// *************************************************************************** *
// *                                                                           *
// *                      Mentor Graphics Corporation                          *
// *                          All rights reserved                              *
// *                                                                           *
// *************************************************************************** *
// *                                                                           *
// * Description:         CANDB File                                           *
// * Generated at:        2025-06-23 15:14                                     *
// * System:              PP                                                   *
// * Variant:             DMH                                                  *
// * Network:             PTCANFD                                              *
// *                                                                           *
// *************************************************************************** *
// *                                                                           *
// *             THIS CONFIGURATION MIGHT CONTAIN SOME ERRORS                  *
// *              IF THE INPUT MODEL WAS NOT PROPERLY FORMED!                  *
// *                    Do Not Use this File directly!                         *
// *                                                                           *
// *************************************************************************** *
VERSION "PTCANFD"

NS_ :

BS_ :

BU_ :  BMS CCU PEU PICU TC TESTER VIU0

BO_ 1414 BMS_TSerials : 64 BMS
 SG_ BMS_CellTSync : 507|4@0+ (1.0,0.0) [0.0|14.0] "" VIU0
 SG_ BMS_SnsrT1 : 7|8@0+ (1.0,-40.0) [-40.0|125.0] "℃" VIU0
 SG_ BMS_SnsrT10 : 79|8@0+ (1.0,-40.0) [-40.0|125.0] "℃" VIU0
 SG_ BMS_SnsrT11 : 87|8@0+ (1.0,-40.0) [-40.0|125.0] "℃" VIU0
 SG_ BMS_SnsrT12 : 95|8@0+ (1.0,-40.0) [-40.0|125.0] "℃" VIU0
 SG_ BMS_SnsrT13 : 103|8@0+ (1.0,-40.0) [-40.0|125.0] "℃" VIU0
 SG_ BMS_SnsrT14 : 111|8@0+ (1.0,-40.0) [-40.0|125.0] "℃" VIU0
 SG_ BMS_SnsrT15 : 119|8@0+ (1.0,-40.0) [-40.0|125.0] "℃" VIU0
 SG_ BMS_SnsrT16 : 127|8@0+ (1.0,-40.0) [-40.0|125.0] "℃" VIU0
 SG_ BMS_SnsrT17 : 135|8@0+ (1.0,-40.0) [-40.0|125.0] "℃" VIU0
 SG_ BMS_SnsrT18 : 143|8@0+ (1.0,-40.0) [-40.0|125.0] "℃" VIU0
 SG_ BMS_SnsrT19 : 151|8@0+ (1.0,-40.0) [-40.0|125.0] "℃" VIU0
 SG_ BMS_SnsrT2 : 15|8@0+ (1.0,-40.0) [-40.0|125.0] "℃" VIU0
 SG_ BMS_SnsrT20 : 159|8@0+ (1.0,-40.0) [-40.0|125.0] "℃" VIU0
 SG_ BMS_SnsrT21 : 167|8@0+ (1.0,-40.0) [-40.0|125.0] "℃" VIU0
 SG_ BMS_SnsrT22 : 175|8@0+ (1.0,-40.0) [-40.0|125.0] "℃" VIU0
 SG_ BMS_SnsrT23 : 183|8@0+ (1.0,-40.0) [-40.0|125.0] "℃" VIU0
 SG_ BMS_SnsrT24 : 191|8@0+ (1.0,-40.0) [-40.0|125.0] "℃" VIU0
 SG_ BMS_SnsrT25 : 199|8@0+ (1.0,-40.0) [-40.0|125.0] "℃" VIU0
 SG_ BMS_SnsrT26 : 207|8@0+ (1.0,-40.0) [-40.0|125.0] "℃" VIU0
 SG_ BMS_SnsrT27 : 215|8@0+ (1.0,-40.0) [-40.0|125.0] "℃" VIU0
 SG_ BMS_SnsrT28 : 223|8@0+ (1.0,-40.0) [-40.0|125.0] "℃" VIU0
 SG_ BMS_SnsrT29 : 231|8@0+ (1.0,-40.0) [-40.0|125.0] "℃" VIU0
 SG_ BMS_SnsrT3 : 23|8@0+ (1.0,-40.0) [-40.0|125.0] "℃" VIU0
 SG_ BMS_SnsrT30 : 239|8@0+ (1.0,-40.0) [-40.0|125.0] "℃" VIU0
 SG_ BMS_SnsrT31 : 247|8@0+ (1.0,-40.0) [-40.0|125.0] "℃" VIU0
 SG_ BMS_SnsrT32 : 255|8@0+ (1.0,-40.0) [-40.0|125.0] "℃" VIU0
 SG_ BMS_SnsrT33 : 263|8@0+ (1.0,-40.0) [-40.0|125.0] "℃" VIU0
 SG_ BMS_SnsrT34 : 271|8@0+ (1.0,-40.0) [-40.0|125.0] "℃" VIU0
 SG_ BMS_SnsrT35 : 279|8@0+ (1.0,-40.0) [-40.0|125.0] "℃" VIU0
 SG_ BMS_SnsrT36 : 287|8@0+ (1.0,-40.0) [-40.0|125.0] "℃" VIU0
 SG_ BMS_SnsrT37 : 295|8@0+ (1.0,-40.0) [-40.0|125.0] "℃" VIU0
 SG_ BMS_SnsrT38 : 303|8@0+ (1.0,-40.0) [-40.0|125.0] "℃" VIU0
 SG_ BMS_SnsrT39 : 311|8@0+ (1.0,-40.0) [-40.0|125.0] "℃" VIU0
 SG_ BMS_SnsrT4 : 31|8@0+ (1.0,-40.0) [-40.0|125.0] "℃" VIU0
 SG_ BMS_SnsrT40 : 319|8@0+ (1.0,-40.0) [-40.0|125.0] "℃" VIU0
 SG_ BMS_SnsrT41 : 327|8@0+ (1.0,-40.0) [-40.0|125.0] "℃" VIU0
 SG_ BMS_SnsrT42 : 335|8@0+ (1.0,-40.0) [-40.0|125.0] "℃" VIU0
 SG_ BMS_SnsrT43 : 343|8@0+ (1.0,-40.0) [-40.0|125.0] "℃" VIU0
 SG_ BMS_SnsrT44 : 351|8@0+ (1.0,-40.0) [-40.0|125.0] "℃" VIU0
 SG_ BMS_SnsrT45 : 359|8@0+ (1.0,-40.0) [-40.0|125.0] "℃" VIU0
 SG_ BMS_SnsrT46 : 367|8@0+ (1.0,-40.0) [-40.0|125.0] "℃" VIU0
 SG_ BMS_SnsrT47 : 375|8@0+ (1.0,-40.0) [-40.0|125.0] "℃" VIU0
 SG_ BMS_SnsrT48 : 383|8@0+ (1.0,-40.0) [-40.0|125.0] "℃" VIU0
 SG_ BMS_SnsrT49 : 391|8@0+ (1.0,-40.0) [-40.0|125.0] "℃" VIU0
 SG_ BMS_SnsrT5 : 39|8@0+ (1.0,-40.0) [-40.0|125.0] "℃" VIU0
 SG_ BMS_SnsrT50 : 399|8@0+ (1.0,-40.0) [-40.0|125.0] "℃" VIU0
 SG_ BMS_SnsrT51 : 407|8@0+ (1.0,-40.0) [-40.0|125.0] "℃" VIU0
 SG_ BMS_SnsrT52 : 415|8@0+ (1.0,-40.0) [-40.0|125.0] "℃" VIU0
 SG_ BMS_SnsrT53 : 423|8@0+ (1.0,-40.0) [-40.0|125.0] "℃" VIU0
 SG_ BMS_SnsrT54 : 431|8@0+ (1.0,-40.0) [-40.0|125.0] "℃" VIU0
 SG_ BMS_SnsrT55 : 439|8@0+ (1.0,-40.0) [-40.0|125.0] "℃" VIU0
 SG_ BMS_SnsrT56 : 447|8@0+ (1.0,-40.0) [-40.0|125.0] "℃" VIU0
 SG_ BMS_SnsrT57 : 455|8@0+ (1.0,-40.0) [-40.0|125.0] "℃" VIU0
 SG_ BMS_SnsrT58 : 463|8@0+ (1.0,-40.0) [-40.0|125.0] "℃" VIU0
 SG_ BMS_SnsrT59 : 471|8@0+ (1.0,-40.0) [-40.0|125.0] "℃" VIU0
 SG_ BMS_SnsrT6 : 47|8@0+ (1.0,-40.0) [-40.0|125.0] "℃" VIU0
 SG_ BMS_SnsrT60 : 479|8@0+ (1.0,-40.0) [-40.0|125.0] "℃" VIU0
 SG_ BMS_SnsrT61 : 487|8@0+ (1.0,-40.0) [-40.0|125.0] "℃" VIU0
 SG_ BMS_SnsrT62 : 495|8@0+ (1.0,-40.0) [-40.0|125.0] "℃" VIU0
 SG_ BMS_SnsrT63 : 503|8@0+ (1.0,-40.0) [-40.0|125.0] "℃" VIU0
 SG_ BMS_SnsrT7 : 55|8@0+ (1.0,-40.0) [-40.0|125.0] "℃" VIU0
 SG_ BMS_SnsrT8 : 63|8@0+ (1.0,-40.0) [-40.0|125.0] "℃" VIU0
 SG_ BMS_SnsrT9 : 71|8@0+ (1.0,-40.0) [-40.0|125.0] "℃" VIU0

BO_ 1457 BMS_Version : 32 BMS
 SG_ BMS_CanMatrixMajorVersion : 79|8@0+ (1.0,0.0) [0.0|255.0] "" TESTER
 SG_ BMS_CanMatrixMinorVersion : 87|8@0+ (1.0,0.0) [0.0|255.0] "" TESTER
 SG_ BMS_CanMatrixPatchVersion : 95|8@0+ (1.0,0.0) [0.0|255.0] "" TESTER
 SG_ BMS_CellPrmTblMajorVersion : 103|8@0+ (1.0,0.0) [0.0|255.0] "" TESTER
 SG_ BMS_CellPrmTblMinorVersion : 111|8@0+ (1.0,0.0) [0.0|255.0] "" TESTER
 SG_ BMS_CellPrmTblPatchVersion : 119|8@0+ (1.0,0.0) [0.0|255.0] "" TESTER
 SG_ BMS_FltDiagTblMajorVersion : 127|8@0+ (1.0,0.0) [0.0|255.0] "" TESTER
 SG_ BMS_FltDiagTblMinorVersion : 135|8@0+ (1.0,0.0) [0.0|255.0] "" TESTER
 SG_ BMS_FltDiagTblPatchVersion : 143|8@0+ (1.0,0.0) [0.0|255.0] "" TESTER
 SG_ BMS_HwVersion : 23|8@0+ (1.0,0.0) [0.0|255.0] "" TESTER
 SG_ BMS_SupplierCode : 7|16@0+ (1.0,0.0) [0.0|65535.0] "" TESTER
 SG_ BMS_SwMajorVersion : 31|8@0+ (1.0,0.0) [0.0|255.0] "" TESTER
 SG_ BMS_SwMinorVersion : 39|8@0+ (1.0,0.0) [0.0|255.0] "" TESTER
 SG_ BMS_SwPatchVersion : 47|8@0+ (1.0,0.0) [0.0|255.0] "" TESTER
 SG_ BMS_SwVersionDay : 71|8@0+ (1.0,0.0) [0.0|31.0] "" TESTER
 SG_ BMS_SwVersionMonth : 63|8@0+ (1.0,0.0) [0.0|12.0] "" TESTER
 SG_ BMS_SwVersionYear : 55|8@0+ (1.0,0.0) [0.0|255.0] "" TESTER

BO_ 1409 BMS_VoltSerials1 : 64 BMS
 SG_ BMS_CellU1 : 7|13@0+ (0.001,0.0) [0.0|5.0] "V" VIU0
 SG_ BMS_CellU10 : 114|13@0+ (0.001,0.0) [0.0|5.0] "V" VIU0
 SG_ BMS_CellU11 : 133|13@0+ (0.001,0.0) [0.0|5.0] "V" VIU0
 SG_ BMS_CellU12 : 136|13@0+ (0.001,0.0) [0.0|5.0] "V" VIU0
 SG_ BMS_CellU13 : 155|13@0+ (0.001,0.0) [0.0|5.0] "V" VIU0
 SG_ BMS_CellU14 : 174|13@0+ (0.001,0.0) [0.0|5.0] "V" VIU0
 SG_ BMS_CellU15 : 177|13@0+ (0.001,0.0) [0.0|5.0] "V" VIU0
 SG_ BMS_CellU16 : 196|13@0+ (0.001,0.0) [0.0|5.0] "V" VIU0
 SG_ BMS_CellU17 : 215|13@0+ (0.001,0.0) [0.0|5.0] "V" VIU0
 SG_ BMS_CellU18 : 218|13@0+ (0.001,0.0) [0.0|5.0] "V" VIU0
 SG_ BMS_CellU19 : 237|13@0+ (0.001,0.0) [0.0|5.0] "V" VIU0
 SG_ BMS_CellU2 : 10|13@0+ (0.001,0.0) [0.0|5.0] "V" VIU0
 SG_ BMS_CellU20 : 240|13@0+ (0.001,0.0) [0.0|5.0] "V" VIU0
 SG_ BMS_CellU21 : 259|13@0+ (0.001,0.0) [0.0|5.0] "V" VIU0
 SG_ BMS_CellU22 : 278|13@0+ (0.001,0.0) [0.0|5.0] "V" VIU0
 SG_ BMS_CellU23 : 281|13@0+ (0.001,0.0) [0.0|5.0] "V" VIU0
 SG_ BMS_CellU24 : 300|13@0+ (0.001,0.0) [0.0|5.0] "V" VIU0
 SG_ BMS_CellU25 : 319|13@0+ (0.001,0.0) [0.0|5.0] "V" VIU0
 SG_ BMS_CellU26 : 322|13@0+ (0.001,0.0) [0.0|5.0] "V" VIU0
 SG_ BMS_CellU27 : 341|13@0+ (0.001,0.0) [0.0|5.0] "V" VIU0
 SG_ BMS_CellU28 : 344|13@0+ (0.001,0.0) [0.0|5.0] "V" VIU0
 SG_ BMS_CellU29 : 363|13@0+ (0.001,0.0) [0.0|5.0] "V" VIU0
 SG_ BMS_CellU3 : 29|13@0+ (0.001,0.0) [0.0|5.0] "V" VIU0
 SG_ BMS_CellU30 : 382|13@0+ (0.001,0.0) [0.0|5.0] "V" VIU0
 SG_ BMS_CellU31 : 385|13@0+ (0.001,0.0) [0.0|5.0] "V" VIU0
 SG_ BMS_CellU32 : 404|13@0+ (0.001,0.0) [0.0|5.0] "V" VIU0
 SG_ BMS_CellU33 : 423|13@0+ (0.001,0.0) [0.0|5.0] "V" VIU0
 SG_ BMS_CellU34 : 426|13@0+ (0.001,0.0) [0.0|5.0] "V" VIU0
 SG_ BMS_CellU35 : 445|13@0+ (0.001,0.0) [0.0|5.0] "V" VIU0
 SG_ BMS_CellU36 : 448|13@0+ (0.001,0.0) [0.0|5.0] "V" VIU0
 SG_ BMS_CellU37 : 467|13@0+ (0.001,0.0) [0.0|5.0] "V" VIU0
 SG_ BMS_CellU38 : 486|13@0+ (0.001,0.0) [0.0|5.0] "V" VIU0
 SG_ BMS_CellU39 : 489|13@0+ (0.001,0.0) [0.0|5.0] "V" VIU0
 SG_ BMS_CellU4 : 32|13@0+ (0.001,0.0) [0.0|5.0] "V" VIU0
 SG_ BMS_CellU5 : 51|13@0+ (0.001,0.0) [0.0|5.0] "V" VIU0
 SG_ BMS_CellU6 : 70|13@0+ (0.001,0.0) [0.0|5.0] "V" VIU0
 SG_ BMS_CellU7 : 73|13@0+ (0.001,0.0) [0.0|5.0] "V" VIU0
 SG_ BMS_CellU8 : 92|13@0+ (0.001,0.0) [0.0|5.0] "V" VIU0
 SG_ BMS_CellU9 : 111|13@0+ (0.001,0.0) [0.0|5.0] "V" VIU0
 SG_ BMS_CellUSync1 : 507|4@0+ (1.0,0.0) [0.0|14.0] "" VIU0

BO_ 1410 BMS_VoltSerials2 : 64 BMS
 SG_ BMS_CellU40 : 7|13@0+ (0.001,0.0) [0.0|5.0] "V" VIU0
 SG_ BMS_CellU41 : 10|13@0+ (0.001,0.0) [0.0|5.0] "V" VIU0
 SG_ BMS_CellU42 : 29|13@0+ (0.001,0.0) [0.0|5.0] "V" VIU0
 SG_ BMS_CellU43 : 32|13@0+ (0.001,0.0) [0.0|5.0] "V" VIU0
 SG_ BMS_CellU44 : 51|13@0+ (0.001,0.0) [0.0|5.0] "V" VIU0
 SG_ BMS_CellU45 : 70|13@0+ (0.001,0.0) [0.0|5.0] "V" VIU0
 SG_ BMS_CellU46 : 73|13@0+ (0.001,0.0) [0.0|5.0] "V" VIU0
 SG_ BMS_CellU47 : 92|13@0+ (0.001,0.0) [0.0|5.0] "V" VIU0
 SG_ BMS_CellU48 : 111|13@0+ (0.001,0.0) [0.0|5.0] "V" VIU0
 SG_ BMS_CellU49 : 114|13@0+ (0.001,0.0) [0.0|5.0] "V" VIU0
 SG_ BMS_CellU50 : 133|13@0+ (0.001,0.0) [0.0|5.0] "V" VIU0
 SG_ BMS_CellU51 : 136|13@0+ (0.001,0.0) [0.0|5.0] "V" VIU0
 SG_ BMS_CellU52 : 155|13@0+ (0.001,0.0) [0.0|5.0] "V" VIU0
 SG_ BMS_CellU53 : 174|13@0+ (0.001,0.0) [0.0|5.0] "V" VIU0
 SG_ BMS_CellU54 : 177|13@0+ (0.001,0.0) [0.0|5.0] "V" VIU0
 SG_ BMS_CellU55 : 196|13@0+ (0.001,0.0) [0.0|5.0] "V" VIU0
 SG_ BMS_CellU56 : 215|13@0+ (0.001,0.0) [0.0|5.0] "V" VIU0
 SG_ BMS_CellU57 : 218|13@0+ (0.001,0.0) [0.0|5.0] "V" VIU0
 SG_ BMS_CellU58 : 237|13@0+ (0.001,0.0) [0.0|5.0] "V" VIU0
 SG_ BMS_CellU59 : 240|13@0+ (0.001,0.0) [0.0|5.0] "V" VIU0
 SG_ BMS_CellU60 : 259|13@0+ (0.001,0.0) [0.0|5.0] "V" VIU0
 SG_ BMS_CellU61 : 278|13@0+ (0.001,0.0) [0.0|5.0] "V" VIU0
 SG_ BMS_CellU62 : 281|13@0+ (0.001,0.0) [0.0|5.0] "V" VIU0
 SG_ BMS_CellU63 : 300|13@0+ (0.001,0.0) [0.0|5.0] "V" VIU0
 SG_ BMS_CellU64 : 319|13@0+ (0.001,0.0) [0.0|5.0] "V" VIU0
 SG_ BMS_CellU65 : 322|13@0+ (0.001,0.0) [0.0|5.0] "V" VIU0
 SG_ BMS_CellU66 : 341|13@0+ (0.001,0.0) [0.0|5.0] "V" VIU0
 SG_ BMS_CellU67 : 344|13@0+ (0.001,0.0) [0.0|5.0] "V" VIU0
 SG_ BMS_CellU68 : 363|13@0+ (0.001,0.0) [0.0|5.0] "V" VIU0
 SG_ BMS_CellU69 : 382|13@0+ (0.001,0.0) [0.0|5.0] "V" VIU0
 SG_ BMS_CellU70 : 385|13@0+ (0.001,0.0) [0.0|5.0] "V" VIU0
 SG_ BMS_CellU71 : 404|13@0+ (0.001,0.0) [0.0|5.0] "V" VIU0
 SG_ BMS_CellU72 : 423|13@0+ (0.001,0.0) [0.0|5.0] "V" VIU0
 SG_ BMS_CellU73 : 426|13@0+ (0.001,0.0) [0.0|5.0] "V" VIU0
 SG_ BMS_CellU74 : 445|13@0+ (0.001,0.0) [0.0|5.0] "V" VIU0
 SG_ BMS_CellU75 : 448|13@0+ (0.001,0.0) [0.0|5.0] "V" VIU0
 SG_ BMS_CellU76 : 467|13@0+ (0.001,0.0) [0.0|5.0] "V" VIU0
 SG_ BMS_CellU77 : 486|13@0+ (0.001,0.0) [0.0|5.0] "V" VIU0
 SG_ BMS_CellU78 : 489|13@0+ (0.001,0.0) [0.0|5.0] "V" VIU0
 SG_ BMS_CellUSync2 : 507|4@0+ (1.0,0.0) [0.0|14.0] "" VIU0

BO_ 1411 BMS_VoltSerials3 : 64 BMS
 SG_ BMS_CellU100 : 278|13@0+ (0.001,0.0) [0.0|5.0] "V" VIU0
 SG_ BMS_CellU101 : 281|13@0+ (0.001,0.0) [0.0|5.0] "V" VIU0
 SG_ BMS_CellU102 : 300|13@0+ (0.001,0.0) [0.0|5.0] "V" VIU0
 SG_ BMS_CellU103 : 319|13@0+ (0.001,0.0) [0.0|5.0] "V" VIU0
 SG_ BMS_CellU104 : 322|13@0+ (0.001,0.0) [0.0|5.0] "V" VIU0
 SG_ BMS_CellU105 : 341|13@0+ (0.001,0.0) [0.0|5.0] "V" VIU0
 SG_ BMS_CellU106 : 344|13@0+ (0.001,0.0) [0.0|5.0] "V" VIU0
 SG_ BMS_CellU107 : 363|13@0+ (0.001,0.0) [0.0|5.0] "V" VIU0
 SG_ BMS_CellU108 : 382|13@0+ (0.001,0.0) [0.0|5.0] "V" VIU0
 SG_ BMS_CellU109 : 385|13@0+ (0.001,0.0) [0.0|5.0] "V" VIU0
 SG_ BMS_CellU110 : 404|13@0+ (0.001,0.0) [0.0|5.0] "V" VIU0
 SG_ BMS_CellU111 : 423|13@0+ (0.001,0.0) [0.0|5.0] "V" VIU0
 SG_ BMS_CellU112 : 426|13@0+ (0.001,0.0) [0.0|5.0] "V" VIU0
 SG_ BMS_CellU113 : 445|13@0+ (0.001,0.0) [0.0|5.0] "V" VIU0
 SG_ BMS_CellU114 : 448|13@0+ (0.001,0.0) [0.0|5.0] "V" VIU0
 SG_ BMS_CellU115 : 467|13@0+ (0.001,0.0) [0.0|5.0] "V" VIU0
 SG_ BMS_CellU116 : 486|13@0+ (0.001,0.0) [0.0|5.0] "V" VIU0
 SG_ BMS_CellU117 : 489|13@0+ (0.001,0.0) [0.0|5.0] "V" VIU0
 SG_ BMS_CellU79 : 7|13@0+ (0.001,0.0) [0.0|5.0] "V" VIU0
 SG_ BMS_CellU80 : 10|13@0+ (0.001,0.0) [0.0|5.0] "V" VIU0
 SG_ BMS_CellU81 : 29|13@0+ (0.001,0.0) [0.0|5.0] "V" VIU0
 SG_ BMS_CellU82 : 32|13@0+ (0.001,0.0) [0.0|5.0] "V" VIU0
 SG_ BMS_CellU83 : 51|13@0+ (0.001,0.0) [0.0|5.0] "V" VIU0
 SG_ BMS_CellU84 : 70|13@0+ (0.001,0.0) [0.0|5.0] "V" VIU0
 SG_ BMS_CellU85 : 73|13@0+ (0.001,0.0) [0.0|5.0] "V" VIU0
 SG_ BMS_CellU86 : 92|13@0+ (0.001,0.0) [0.0|5.0] "V" VIU0
 SG_ BMS_CellU87 : 111|13@0+ (0.001,0.0) [0.0|5.0] "V" VIU0
 SG_ BMS_CellU88 : 114|13@0+ (0.001,0.0) [0.0|5.0] "V" VIU0
 SG_ BMS_CellU89 : 133|13@0+ (0.001,0.0) [0.0|5.0] "V" VIU0
 SG_ BMS_CellU90 : 136|13@0+ (0.001,0.0) [0.0|5.0] "V" VIU0
 SG_ BMS_CellU91 : 155|13@0+ (0.001,0.0) [0.0|5.0] "V" VIU0
 SG_ BMS_CellU92 : 174|13@0+ (0.001,0.0) [0.0|5.0] "V" VIU0
 SG_ BMS_CellU93 : 177|13@0+ (0.001,0.0) [0.0|5.0] "V" VIU0
 SG_ BMS_CellU94 : 196|13@0+ (0.001,0.0) [0.0|5.0] "V" VIU0
 SG_ BMS_CellU95 : 215|13@0+ (0.001,0.0) [0.0|5.0] "V" VIU0
 SG_ BMS_CellU96 : 218|13@0+ (0.001,0.0) [0.0|5.0] "V" VIU0
 SG_ BMS_CellU97 : 237|13@0+ (0.001,0.0) [0.0|5.0] "V" VIU0
 SG_ BMS_CellU98 : 240|13@0+ (0.001,0.0) [0.0|5.0] "V" VIU0
 SG_ BMS_CellU99 : 259|13@0+ (0.001,0.0) [0.0|5.0] "V" VIU0
 SG_ BMS_CellUSync3 : 507|4@0+ (1.0,0.0) [0.0|14.0] "" VIU0

BO_ 1412 BMS_VoltSerials4 : 64 BMS
 SG_ BMS_CellU118 : 7|13@0+ (0.001,0.0) [0.0|5.0] "V" VIU0
 SG_ BMS_CellU119 : 10|13@0+ (0.001,0.0) [0.0|5.0] "V" VIU0
 SG_ BMS_CellU120 : 29|13@0+ (0.001,0.0) [0.0|5.0] "V" VIU0
 SG_ BMS_CellU121 : 32|13@0+ (0.001,0.0) [0.0|5.0] "V" VIU0
 SG_ BMS_CellU122 : 51|13@0+ (0.001,0.0) [0.0|5.0] "V" VIU0
 SG_ BMS_CellU123 : 70|13@0+ (0.001,0.0) [0.0|5.0] "V" VIU0
 SG_ BMS_CellU124 : 73|13@0+ (0.001,0.0) [0.0|5.0] "V" VIU0
 SG_ BMS_CellU125 : 92|13@0+ (0.001,0.0) [0.0|5.0] "V" VIU0
 SG_ BMS_CellU126 : 111|13@0+ (0.001,0.0) [0.0|5.0] "V" VIU0
 SG_ BMS_CellU127 : 114|13@0+ (0.001,0.0) [0.0|5.0] "V" VIU0
 SG_ BMS_CellU128 : 133|13@0+ (0.001,0.0) [0.0|5.0] "V" VIU0
 SG_ BMS_CellU129 : 136|13@0+ (0.001,0.0) [0.0|5.0] "V" VIU0
 SG_ BMS_CellU130 : 155|13@0+ (0.001,0.0) [0.0|5.0] "V" VIU0
 SG_ BMS_CellU131 : 174|13@0+ (0.001,0.0) [0.0|5.0] "V" VIU0
 SG_ BMS_CellU132 : 177|13@0+ (0.001,0.0) [0.0|5.0] "V" VIU0
 SG_ BMS_CellU133 : 196|13@0+ (0.001,0.0) [0.0|5.0] "V" VIU0
 SG_ BMS_CellU134 : 215|13@0+ (0.001,0.0) [0.0|5.0] "V" VIU0
 SG_ BMS_CellU135 : 218|13@0+ (0.001,0.0) [0.0|5.0] "V" VIU0
 SG_ BMS_CellU136 : 237|13@0+ (0.001,0.0) [0.0|5.0] "V" VIU0
 SG_ BMS_CellU137 : 240|13@0+ (0.001,0.0) [0.0|5.0] "V" VIU0
 SG_ BMS_CellU138 : 259|13@0+ (0.001,0.0) [0.0|5.0] "V" VIU0
 SG_ BMS_CellU139 : 278|13@0+ (0.001,0.0) [0.0|5.0] "V" VIU0
 SG_ BMS_CellU140 : 281|13@0+ (0.001,0.0) [0.0|5.0] "V" VIU0
 SG_ BMS_CellU141 : 300|13@0+ (0.001,0.0) [0.0|5.0] "V" VIU0
 SG_ BMS_CellU142 : 319|13@0+ (0.001,0.0) [0.0|5.0] "V" VIU0
 SG_ BMS_CellU143 : 322|13@0+ (0.001,0.0) [0.0|5.0] "V" VIU0
 SG_ BMS_CellU144 : 341|13@0+ (0.001,0.0) [0.0|5.0] "V" VIU0
 SG_ BMS_CellU145 : 344|13@0+ (0.001,0.0) [0.0|5.0] "V" VIU0
 SG_ BMS_CellU146 : 363|13@0+ (0.001,0.0) [0.0|5.0] "V" VIU0
 SG_ BMS_CellU147 : 382|13@0+ (0.001,0.0) [0.0|5.0] "V" VIU0
 SG_ BMS_CellU148 : 385|13@0+ (0.001,0.0) [0.0|5.0] "V" VIU0
 SG_ BMS_CellU149 : 404|13@0+ (0.001,0.0) [0.0|5.0] "V" VIU0
 SG_ BMS_CellU150 : 423|13@0+ (0.001,0.0) [0.0|5.0] "V" VIU0
 SG_ BMS_CellU151 : 426|13@0+ (0.001,0.0) [0.0|5.0] "V" VIU0
 SG_ BMS_CellU152 : 445|13@0+ (0.001,0.0) [0.0|5.0] "V" VIU0
 SG_ BMS_CellU153 : 448|13@0+ (0.001,0.0) [0.0|5.0] "V" VIU0
 SG_ BMS_CellU154 : 467|13@0+ (0.001,0.0) [0.0|5.0] "V" VIU0
 SG_ BMS_CellU155 : 486|13@0+ (0.001,0.0) [0.0|5.0] "V" VIU0
 SG_ BMS_CellU156 : 489|13@0+ (0.001,0.0) [0.0|5.0] "V" VIU0
 SG_ BMS_CellUSync4 : 507|4@0+ (1.0,0.0) [0.0|14.0] "" VIU0

BO_ 1413 BMS_VoltSerials5 : 64 BMS
 SG_ BMS_CellU157 : 7|13@0+ (0.001,0.0) [0.0|5.0] "V" VIU0
 SG_ BMS_CellU158 : 10|13@0+ (0.001,0.0) [0.0|5.0] "V" VIU0
 SG_ BMS_CellU159 : 29|13@0+ (0.001,0.0) [0.0|5.0] "V" VIU0
 SG_ BMS_CellU160 : 32|13@0+ (0.001,0.0) [0.0|5.0] "V" VIU0
 SG_ BMS_CellU161 : 51|13@0+ (0.001,0.0) [0.0|5.0] "V" VIU0
 SG_ BMS_CellU162 : 70|13@0+ (0.001,0.0) [0.0|5.0] "V" VIU0
 SG_ BMS_CellU163 : 73|13@0+ (0.001,0.0) [0.0|5.0] "V" VIU0
 SG_ BMS_CellU164 : 92|13@0+ (0.001,0.0) [0.0|5.0] "V" VIU0
 SG_ BMS_CellU165 : 111|13@0+ (0.001,0.0) [0.0|5.0] "V" VIU0
 SG_ BMS_CellU166 : 114|13@0+ (0.001,0.0) [0.0|5.0] "V" VIU0
 SG_ BMS_CellU167 : 133|13@0+ (0.001,0.0) [0.0|5.0] "V" VIU0
 SG_ BMS_CellU168 : 136|13@0+ (0.001,0.0) [0.0|5.0] "V" VIU0
 SG_ BMS_CellU169 : 155|13@0+ (0.001,0.0) [0.0|5.0] "V" VIU0
 SG_ BMS_CellU170 : 174|13@0+ (0.001,0.0) [0.0|5.0] "V" VIU0
 SG_ BMS_CellU171 : 177|13@0+ (0.001,0.0) [0.0|5.0] "V" VIU0
 SG_ BMS_CellU172 : 196|13@0+ (0.001,0.0) [0.0|5.0] "V" VIU0
 SG_ BMS_CellU173 : 215|13@0+ (0.001,0.0) [0.0|5.0] "V" VIU0
 SG_ BMS_CellU174 : 218|13@0+ (0.001,0.0) [0.0|5.0] "V" VIU0
 SG_ BMS_CellU175 : 237|13@0+ (0.001,0.0) [0.0|5.0] "V" VIU0
 SG_ BMS_CellU176 : 240|13@0+ (0.001,0.0) [0.0|5.0] "V" VIU0
 SG_ BMS_CellU177 : 259|13@0+ (0.001,0.0) [0.0|5.0] "V" VIU0
 SG_ BMS_CellU178 : 278|13@0+ (0.001,0.0) [0.0|5.0] "V" VIU0
 SG_ BMS_CellU179 : 281|13@0+ (0.001,0.0) [0.0|5.0] "V" VIU0
 SG_ BMS_CellU180 : 300|13@0+ (0.001,0.0) [0.0|5.0] "V" VIU0
 SG_ BMS_CellU181 : 319|13@0+ (0.001,0.0) [0.0|5.0] "V" VIU0
 SG_ BMS_CellU182 : 322|13@0+ (0.001,0.0) [0.0|5.0] "V" VIU0
 SG_ BMS_CellU183 : 341|13@0+ (0.001,0.0) [0.0|5.0] "V" VIU0
 SG_ BMS_CellU184 : 344|13@0+ (0.001,0.0) [0.0|5.0] "V" VIU0
 SG_ BMS_CellU185 : 363|13@0+ (0.001,0.0) [0.0|5.0] "V" VIU0
 SG_ BMS_CellU186 : 382|13@0+ (0.001,0.0) [0.0|5.0] "V" VIU0
 SG_ BMS_CellU187 : 385|13@0+ (0.001,0.0) [0.0|5.0] "V" VIU0
 SG_ BMS_CellU188 : 404|13@0+ (0.001,0.0) [0.0|5.0] "V" VIU0
 SG_ BMS_CellU189 : 423|13@0+ (0.001,0.0) [0.0|5.0] "V" VIU0
 SG_ BMS_CellU190 : 426|13@0+ (0.001,0.0) [0.0|5.0] "V" VIU0
 SG_ BMS_CellU191 : 445|13@0+ (0.001,0.0) [0.0|5.0] "V" VIU0
 SG_ BMS_CellU192 : 448|13@0+ (0.001,0.0) [0.0|5.0] "V" VIU0
 SG_ BMS_CellUSync5 : 507|4@0+ (1.0,0.0) [0.0|14.0] "" VIU0

BO_ 1418 CDU_APS_State : 32 CCU
 SG_ CDU_APS_PortA_Currt1 : 109|14@0+ (0.1,-500.0) [-500.0|1138.3000000000002] "A" VIU0
 SG_ CDU_APS_PortA_Currt2 : 133|14@0+ (0.1,-500.0) [-500.0|1138.3000000000002] "A" VIU0
 SG_ CDU_APS_PortA_Currt3 : 199|14@0+ (0.1,-500.0) [-500.0|1138.3000000000002] "A" VIU0
 SG_ CDU_APS_PortA_U1 : 103|10@0+ (0.05,0.0) [0.0|51.150000000000006] "V" VIU0
 SG_ CDU_APS_PortA_U2 : 127|10@0+ (0.05,0.0) [0.0|51.150000000000006] "V" VIU0
 SG_ CDU_APS_PortB_Currt_DCDC : 157|14@0+ (0.1,-500.0) [-500.0|1138.3000000000002] "A" VIU0
 SG_ CDU_APS_PortB_Currt_Sfty : 181|14@0+ (0.1,-500.0) [-500.0|1138.3000000000002] "A" VIU0
 SG_ CDU_APS_PortB_U1 : 151|10@0+ (0.05,0.0) [0.0|51.150000000000006] "V" VIU0
 SG_ CDU_APS_PortB_U2 : 175|10@0+ (0.05,0.0) [0.0|51.150000000000006] "V" VIU0
 SG_ CDU_APS_SIGN : 201|1@0+ (1,0) [0|1] "" VIU0
 SG_ CDU_DetailedFltInfo : 71|32@0+ (1.0,0.0) [0.0|4294967295.0] "" VIU0

BO_ 787 CDU_DCDC : 32 CCU
 SG_ CDU_DCDC_Checksum : 7|16@0+ (1.0,0.0) [0.0|65535.0] "" BMS,VIU0
 SG_ CDU_DCDC_Counter : 23|8@0+ (1.0,0.0) [0.0|255.0] "" BMS,VIU0
 SG_ DCDC_AlerSt : 122|1@0+ (1,0) [0|1] "" VIU0
 SG_ DCDC_CopntTemp : 191|8@0+ (1.0,-48.0) [-48.0|206.0] "℃" PICU
 SG_ DCDC_DeratFlag : 113|1@0+ (1,0) [0|1] "" VIU0
 SG_ DCDC_DeratReason1 : 200|1@0+ (1,0) [0|1] "" TESTER
 SG_ DCDC_DeratReason10 : 213|1@0+ (1,0) [0|1] "" TESTER
 SG_ DCDC_DeratReason11 : 214|1@0+ (1,0) [0|1] "" TESTER
 SG_ DCDC_DeratReason12 : 215|1@0+ (1,0) [0|1] "" TESTER
 SG_ DCDC_DeratReason2 : 201|1@0+ (1,0) [0|1] "" TESTER
 SG_ DCDC_DeratReason3 : 202|1@0+ (1,0) [0|1] "" TESTER
 SG_ DCDC_DeratReason4 : 203|1@0+ (1,0) [0|1] "" TESTER
 SG_ DCDC_DeratReason5 : 204|1@0+ (1,0) [0|1] "" TESTER
 SG_ DCDC_DeratReason6 : 205|1@0+ (1,0) [0|1] "" TESTER
 SG_ DCDC_DeratReason7 : 206|1@0+ (1,0) [0|1] "" TESTER
 SG_ DCDC_DeratReason8 : 207|1@0+ (1,0) [0|1] "" TESTER
 SG_ DCDC_DeratReason9 : 212|1@0+ (1,0) [0|1] "" TESTER
 SG_ DCDC_EnergyConvrtDir : 87|1@0+ (1,0) [0|1] "" TESTER
 SG_ DCDC_FaultLevel : 52|3@0+ (1,0) [0|7] "" VIU0
 SG_ DCDC_FaultLightReq : 112|1@0+ (1,0) [0|1] "" TESTER
 SG_ DCDC_FlowReq : 117|4@0+ (1,0) [0|15] "" PICU
 SG_ DCDC_HVIL_48VDCDC_St : 47|2@0+ (1,0) [0|3] "" TESTER
 SG_ DCDC_HVIL_Batt_St : 35|2@0+ (1,0) [0|3] "" PICU,VIU0
 SG_ DCDC_HVIL_EAS_St : 41|2@0+ (1,0) [0|3] "" PICU,VIU0
 SG_ DCDC_HVIL_MCU_St : 43|2@0+ (1,0) [0|3] "" PICU,VIU0
 SG_ DCDC_HVIL_PTC_St : 33|2@0+ (1,0) [0|3] "" PICU,VIU0
 SG_ DCDC_HVIL_PTCR_St : 45|2@0+ (1,0) [0|3] "" PICU,VIU0
 SG_ DCDC_InpWtrTemp : 103|8@0+ (1.0,-48.0) [-48.0|207.0] "℃" PICU
 SG_ DCDC_IptCurrt : 152|9@0+ (0.1,0.0) [0.0|51.1] "A" BMS,VIU0
 SG_ DCDC_IptVolt : 85|14@0+ (0.1,0.0) [0.0|1638.3000000000002] "V" BMS,PEU,TC,VIU0
 SG_ DCDC_LoopOut : 231|10@0+ (0.1,0.0) [0.0|102.30000000000001] "%" TESTER
 SG_ DCDC_LvSidePwr : 151|10@0+ (0.01,0.0) [0.0|10.23] "kw" TESTER
 SG_ DCDC_MaxOptPwr : 111|10@0+ (0.01,0.0) [0.0|10.23] "kw" VIU0
 SG_ DCDC_NoLoadCurrtFlag : 126|3@0+ (1,0) [0|7] "" VIU0
 SG_ DCDC_OperSt : 55|3@0+ (1,0) [0|7] "" PICU,VIU0
 SG_ DCDC_OptCurrt : 31|12@0+ (0.1,0.0) [0.0|409.5] "A" VIU0
 SG_ DCDC_OptVolt : 49|10@0+ (0.05,0.0) [0.0|51.150000000000006] "V" VIU0
 SG_ DCDC_Oring_APS_Temp : 223|8@0+ (1.0,-48.0) [-48.0|205.0] "℃" TESTER
 SG_ DCDC_OutWtrTemp : 199|8@0+ (1.0,-48.0) [-48.0|207.0] "℃" TESTER
 SG_ DCDC_OverTemp : 123|1@0+ (1,0) [0|1] "" VIU0
 SG_ DCDC_PeakPwrTi : 175|12@0+ (1.0,0.0) [0.0|3600.0] "S" VIU0
 SG_ DCDC_PNGSt : 121|2@0+ (1,0) [0|3] "" VIU0

BO_ 1306 CDU_Fault : 32 CCU
 SG_ CDU_FaultNum1 : 23|12@0+ (1.0,0.0) [0.0|4095.0] "" BMS,VIU0
 SG_ CDU_FaultNum10 : 123|12@0+ (1.0,0.0) [0.0|4095.0] "" BMS,VIU0
 SG_ CDU_FaultNum11 : 143|12@0+ (1.0,0.0) [0.0|4095.0] "" BMS,VIU0
 SG_ CDU_FaultNum12 : 147|12@0+ (1.0,0.0) [0.0|4095.0] "" BMS,VIU0
 SG_ CDU_FaultNum13 : 167|12@0+ (1.0,0.0) [0.0|4095.0] "" BMS,VIU0
 SG_ CDU_FaultNum14 : 171|12@0+ (1.0,0.0) [0.0|4095.0] "" BMS,VIU0
 SG_ CDU_FaultNum15 : 191|12@0+ (1.0,0.0) [0.0|4095.0] "" BMS,VIU0
 SG_ CDU_FaultNum16 : 195|12@0+ (1.0,0.0) [0.0|4095.0] "" BMS,VIU0
 SG_ CDU_FaultNum17 : 215|12@0+ (1.0,0.0) [0.0|4095.0] "" BMS,VIU0
 SG_ CDU_FaultNum18 : 219|12@0+ (1.0,0.0) [0.0|4095.0] "" BMS,VIU0
 SG_ CDU_FaultNum19 : 239|12@0+ (1.0,0.0) [0.0|4095.0] "" BMS,VIU0
 SG_ CDU_FaultNum2 : 27|12@0+ (1.0,0.0) [0.0|4095.0] "" BMS,VIU0
 SG_ CDU_FaultNum20 : 243|12@0+ (1.0,0.0) [0.0|4095.0] "" BMS,VIU0
 SG_ CDU_FaultNum3 : 47|12@0+ (1.0,0.0) [0.0|4095.0] "" BMS,VIU0
 SG_ CDU_FaultNum4 : 51|12@0+ (1.0,0.0) [0.0|4095.0] "" BMS,VIU0
 SG_ CDU_FaultNum5 : 71|12@0+ (1.0,0.0) [0.0|4095.0] "" BMS,VIU0
 SG_ CDU_FaultNum6 : 75|12@0+ (1.0,0.0) [0.0|4095.0] "" BMS,VIU0
 SG_ CDU_FaultNum7 : 95|12@0+ (1.0,0.0) [0.0|4095.0] "" BMS,VIU0
 SG_ CDU_FaultNum8 : 99|12@0+ (1.0,0.0) [0.0|4095.0] "" BMS,VIU0
 SG_ CDU_FaultNum9 : 119|12@0+ (1.0,0.0) [0.0|4095.0] "" BMS,VIU0
 SG_ CDU_FrameIndex : 12|5@0+ (1.0,0.0) [0.0|31.0] "" BMS,VIU0
 SG_ CDU_SupplierNum : 15|3@0+ (1.0,0.0) [0.0|7.0] "" BMS,VIU0
 SG_ CDU_TotalFaultNum : 7|8@0+ (1.0,0.0) [0.0|255.0] "" BMS,VIU0

BO_ 790 CDU_OBC_1 : 32 CCU
 SG_ CDU_OBC_1_Checksum : 7|16@0+ (1.0,0.0) [0.0|65535.0] "" BMS,VIU0
 SG_ CDU_OBC_1_Counter : 23|8@0+ (1.0,0.0) [0.0|255.0] "" BMS,VIU0
 SG_ OBC_ACInpFrq : 166|7@0+ (1.0,0.0) [0.0|127.0] "Hz" VIU0
 SG_ OBC_AcIptSts : 39|2@0+ (1,0) [0|3] "" TESTER
 SG_ OBC_AcIptType : 28|1@0+ (1,0) [0|1] "" TESTER
 SG_ OBC_CCRes : 100|13@0+ (1.0,0.0) [0.0|8191.0] "Ω" TESTER
 SG_ OBC_ChrgDischrgStep : 44|3@0+ (1.0,0.0) [0.0|7.0] "" TESTER
 SG_ OBC_ChrgGunCCSts : 50|3@0+ (1,0) [0|7] "" BMS,PICU,TC,VIU0
 SG_ OBC_CopntTemp : 119|8@0+ (1.0,-48.0) [-48.0|206.0] "℃" PICU
 SG_ OBC_CPDuty : 95|10@0+ (0.1,0.0) [0.0|102.30000000000001] "%" BMS
 SG_ OBC_CPFreqSts : 45|1@0+ (1,0) [0|1] "" TESTER
 SG_ OBC_CPFrq : 151|12@0+ (1.0,0.0) [0.0|4095.0] "Hz" VIU0
 SG_ OBC_CPOutpDuty : 175|10@0+ (0.1,0.0) [0.0|102.30000000000001] "%" VIU0
 SG_ OBC_CPOutpVolt : 190|7@0+ (0.1,0.0) [0.0|12.700000000000001] "V" VIU0
 SG_ OBC_CPSts : 35|4@0+ (1,0) [0|15] "" BMS
 SG_ OBC_CPValidSt : 127|2@0+ (1,0) [0|3] "" BMS,VIU0
 SG_ OBC_CPVolt : 86|7@0+ (0.1,0.0) [0.0|12.700000000000001] "V" BMS
 SG_ OBC_DeratFlag : 36|1@0+ (1,0) [0|1] "" VIU0
 SG_ OBC_DeratReason1 : 192|1@0+ (1,0) [0|1] "" TESTER
 SG_ OBC_DeratReason10 : 201|1@0+ (1,0) [0|1] "" TESTER
 SG_ OBC_DeratReason11 : 202|1@0+ (1,0) [0|1] "" TESTER
 SG_ OBC_DeratReason12 : 203|1@0+ (1,0) [0|1] "" TESTER
 SG_ OBC_DeratReason13 : 204|1@0+ (1,0) [0|1] "" TESTER
 SG_ OBC_DeratReason14 : 205|1@0+ (1,0) [0|1] "" TESTER
 SG_ OBC_DeratReason15 : 206|1@0+ (1,0) [0|1] "" TESTER
 SG_ OBC_DeratReason16 : 207|1@0+ (1,0) [0|1] "" TESTER
 SG_ OBC_DeratReason17 : 208|1@0+ (1,0) [0|1] "" TESTER
 SG_ OBC_DeratReason18 : 209|1@0+ (1,0) [0|1] "" TESTER
 SG_ OBC_DeratReason19 : 210|1@0+ (1,0) [0|1] "" TESTER
 SG_ OBC_DeratReason2 : 193|1@0+ (1,0) [0|1] "" TESTER
 SG_ OBC_DeratReason20 : 211|1@0+ (1,0) [0|1] "" TESTER
 SG_ OBC_DeratReason21 : 212|1@0+ (1,0) [0|1] "" TESTER
 SG_ OBC_DeratReason22 : 213|1@0+ (1,0) [0|1] "" TESTER
 SG_ OBC_DeratReason23 : 214|1@0+ (1,0) [0|1] "" TESTER
 SG_ OBC_DeratReason24 : 215|1@0+ (1,0) [0|1] "" TESTER
 SG_ OBC_DeratReason3 : 194|1@0+ (1,0) [0|1] "" TESTER
 SG_ OBC_DeratReason4 : 195|1@0+ (1,0) [0|1] "" TESTER
 SG_ OBC_DeratReason5 : 196|1@0+ (1,0) [0|1] "" TESTER
 SG_ OBC_DeratReason6 : 197|1@0+ (1,0) [0|1] "" TESTER
 SG_ OBC_DeratReason7 : 198|1@0+ (1,0) [0|1] "" TESTER
 SG_ OBC_DeratReason8 : 199|1@0+ (1,0) [0|1] "" TESTER
 SG_ OBC_DeratReason9 : 200|1@0+ (1,0) [0|1] "" TESTER
 SG_ OBC_DischrgLoadForm : 41|2@0+ (1,0) [0|3] "" BMS
 SG_ OBC_DisWorkMode : 125|3@0+ (1,0) [0|7] "" TESTER
 SG_ OBC_EnergyConvrtDir : 47|1@0+ (1,0) [0|1] "" TESTER
 SG_ OBC_FastChargeRelayNegSts : 253|2@0+ (1,0) [0|3] "" TESTER
 SG_ OBC_FastChargeRelayPosSts : 255|2@0+ (1,0) [0|3] "" TESTER
 SG_ OBC_FastChrgRelayNeg_Extd_U : 247|8@0+ (0.1,0.0) [0.0|25.5] "V" TESTER
 SG_ OBC_FastChrgRelayPos_Extd_U : 227|10@0+ (1.0,0.0) [0.0|1023.0] "V" TESTER
 SG_ OBC_FaultLevel : 53|3@0+ (1,0) [0|7] "" VIU0
 SG_ OBC_FaultLightReq : 24|1@0+ (1,0) [0|1] "" TESTER
 SG_ OBC_HVIL_AC_St : 55|2@0+ (1,0) [0|3] "" PICU,VIU0
 SG_ OBC_HVIL_DC_St : 251|2@0+ (1,0) [0|3] "" TESTER
 SG_ OBC_InsulationR : 223|12@0+ (1.0,0.0) [0.0|4095.0] "kΩ" TESTER
 SG_ OBC_OperSt : 59|4@0+ (1,0) [0|15] "" BMS,VIU0
 SG_ OBC_RatedPwrLevel : 31|3@0+ (1,0) [0|7] "" VIU0
 SG_ OBC_S1Sts : 25|1@0+ (1,0) [0|1] "" TESTER
 SG_ OBC_S2Sts : 26|1@0+ (1,0) [0|1] "" BMS
 SG_ OBC_S4Sts : 27|1@0+ (1,0) [0|1] "" TESTER
 SG_ OBC_WorkMode : 63|3@0+ (1,0) [0|7] "" BMS,VIU0

BO_ 794 CDU_OBC_2 : 32 CCU
 SG_ CDU_KL15_Volt : 255|8@0+ (0.1,0.0) [0.0|25.3] "V" TESTER
 SG_ CDU_KL30_Volt : 247|8@0+ (0.1,0.0) [0.0|25.3] "V" TESTER
 SG_ OBC_ACL1Currt : 159|10@0+ (0.1,0.0) [0.0|102.30000000000001] "A" VIU0
 SG_ OBC_ACL1Volt : 115|12@0+ (1.0,0.0) [0.0|4095.0] "V" VIU0
 SG_ OBC_ACL2Currt : 161|10@0+ (0.1,0.0) [0.0|102.30000000000001] "A" VIU0
 SG_ OBC_ACL2Volt : 135|12@0+ (1.0,0.0) [0.0|4095.0] "V" VIU0
 SG_ OBC_ACL3Currt : 183|10@0+ (0.1,0.0) [0.0|102.30000000000001] "A" VIU0
 SG_ OBC_ACL3Volt : 139|12@0+ (1.0,0.0) [0.0|4095.0] "V" VIU0
 SG_ OBC_ACPileMaxCurrt : 103|8@0+ (1.0,0.0) [0.0|255.0] "A" VIU0
 SG_ OBC_ACPwr : 202|11@0+ (0.1,0.0) [0.0|204.70000000000002] "kw" TESTER
 SG_ OBC_ChrgCablePermitCurrt : 90|3@0+ (1,0) [0|7] "" BMS,VIU0
 SG_ OBC_ChrgEndNum : 239|8@0+ (1.0,0.0) [0.0|255.0] "" VIU0
 SG_ OBC_ChrgOptMaxCurrt : 111|10@0+ (0.1,0.0) [0.0|102.30000000000001] "A" BMS,VIU0
 SG_ OBC_ChrgOptMaxPwr : 47|11@0+ (0.05,0.0) [0.0|102.35000000000001] "kw" BMS,VIU0
 SG_ OBC_ChrgOptMaxVolt : 49|10@0+ (1.0,0.0) [0.0|1023.0] "V" BMS
 SG_ OBC_ChrgOptMinVolt : 73|10@0+ (1.0,0.0) [0.0|1023.0] "V" TESTER
 SG_ OBC_DCChrgMod_LimCurrt : 223|9@0+ (2.0,0.0) [0.0|510.0] "A" VIU0
 SG_ OBC_DCCurrt : 199|11@0+ (0.1,-102.4) [-102.4|102.30000000000001] "A" BMS,VIU0
 SG_ OBC_DchaEndNum : 230|4@0+ (1.0,0.0) [0.0|15.0] "" VIU0
 SG_ OBC_DCVolt : 71|12@0+ (1.0,0.0) [0.0|4095.0] "V" BMS,VIU0
 SG_ OBC_DischrgOptMaxPwr : 25|10@0+ (0.1,0.0) [0.0|102.30000000000001] "kw" BMS,VIU0

BO_ 1460 CDU_Version : 32 CCU
 SG_ CDU_HwVersion : 23|8@0+ (1.0,0.0) [0.0|255.0] "" TESTER
 SG_ CDU_SupplierCode : 7|16@0+ (1.0,0.0) [0.0|65535.0] "" TESTER
 SG_ CDU_SwMajorVersion : 31|8@0+ (1.0,0.0) [0.0|255.0] "" TESTER
 SG_ CDU_SwMinorVersion : 39|8@0+ (1.0,0.0) [0.0|255.0] "" TESTER
 SG_ CDU_SwPatchVersion : 47|8@0+ (1.0,0.0) [0.0|255.0] "" TESTER
 SG_ CDU_SwVersionDay : 71|8@0+ (1.0,0.0) [0.0|31.0] "" TESTER
 SG_ CDU_SwVersionMonth : 63|8@0+ (1.0,0.0) [0.0|12.0] "" TESTER
 SG_ CDU_SwVersionYear : 55|8@0+ (1.0,0.0) [0.0|255.0] "" TESTER
 SG_ DCDC_SwMajorVersion : 79|8@0+ (1.0,0.0) [0.0|255.0] "" TESTER
 SG_ DCDC_SwMinorVersion : 87|8@0+ (1.0,0.0) [0.0|255.0] "" TESTER
 SG_ DCDC_SwPatchVersion : 95|8@0+ (1.0,0.0) [0.0|255.0] "" TESTER
 SG_ DCDC_SwVersionDay : 119|8@0+ (1.0,0.0) [0.0|31.0] "" TESTER
 SG_ DCDC_SwVersionMonth : 111|8@0+ (1.0,0.0) [0.0|12.0] "" TESTER
 SG_ DCDC_SwVersionYear : 103|8@0+ (1.0,0.0) [0.0|255.0] "" TESTER
 SG_ OBC_SwMajorVersion : 127|8@0+ (1.0,0.0) [0.0|255.0] "" TESTER
 SG_ OBC_SwMinorVersion : 135|8@0+ (1.0,0.0) [0.0|255.0] "" TESTER
 SG_ OBC_SwPatchVersion : 143|8@0+ (1.0,0.0) [0.0|255.0] "" TESTER
 SG_ OBC_SwVersionDay : 167|8@0+ (1.0,0.0) [0.0|31.0] "" TESTER
 SG_ OBC_SwVersionMonth : 159|8@0+ (1.0,0.0) [0.0|12.0] "" TESTER
 SG_ OBC_SwVersionYear : 151|8@0+ (1.0,0.0) [0.0|255.0] "" TESTER

BO_ 2015 Diag_FuncReq_PT : 8 VIU0
 SG_ Diag_FuncReq_PT : 7|64@0+ (1,0) [0|0] "" BMS, CCU, PEU, PICU, TC

BO_ 1768 Diag_PhyReq_AGS_L : 8 TESTER
 SG_ Diag_PhyReq_AGS_L : 7|64@0+ (1,0) [0|0] "" PICU

BO_ 1768 Diag_PhyReq_AGS_L : 8 VIU0
 SG_ Diag_PhyReq_AGS_L : 7|64@0+ (1,0) [0|0] "" PICU

BO_ 1769 Diag_PhyReq_AGS_R : 8 TESTER
 SG_ Diag_PhyReq_AGS_R : 7|64@0+ (1,0) [0|0] "" PICU

BO_ 1769 Diag_PhyReq_AGS_R : 8 VIU0
 SG_ Diag_PhyReq_AGS_R : 7|64@0+ (1,0) [0|0] "" PICU

BO_ 1775 Diag_PhyReq_BLOWER : 8 TESTER
 SG_ Diag_PhyReq_BLOWER : 7|64@0+ (1,0) [0|0] "" PICU

BO_ 1775 Diag_PhyReq_BLOWER : 8 VIU0
 SG_ Diag_PhyReq_BLOWER : 7|64@0+ (1,0) [0|0] "" PICU

BO_ 1811 Diag_PhyReq_BMS : 64 VIU0
 SG_ Diag_PhyReq_BMS : 7|512@0+ (1,0) [0|0] "" BMS

BO_ 1814 Diag_PhyReq_CCU : 8 TESTER
 SG_ Diag_PhyReq_CCU : 7|64@0+ (1,0) [0|0] "" PICU

BO_ 1814 Diag_PhyReq_CCU : 8 VIU0
 SG_ Diag_PhyReq_CCU : 7|64@0+ (1,0) [0|0] "" PICU

BO_ 1853 Diag_PhyReq_CDU : 64 VIU0
 SG_ Diag_PhyReq_CDU : 7|512@0+ (1,0) [0|0] "" CCU

BO_ 1774 Diag_PhyReq_ECCVC : 8 VIU0
 SG_ Diag_PhyReq_ECCVC : 7|64@0+ (1,0) [0|0] "" PICU

BO_ 1651 Diag_PhyReq_EEMWP : 8 VIU0
 SG_ Diag_PhyReq_EEMWP : 7|64@0+ (1,0) [0|0] "" PICU

BO_ 2016 Diag_PhyReq_EMS : 8 VIU0
 SG_ Diag_PhyReq_EMS : 7|64@0+ (1,0) [0|0] "" PICU

BO_ 1819 Diag_PhyReq_GCU : 64 VIU0
 SG_ Diag_PhyReq_GCU : 7|512@0+ (1,0) [0|0] "" PEU

BO_ 1830 Diag_PhyReq_HPC : 8 VIU0
 SG_ Diag_PhyReq_HPC : 7|64@0+ (1,0) [0|0] "" Vector_XXX

BO_ 1818 Diag_PhyReq_MCUR : 64 VIU0
 SG_ Diag_PhyReq_MCUR : 7|512@0+ (1,0) [0|0] "" TC

BO_ 1652 Diag_PhyReq_PDU : 8 VIU0
 SG_ Diag_PhyReq_PDU : 7|64@0+ (1,0) [0|0] "" BMS

BO_ 1873 Diag_PhyReq_PTC : 8 TESTER
 SG_ Diag_PhyReq_PTC : 7|64@0+ (1,0) [0|0] "" PICU

BO_ 1873 Diag_PhyReq_PTC : 8 VIU0
 SG_ Diag_PhyReq_PTC : 7|64@0+ (1,0) [0|0] "" PICU

BO_ 1815 Diag_PhyReq_TDU : 64 VIU0
 SG_ Diag_PhyReq_TDU : 7|512@0+ (1,0) [0|0] "" Vector_XXX

BO_ 1784 Diag_Resp_AGS_L : 8 PICU
 SG_ Diag_Resp_AGS_L : 7|64@0+ (1,0) [0|0] "" TESTER, VIU0

BO_ 1785 Diag_Resp_AGS_R : 8 PICU
 SG_ Diag_Resp_AGS_R : 7|64@0+ (1,0) [0|0] "" TESTER, VIU0

BO_ 1791 Diag_Resp_BLOWER : 8 PICU
 SG_ Diag_Resp_BLOWER : 7|64@0+ (1,0) [0|0] "" TESTER, VIU0

BO_ 1939 Diag_Resp_BMS : 64 BMS
 SG_ Diag_Resp_BMS : 7|512@0+ (1,0) [0|0] "" VIU0

BO_ 1942 Diag_Resp_CCU : 8 PICU
 SG_ Diag_Resp_CCU : 7|64@0+ (1,0) [0|0] "" TESTER, VIU0

BO_ 1981 Diag_Resp_CDU : 64 CCU
 SG_ Diag_Resp_CDU : 7|512@0+ (1,0) [0|0] "" VIU0

BO_ 1790 Diag_Resp_ECCVC : 8 PICU
 SG_ Diag_Resp_ECCVC : 7|64@0+ (1,0) [0|0] "" VIU0

BO_ 1659 Diag_Resp_EEMWP : 8 PICU
 SG_ Diag_Resp_EEMWP : 7|64@0+ (1,0) [0|0] "" VIU0

BO_ 2024 Diag_Resp_EMS : 8 PICU
 SG_ Diag_Resp_EMS : 7|64@0+ (1,0) [0|0] "" VIU0

BO_ 1947 Diag_Resp_GCU : 64 PEU
 SG_ Diag_Resp_GCU : 7|512@0+ (1,0) [0|0] "" VIU0

BO_ 1946 Diag_Resp_MCUR : 64 TC
 SG_ Diag_Resp_MCUR : 7|512@0+ (1,0) [0|0] "" VIU0

BO_ 1660 Diag_Resp_PDU : 8 BMS
 SG_ Diag_Resp_PDU : 7|64@0+ (1,0) [0|0] "" VIU0

BO_ 2001 Diag_Resp_PTC : 8 PICU
 SG_ Diag_Resp_PTC : 7|64@0+ (1,0) [0|0] "" TESTER, VIU0

BO_ 872 EMS_CANFD_Tester : 32 PICU
 SG_ EMS_ClpFebckMean : 63|8@0+ (0.0025,0.7) [0.7|1.3375] "" TESTER
 SG_ EMS_CorrFxMsThrot : 87|8@0+ (0.008,0.5) [0.5|2.54] "" TESTER
 SG_ EMS_CorrFxPrsToLd : 31|8@0+ (0.008,0.5) [0.5|2.54] "" TESTER
 SG_ EMS_DwnCatTrm : 46|6@0+ (0.0015,-0.05) [-0.05|0.3325] "" TESTER
 SG_ EMS_EGRActPostion : 71|8@0+ (0.4,0.0) [0.0|102.0] "" TESTER
 SG_ EMS_EnKnkSts : 55|8@0+ (1.0,0.0) [0.0|255.0] "" TESTER
 SG_ EMS_Lambda : 79|8@0+ (0.0025,0.7) [0.7|1.3375] "" TESTER
 SG_ EMS_MulAdp : 39|8@0+ (0.0025,0.7) [0.7|1.3375] "" TESTER
 SG_ EMS_SupKnkPuls : 47|1@0+ (1.0,0.0) [0.0|255.0] "" TESTER

BO_ 1421 EMS_Fault : 32 PICU
 SG_ EMS_FaultNum1 : 23|12@0+ (1.0,0.0) [0.0|4095.0] "" VIU0
 SG_ EMS_FaultNum10 : 123|12@0+ (1.0,0.0) [0.0|4095.0] "" VIU0
 SG_ EMS_FaultNum11 : 143|12@0+ (1.0,0.0) [0.0|4095.0] "" VIU0
 SG_ EMS_FaultNum12 : 147|12@0+ (1.0,0.0) [0.0|4095.0] "" VIU0
 SG_ EMS_FaultNum13 : 167|12@0+ (1.0,0.0) [0.0|4095.0] "" VIU0
 SG_ EMS_FaultNum14 : 171|12@0+ (1.0,0.0) [0.0|4095.0] "" VIU0
 SG_ EMS_FaultNum15 : 191|12@0+ (1.0,0.0) [0.0|4095.0] "" VIU0
 SG_ EMS_FaultNum16 : 195|12@0+ (1.0,0.0) [0.0|4095.0] "" VIU0
 SG_ EMS_FaultNum17 : 215|12@0+ (1.0,0.0) [0.0|4095.0] "" VIU0
 SG_ EMS_FaultNum18 : 219|12@0+ (1.0,0.0) [0.0|4095.0] "" VIU0
 SG_ EMS_FaultNum19 : 239|12@0+ (1.0,0.0) [0.0|4095.0] "" VIU0
 SG_ EMS_FaultNum2 : 27|12@0+ (1.0,0.0) [0.0|4095.0] "" VIU0
 SG_ EMS_FaultNum20 : 243|12@0+ (1.0,0.0) [0.0|4095.0] "" VIU0
 SG_ EMS_FaultNum3 : 47|12@0+ (1.0,0.0) [0.0|4095.0] "" VIU0
 SG_ EMS_FaultNum4 : 51|12@0+ (1.0,0.0) [0.0|4095.0] "" VIU0
 SG_ EMS_FaultNum5 : 71|12@0+ (1.0,0.0) [0.0|4095.0] "" VIU0
 SG_ EMS_FaultNum6 : 75|12@0+ (1.0,0.0) [0.0|4095.0] "" VIU0
 SG_ EMS_FaultNum7 : 95|12@0+ (1.0,0.0) [0.0|4095.0] "" VIU0
 SG_ EMS_FaultNum8 : 99|12@0+ (1.0,0.0) [0.0|4095.0] "" VIU0
 SG_ EMS_FaultNum9 : 119|12@0+ (1.0,0.0) [0.0|4095.0] "" VIU0
 SG_ EMS_FrameIndex : 12|5@0+ (1.0,0.0) [0.0|31.0] "" VIU0
 SG_ EMS_SupplierNum : 15|3@0+ (1.0,0.0) [0.0|7.0] "" VIU0
 SG_ EMS_TotalFaultNum : 7|8@0+ (1.0,0.0) [0.0|255.0] "" VIU0

BO_ 291 EMS_State_1 : 32 PICU
 SG_ EMS_ActIgnAng : 87|8@0+ (1.0,-50.0) [-50.0|50.0] "" VIU0
 SG_ EMS_BasIgnAng : 79|8@0+ (1.0,-50.0) [-50.0|50.0] "" VIU0
 SG_ EMS_CalculatedLoadRat : 55|8@0+ (0.394,0.0) [0.0|100.07600000000001] "%" BMS,PEU,TC,VIU0
 SG_ EMS_CatHeatingReq : 25|1@0+ (1,0) [0|1] "" VIU0
 SG_ EMS_DewPointEndSt : 47|1@0+ (1,0) [0|1] "" VIU0
 SG_ EMS_DrvgCyc : 161|1@0+ (1,0) [0|1] "" BMS,PEU,TC,VIU0
 SG_ EMS_EngIdleCtrlSts : 36|1@0+ (1,0) [0|1] "" VIU0
 SG_ EMS_EngKonckSt : 33|1@0+ (1,0) [0|1] "" VIU0
 SG_ EMS_EngStartInhb : 42|1@0+ (1,0) [0|1] "" VIU0
 SG_ EMS_EngStartReq : 27|2@0+ (1,0) [0|3] "" VIU0
 SG_ EMS_EngStartSuccess : 40|1@0+ (1,0) [0|1] "" VIU0
 SG_ EMS_EngStopInhb : 41|1@0+ (1,0) [0|1] "" VIU0
 SG_ EMS_ExhaustPhaseValue : 199|8@0+ (1.0,-100.0) [-100.0|155.0] "" VIU0
 SG_ EMS_ExhGasTMnfld : 175|12@0+ (1.0,-100.0) [-100.0|1500.0] "℃" VIU0
 SG_ EMS_FuelCmspMassFlow : 63|16@0+ (0.001,0.0) [0.0|25.0] "ml/s" VIU0
 SG_ EMS_FuelSigFlt : 230|3@0+ (1,0) [0|7] "" VIU0
 SG_ EMS_IgnAngIntvSt : 32|1@0+ (1,0) [0|1] "" VIU0
 SG_ EMS_IgnCyc : 162|1@0+ (1,0) [0|1] "" BMS,PEU,TC,VIU0
 SG_ EMS_IntakePhaseValue : 191|8@0+ (1.0,-100.0) [-100.0|155.0] "" VIU0
 SG_ EMS_LimpHomeSt : 35|1@0+ (1,0) [0|1] "" VIU0
 SG_ EMS_OilPWarnLamp : 179|2@0+ (1,0) [0|3] "" VIU0
 SG_ EMS_OilPWarnSt : 177|2@0+ (1,0) [0|3] "" VIU0
 SG_ EMS_OilSnsrResistorVal : 223|9@0+ (1.0,0.0) [0.0|509.0] "Ω" VIU0
 SG_ EMS_OperSt : 39|3@0+ (1,0) [0|7] "" VIU0
 SG_ EMS_Pvd : 99|12@0+ (1.0,0.0) [0.0|4000.0] "hPa" VIU0
 SG_ EMS_PvdVld : 119|1@0+ (1,0) [0|1] "" VIU0
 SG_ EMS_RelAirChrg : 95|12@0+ (0.1,0.0) [0.0|192.0] "%" VIU0
 SG_ EMS_State_1_Checksum : 7|16@0+ (1.0,0.0) [0.0|65535.0] "" VIU0
 SG_ EMS_State_1_Counter : 23|8@0+ (1.0,0.0) [0.0|255.0] "" VIU0
 SG_ EMS_StPrioWpDmd : 46|4@0+ (1.0,0.0) [0.0|15.0] "" VIU0
 SG_ EMS_ThrAbsPosn : 207|8@0+ (0.4,0.0) [0.0|101.60000000000001] "%" BMS,PEU,TC,VIU0
 SG_ EMS_ThrRelPosn : 215|8@0+ (0.4,0.0) [0.0|101.60000000000001] "%" BMS,PEU,TC,VIU0
 SG_ EMS_TqCtrlInhbSt : 34|1@0+ (1,0) [0|1] "" VIU0
 SG_ EMS_WarmupCyc : 160|1@0+ (1,0) [0|1] "" BMS,PEU,TC,VIU0
 SG_ EMS_WorkpointReq : 24|1@0+ (1,0) [0|1] "" VIU0

BO_ 386 EMS_State_2 : 32 PICU
 SG_ EMS_AfterRunReq : 150|1@0+ (1,0) [0|1] "" BMS,VIU0
 SG_ EMS_AmbAirP : 127|8@0+ (5.0,0.0) [0.0|1275.0] "hpa" VIU0
 SG_ EMS_AmbAirPVld : 104|1@0+ (1,0) [0|1] "" VIU0
 SG_ EMS_CACPumpReq : 39|8@0+ (0.5,0.0) [0.0|100.0] "%" VIU0
 SG_ EMS_CatTemp : 175|8@0+ (6.0,-40.0) [-40.0|1484.0] "℃" VIU0
 SG_ EMS_CatTempVld : 207|1@0+ (1,0) [0|1] "" VIU0
 SG_ EMS_CoolantFanReq : 167|8@0+ (0.5,0.0) [0.0|100.0] "%" VIU0
 SG_ EMS_EngCoolantTemp : 143|8@0+ (1.0,-40.0) [-40.0|214.0] "℃" BMS,PEU,TC,VIU0
 SG_ EMS_EngCoolantTempVld : 151|1@0+ (1,0) [0|1] "" PEU,TC,VIU0
 SG_ EMS_EngFuelCutOffSt : 77|1@0+ (1,0) [0|1] "" VIU0
 SG_ EMS_EngFuleCutOffAlldSt : 76|1@0+ (1,0) [0|1] "" VIU0
 SG_ EMS_EngIntkAirTemp : 135|8@0+ (1.0,-40.0) [-40.0|214.0] "℃" VIU0
 SG_ EMS_EngOverSpdFlg : 94|1@0+ (1,0) [0|1] "" VIU0
 SG_ EMS_EngSpdSnsrFltSt : 95|1@0+ (1,0) [0|1] "" VIU0
 SG_ EMS_EngStopTi : 55|16@0+ (1.0,0.0) [0.0|65533.0] "s" VIU0
 SG_ EMS_EngThrPosn : 71|8@0+ (0.4,0.0) [0.0|101.60000000000001] "%" VIU0
 SG_ EMS_EngThrPosnFlt : 80|1@0+ (1,0) [0|1] "" VIU0
 SG_ EMS_FitvFlt : 109|2@0+ (1,0) [0|3] "" VIU0
 SG_ EMS_FitvSt : 111|2@0+ (1,0) [0|3] "" VIU0
 SG_ EMS_FltLvl : 93|3@0+ (1,0) [0|7] "" VIU0
 SG_ EMS_FuelAddingAlldSt : 107|2@0+ (1,0) [0|3] "" VIU0
 SG_ EMS_FuelCutOffDiagSt : 79|2@0+ (1,0) [0|3] "" VIU0
 SG_ EMS_FuelInjected : 183|16@0+ (0.001,0.0) [0.0|65.535] "ml" VIU0
 SG_ EMS_FuelInjectedVld : 206|1@0+ (1,0) [0|1] "" VIU0
 SG_ EMS_FuelTankP : 90|10@0+ (0.1,-30.0) [-30.0|50.0] "kPa" VIU0
 SG_ EMS_FuelTankPRlsSt : 96|1@0+ (1,0) [0|1] "" VIU0
 SG_ EMS_IntkMnfldP : 75|10@0+ (4.0,100.0) [100.0|4188.0] "mbar" VIU0
 SG_ EMS_IntkMnfldPVld : 81|1@0+ (1,0) [0|1] "" VIU0
 SG_ EMS_LvBattVolt : 119|8@0+ (0.1,0.0) [0.0|25.0] "V" VIU0
 SG_ EMS_MilIndicator : 47|2@0+ (1,0) [0|3] "" VIU0
 SG_ EMS_RadiatorOutWaterTemp : 231|8@0+ (1.0,-40.0) [-40.0|214.0] "℃" VIU0
 SG_ EMS_RadiatorOutWaterTempVld : 205|1@0+ (1,0) [0|1] "" VIU0
 SG_ EMS_State_2_Checksum : 7|16@0+ (1.0,0.0) [0.0|65535.0] "" VIU0
 SG_ EMS_State_2_Counter : 23|8@0+ (1.0,0.0) [0.0|255.0] "" VIU0
 SG_ EMS_ThrFwdEngIntkAirTemp : 215|8@0+ (1.0,-40.0) [-40.0|214.0] "℃" VIU0
 SG_ EMS_ThrFwdEngIntkAirTempVld : 204|1@0+ (1,0) [0|1] "" VIU0
 SG_ EMS_TWVE_ActPerc : 246|7@0+ (1.0,0.0) [0.0|100.0] "%" VIU0
 SG_ EMS_TWVE_TrgtPerc : 238|7@0+ (1.0,0.0) [0.0|100.0] "%" VIU0
 SG_ EMS_WarmupAch : 148|1@0+ (1,0) [0|1] "" VIU0
 SG_ EMS_WaterPumpRotSpd : 145|10@0+ (10.0,0.0) [0.0|10220.0] "rpm" VIU0
 SG_ EMS_WaterPumpSt : 149|1@0+ (1,0) [0|1] "" VIU0

BO_ 290 EMS_Tq_Spd : 32 PICU
 SG_ EMS_EngActSpd : 141|13@0+ (1.0,0.0) [0.0|8000.0] "rpm" BMS,PEU,TC,VIU0
 SG_ EMS_EngActSpdVld : 142|1@0+ (1,0) [0|1] "" PEU,TC,VIU0
 SG_ EMS_EngCrankPosn : 114|7@0+ (1.0,0.0) [0.0|119.0] "" VIU0
 SG_ EMS_EngFricTq : 123|12@0+ (0.1,0.0) [0.0|409.0] "Nm" VIU0
 SG_ EMS_EngFricTqVld : 143|1@0+ (1,0) [0|1] "" VIU0
 SG_ EMS_EngineSpdLim : 175|13@0+ (1.0,0.0) [0.0|8000.0] "rpm" VIU0
 SG_ EMS_FlyWhlActTq : 38|13@0+ (0.1,-350.0) [-350.0|469.0] "Nm" PEU,VIU0
 SG_ EMS_FlyWhlActTqVld : 77|1@0+ (1,0) [0|1] "" PEU,VIU0
 SG_ EMS_FlyWhlTqCrsLeadMax : 60|13@0+ (0.1,-350.0) [-350.0|469.0] "Nm" VIU0
 SG_ EMS_FlyWhlTqCrsLeadMaxVld : 79|1@0+ (1,0) [0|1] "" VIU0
 SG_ EMS_FlyWhlTqCrsLeadMin : 76|13@0+ (0.1,-350.0) [-350.0|469.0] "Nm" VIU0
 SG_ EMS_FlyWhlTqCrsLeadMinVld : 95|1@0+ (1,0) [0|1] "" VIU0
 SG_ EMS_FlyWhlTqCrsSetMax : 94|13@0+ (0.1,-350.0) [-350.0|469.0] "Nm" VIU0
 SG_ EMS_FlyWhlTqCrsSetMaxVld : 97|1@0+ (1,0) [0|1] "" VIU0
 SG_ EMS_FlyWhlTqCrsSetMin : 111|13@0+ (0.1,-350.0) [-350.0|469.0] "Nm" VIU0
 SG_ EMS_FlyWhlTqCrsSetMinVld : 96|1@0+ (1,0) [0|1] "" VIU0
 SG_ EMS_FlyWhlTqMinWoCutoff : 41|13@0+ (0.1,-350.0) [-350.0|469.0] "Nm" VIU0
 SG_ EMS_FlyWhlTqMinWoCutoffVld : 78|1@0+ (1,0) [0|1] "" VIU0
 SG_ EMS_IdleSpdBaseRef : 159|8@0+ (10.0,0.0) [0.0|2540.0] "rpm" VIU0
 SG_ EMS_IdleSpdCurr : 167|8@0+ (10.0,0.0) [0.0|2540.0] "rpm" VIU0
 SG_ EMS_IdleSpdRefVld : 144|1@0+ (1,0) [0|1] "" VIU0
 SG_ EMS_MaxSpdWorkpointReq : 223|13@0+ (1.0,0.0) [0.0|7000.0] "rpm" VIU0
 SG_ EMS_MaxTqWorkpointReq : 199|11@0+ (0.5,-500.0) [-500.0|500.0] "Nm" VIU0
 SG_ EMS_MinSpdWorkpointReq : 204|13@0+ (1.0,0.0) [0.0|7000.0] "rpm" VIU0
 SG_ EMS_MinTqWorkpointReq : 178|11@0+ (0.5,-500.0) [-500.0|500.0] "Nm" VIU0
 SG_ EMS_SpdSyncSt : 31|1@0+ (1,0) [0|1] "" VIU0
 SG_ EMS_Tq_Spd_Checksum : 7|16@0+ (1.0,0.0) [0.0|65535.0] "" PEU,VIU0
 SG_ EMS_Tq_Spd_Counter : 23|8@0+ (1.0,0.0) [0.0|255.0] "" PEU,VIU0

BO_ 1553 EMS_Version : 32 PICU
 SG_ EMS_HwVersion : 23|8@0+ (1.0,0.0) [0.0|255.0] "" TESTER,VIU0
 SG_ EMS_SupplierCode : 7|16@0+ (1.0,0.0) [0.0|65535.0] "" TESTER,VIU0
 SG_ EMS_SwMajorVersion : 31|8@0+ (1.0,0.0) [0.0|255.0] "" TESTER,VIU0
 SG_ EMS_SwMinorVersion : 39|8@0+ (1.0,0.0) [0.0|255.0] "" TESTER,VIU0
 SG_ EMS_SwPatchVersion : 47|8@0+ (1.0,0.0) [0.0|255.0] "" TESTER,VIU0
 SG_ EMS_SwVersionDay : 71|8@0+ (1.0,0.0) [0.0|31.0] "" TESTER,VIU0
 SG_ EMS_SwVersionMonth : 63|8@0+ (1.0,0.0) [0.0|12.0] "" TESTER,VIU0
 SG_ EMS_SwVersionYear : 55|8@0+ (1.0,0.0) [0.0|255.0] "" TESTER,VIU0

BO_ 909 ESSPTC_HVStsFD : 32 VIU0
 SG_ ESSPTC_HVIL_Sta : 113|2@0+ (1,0) [0|3] "" PICU
 SG_ ESSPTCActuCrnt : 89|10@0+ (0.1,-20.0) [-20.0|82.30000000000001] "" BMS,PICU
 SG_ ESSPTCActuPWMDuty : 127|8@0+ (0.5,0.0) [0.0|127.5] "" PICU
 SG_ ESSPTCActuPwr : 135|16@0+ (1.0,0.0) [0.0|65535.0] "" PICU
 SG_ ESSPTCActuVol : 111|10@0+ (0.5,100.0) [100.0|611.5] "" PICU
 SG_ ESSPTCFltLvl : 94|4@0+ (1,0) [0|15] "" PICU
 SG_ ESSPTCIGBTOverHeat : 90|1@0+ (1,0) [0|1] "" PICU
 SG_ ESSPTCIGBTSts : 29|1@0+ (1,0) [0|1] "" PICU
 SG_ ESSPTCIGBTTem : 39|9@0+ (0.5,-40.0) [-40.0|215.5] "" PICU
 SG_ ESSPTCInptTem : 55|9@0+ (0.5,-40.0) [-40.0|215.5] "" PICU
 SG_ ESSPTCNTCSts : 28|3@0+ (1,0) [0|7] "" PICU
 SG_ ESSPTCOtptTem : 71|9@0+ (0.5,-40.0) [-40.0|215.5] "" PICU
 SG_ ESSPTCOverCrnt : 24|1@0+ (1,0) [0|1] "" PICU
 SG_ ESSPTCOverHeat : 25|1@0+ (1,0) [0|1] "" PICU
 SG_ ESSPTCOverVol : 46|1@0+ (1,0) [0|1] "" PICU
 SG_ ESSPTCPCBTem : 87|9@0+ (0.5,-40.0) [-40.0|215.5] "" PICU
 SG_ ESSPTCRlngCtr : 117|4@0+ (1.0,0.0) [0.0|15.0] "" PICU
 SG_ ESSPTCSecRlngCtr : 147|4@0+ (1.0,0.0) [0.0|15.0] "" PICU
 SG_ ESSPTCSts : 45|2@0+ (1,0) [0|3] "" PICU
 SG_ ESSPTCUnderVol : 43|1@0+ (1,0) [0|1] "" PICU

BO_ 1423 GCU_Fault : 32 PEU
 SG_ GCU_FaultNum1 : 23|12@0+ (1.0,0.0) [0.0|4095.0] "" VIU0
 SG_ GCU_FaultNum10 : 123|12@0+ (1.0,0.0) [0.0|4095.0] "" VIU0
 SG_ GCU_FaultNum11 : 143|12@0+ (1.0,0.0) [0.0|4095.0] "" VIU0
 SG_ GCU_FaultNum12 : 147|12@0+ (1.0,0.0) [0.0|4095.0] "" VIU0
 SG_ GCU_FaultNum13 : 167|12@0+ (1.0,0.0) [0.0|4095.0] "" VIU0
 SG_ GCU_FaultNum14 : 171|12@0+ (1.0,0.0) [0.0|4095.0] "" VIU0
 SG_ GCU_FaultNum15 : 191|12@0+ (1.0,0.0) [0.0|4095.0] "" VIU0
 SG_ GCU_FaultNum16 : 195|12@0+ (1.0,0.0) [0.0|4095.0] "" VIU0
 SG_ GCU_FaultNum17 : 215|12@0+ (1.0,0.0) [0.0|4095.0] "" VIU0
 SG_ GCU_FaultNum18 : 219|12@0+ (1.0,0.0) [0.0|4095.0] "" VIU0
 SG_ GCU_FaultNum19 : 239|12@0+ (1.0,0.0) [0.0|4095.0] "" VIU0
 SG_ GCU_FaultNum2 : 27|12@0+ (1.0,0.0) [0.0|4095.0] "" VIU0
 SG_ GCU_FaultNum20 : 243|12@0+ (1.0,0.0) [0.0|4095.0] "" VIU0
 SG_ GCU_FaultNum3 : 47|12@0+ (1.0,0.0) [0.0|4095.0] "" VIU0
 SG_ GCU_FaultNum4 : 51|12@0+ (1.0,0.0) [0.0|4095.0] "" VIU0
 SG_ GCU_FaultNum5 : 71|12@0+ (1.0,0.0) [0.0|4095.0] "" VIU0
 SG_ GCU_FaultNum6 : 75|12@0+ (1.0,0.0) [0.0|4095.0] "" VIU0
 SG_ GCU_FaultNum7 : 95|12@0+ (1.0,0.0) [0.0|4095.0] "" VIU0
 SG_ GCU_FaultNum8 : 99|12@0+ (1.0,0.0) [0.0|4095.0] "" VIU0
 SG_ GCU_FaultNum9 : 119|12@0+ (1.0,0.0) [0.0|4095.0] "" VIU0
 SG_ GCU_FrameIndex : 12|5@0+ (1.0,0.0) [0.0|31.0] "" VIU0
 SG_ GCU_SupplierNum : 15|3@0+ (1.0,0.0) [0.0|7.0] "" VIU0
 SG_ GCU_TotalFaultNum : 7|8@0+ (1.0,0.0) [0.0|255.0] "" VIU0

BO_ 294 GCU_State_1 : 32 PEU
 SG_ GCU_ActEff : 63|8@0+ (0.5,0.0) [0.0|100.0] "%" VIU0
 SG_ GCU_ActMaxVolt : 71|13@0+ (0.1,0.0) [0.0|800.0] "V" VIU0
 SG_ GCU_ActMinVolt : 84|13@0+ (0.1,0.0) [0.0|800.0] "V" VIU0
 SG_ GCU_CurrtPhaA : 135|16@0+ (0.1,-3276.8) [-3276.8|3276.7] "" BMS,VIU0
 SG_ GCU_CurrtPhaB : 151|16@0+ (0.1,-3276.8) [-3276.8|3276.7] "" BMS,VIU0
 SG_ GCU_CurrtPhaC : 167|16@0+ (0.1,-3276.8) [-3276.8|3276.7] "" BMS,VIU0
 SG_ GCU_DCCurrt : 119|16@0+ (0.1,-1000.0) [-1000.0|5553.5] "A" BMS,PICU,VIU0
 SG_ GCU_DchaSt : 30|2@0+ (1,0) [0|3] "" PICU,VIU0
 SG_ GCU_DCVolt : 103|16@0+ (0.1,0.0) [0.0|6553.5] "V" PICU,VIU0
 SG_ GCU_FltLvl : 26|3@0+ (1,0) [0|7] "" PICU,VIU0
 SG_ GCU_HVIL_St : 47|2@0+ (1,0) [0|3] "" VIU0
 SG_ GCU_IGBTMod : 28|2@0+ (1,0) [0|3] "" PICU,VIU0
 SG_ GCU_MILReq : 31|1@0+ (1,0) [0|1] "" PICU,VIU0
 SG_ GCU_MotWorkSt : 35|4@0+ (1,0) [0|15] "" VIU0
 SG_ GCU_OBDFaultExistSts : 45|1@0+ (1,0) [0|1] "" PICU
 SG_ GCU_OperMod : 39|4@0+ (1,0) [0|15] "" PICU,VIU0
 SG_ GCU_ResolverFltTyp : 44|5@0+ (1,0) [0|31] "" VIU0
 SG_ GCU_State_1_Checksum : 7|16@0+ (1.0,0.0) [0.0|65535.0] "" PICU,VIU0
 SG_ GCU_State_1_Counter : 23|8@0+ (1.0,0.0) [0.0|255.0] "" PICU,VIU0

BO_ 799 GCU_State_2 : 32 PEU
 SG_ GCU_FlowReq : 119|8@0+ (0.1,0.0) [0.0|25.5] "L/min" PICU,VIU0
 SG_ GCU_IGBTTempA : 31|8@0+ (1.0,-48.0) [-48.0|207.0] "℃" PICU,VIU0
 SG_ GCU_IGBTTempA_Chip : 55|8@0+ (1.0,-48.0) [-48.0|207.0] "℃" PICU,VIU0
 SG_ GCU_IGBTTempB : 39|8@0+ (1.0,-48.0) [-48.0|207.0] "℃" PICU,VIU0
 SG_ GCU_IGBTTempB_Chip : 63|8@0+ (1.0,-48.0) [-48.0|207.0] "℃" PICU,VIU0
 SG_ GCU_IGBTTempC : 47|8@0+ (1.0,-48.0) [-48.0|207.0] "℃" PICU,VIU0
 SG_ GCU_IGBTTempC_Chip : 71|8@0+ (1.0,-48.0) [-48.0|207.0] "℃" PICU,VIU0
 SG_ GCU_KL15OnSt : 137|2@0+ (1,0) [0|3] "" PICU,VIU0
 SG_ GCU_KL15Volt : 127|8@0+ (0.1,0.0) [0.0|24.0] "V" PICU,VIU0
 SG_ GCU_KL30Volt : 135|8@0+ (0.1,0.0) [0.0|24.0] "V" PICU,VIU0
 SG_ GCU_PCBTemp : 111|8@0+ (1.0,-48.0) [-48.0|207.0] "℃" PICU,VIU0
 SG_ GCU_RotorTemp : 87|8@0+ (1.0,-48.0) [-48.0|207.0] "℃" PICU,VIU0
 SG_ GCU_State_2_Checksum : 7|16@0+ (1.0,0.0) [0.0|65535.0] "" VIU0
 SG_ GCU_State_2_Counter : 23|8@0+ (1.0,0.0) [0.0|255.0] "" VIU0
 SG_ GCU_TempWinding : 79|8@0+ (1.0,-48.0) [-48.0|207.0] "℃" PICU,VIU0

BO_ 855 GCU_State_3 : 32 PEU
 SG_ GCU_EOP_Actual_Speed : 31|8@0+ (1.0,0.0) [0.0|255.0] "" TESTER
 SG_ GCU_EOP_AIRmix_Fault : 83|1@0+ (1,0) [0|1] "" TESTER
 SG_ GCU_EOP_Current : 55|8@0+ (0.2,0.0) [0.0|51.0] "" TESTER
 SG_ GCU_EOP_MOS_Temp : 63|8@0+ (1.0,-40.0) [-40.0|215.0] "℃" TESTER
 SG_ GCU_EOP_Over_Current_Fault : 87|1@0+ (1,0) [0|1] "" TESTER
 SG_ GCU_EOP_Over_Temp_Fault : 85|1@0+ (1,0) [0|1] "" TESTER
 SG_ GCU_EOP_Over_Voltage_Fault : 86|1@0+ (1,0) [0|1] "" TESTER
 SG_ GCU_EOP_Self_Check_Fault : 103|1@0+ (1,0) [0|1] "" TESTER
 SG_ GCU_EOP_State : 82|3@0+ (1,0) [0|7] "" TESTER
 SG_ GCU_EOP_Stuck_Fault : 84|1@0+ (1,0) [0|1] "" TESTER
 SG_ GCU_EOP_Target_Speed : 39|8@0+ (1.0,0.0) [0.0|255.0] "" TESTER
 SG_ GCU_EOP_Under_Voltage_Fault : 95|1@0+ (1,0) [0|1] "" TESTER
 SG_ GCU_EOP_Voltage : 47|8@0+ (0.2,0.0) [0.0|51.0] "" TESTER
 SG_ GCU_HVCalSt : 115|2@0+ (1,0) [0|3] "" TESTER

BO_ 293 GCU_Tq_Spd : 32 PEU
 SG_ GCU_ActRotSpd : 95|16@0+ (1.0,-32768.0) [-32768.0|32767.0] "rpm" PICU,VIU0
 SG_ GCU_ActTq : 31|16@0+ (0.1,-3276.8) [-3276.8|3276.7] "Nm" PICU,VIU0
 SG_ GCU_ActUnfilteredRotSpd : 111|16@0+ (1.0,-32768.0) [-32768.0|32767.0] "rpm" VIU0
 SG_ GCU_CompensationTq : 40|9@0+ (0.1,-25.5) [-25.5|25.6] "Nm" PICU,VIU0
 SG_ GCU_MaxOutputEleTq : 79|16@0+ (0.1,-3276.8) [-3276.8|3276.7] "Nm" VIU0
 SG_ GCU_MaxOutputGenTq : 63|16@0+ (0.1,-3276.8) [-3276.8|3276.7] "Nm" VIU0
 SG_ GCU_RotSpdMaxLimit : 121|10@0+ (50.0,-20000.0) [-20000.0|20000.0] "rpm" VIU0
 SG_ GCU_Tq_Spd_Checksum : 7|16@0+ (1.0,0.0) [0.0|65535.0] "" PICU,VIU0
 SG_ GCU_Tq_Spd_Counter : 23|8@0+ (1.0,0.0) [0.0|255.0] "" PICU,VIU0

BO_ 1465 GCU_Version : 32 PEU
 SG_ GCU_HwVersion : 23|8@0+ (1.0,0.0) [0.0|255.0] "" TESTER
 SG_ GCU_SupplierCode : 7|16@0+ (1.0,0.0) [0.0|65535.0] "" TESTER
 SG_ GCU_SwMajorVersion : 31|8@0+ (1.0,0.0) [0.0|255.0] "" TESTER
 SG_ GCU_SwMinorVersion : 39|8@0+ (1.0,0.0) [0.0|255.0] "" TESTER
 SG_ GCU_SwPatchVersion : 47|8@0+ (1.0,0.0) [0.0|255.0] "" TESTER
 SG_ GCU_SwVersionDay : 71|8@0+ (1.0,0.0) [0.0|31.0] "" TESTER
 SG_ GCU_SwVersionMonth : 63|8@0+ (1.0,0.0) [0.0|12.0] "" TESTER
 SG_ GCU_SwVersionYear : 55|8@0+ (1.0,0.0) [0.0|255.0] "" TESTER

BO_ 279 IPB_Wheel : 32 VIU0
 SG_ IPB_SumOfEdgeFLWSS : 71|16@0+ (1.0,0.0) [0.0|65535.0] "" PICU
 SG_ IPB_SumOfEdgeFLWSSValid : 199|1@0+ (1,0) [0|1] "" PICU
 SG_ IPB_SumOfEdgeFRWSS : 103|16@0+ (1.0,0.0) [0.0|65535.0] "" PICU
 SG_ IPB_SumOfEdgeFRWSSValid : 197|1@0+ (1,0) [0|1] "" PICU
 SG_ IPB_SumOfEdgeRLWSS : 135|16@0+ (1.0,0.0) [0.0|65535.0] "" PICU
 SG_ IPB_SumOfEdgeRLWSSValid : 195|1@0+ (1,0) [0|1] "" PICU
 SG_ IPB_SumOfEdgeRRWSS : 167|16@0+ (1.0,0.0) [0.0|65535.0] "" PICU
 SG_ IPB_SumOfEdgeRRWSSValid : 193|1@0+ (1,0) [0|1] "" PICU
 SG_ IPB_VehicleSpeed : 204|13@0+ (0.05625,0.0) [0.0|460.74375000000003] "km/h" BMS,CCU,PEU,PICU,TC
 SG_ IPB_VehicleSpeedValid : 205|1@0+ (1,0) [0|1] "" BMS,CCU,PEU,PICU,TC
 SG_ IPB_Wheel_Checksum : 7|16@0+ (1.0,0.0) [0.0|65535.0] "" PICU,TC
 SG_ IPB_Wheel_RollingCounter : 23|8@0+ (1.0,0.0) [0.0|255.0] "" PICU,TC
 SG_ IPB_WheelDirectionFL : 86|2@0+ (1,0) [0|3] "" PICU
 SG_ IPB_WheelDirectionFLValid : 87|1@0+ (1,0) [0|1] "" PICU
 SG_ IPB_WheelDirectionFR : 118|2@0+ (1,0) [0|3] "" PICU
 SG_ IPB_WheelDirectionFRValid : 119|1@0+ (1,0) [0|1] "" PICU
 SG_ IPB_WheelDirectionRL : 150|2@0+ (1,0) [0|3] "" PICU
 SG_ IPB_WheelDirectionRLValid : 151|1@0+ (1,0) [0|1] "" PICU
 SG_ IPB_WheelDirectionRR : 182|2@0+ (1,0) [0|3] "" PICU
 SG_ IPB_WheelDirectionRRValid : 183|1@0+ (1,0) [0|1] "" PICU
 SG_ IPB_WheelSpeedFL : 84|13@0+ (0.05625,0.0) [0.0|460.74375000000003] "km/h" PICU,TC
 SG_ IPB_WheelSpeedFLValid : 198|1@0+ (1,0) [0|1] "" PICU,TC
 SG_ IPB_WheelSpeedFR : 116|13@0+ (0.05625,0.0) [0.0|460.74375000000003] "km/h" PICU,TC
 SG_ IPB_WheelSpeedFRValid : 196|1@0+ (1,0) [0|1] "" PICU,TC
 SG_ IPB_WheelSpeedRL : 148|13@0+ (0.05625,0.0) [0.0|460.74375000000003] "km/h" PICU,TC
 SG_ IPB_WheelSpeedRLValid : 194|1@0+ (1,0) [0|1] "" PICU,TC
 SG_ IPB_WheelSpeedRR : 180|13@0+ (0.05625,0.0) [0.0|460.74375000000003] "km/h" PICU,TC
 SG_ IPB_WheelSpeedRRValid : 192|1@0+ (1,0) [0|1] "" PICU,TC

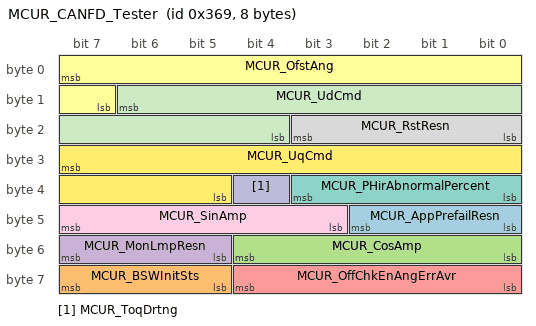
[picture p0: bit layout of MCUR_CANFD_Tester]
BO_ 873 MCUR_CANFD_Tester : 8 TC
 SG_ MCUR_AppPrefailResn : 42|3@0+ (1,0) [0|7] "" TESTER
 SG_ MCUR_BSWInitSts : 63|3@0+ (1.0,0.0) [0.0|7.0] "" TESTER
 SG_ MCUR_CosAmp : 52|5@0+ (0.1,0.0) [0.0|2.5] "" TESTER
 SG_ MCUR_MonLmpResn : 55|3@0+ (1.0,0.0) [0.0|7.0] "" TESTER
 SG_ MCUR_OffChkEnAngErrAvr : 60|5@0+ (1.0,0.0) [0.0|31.0] "" TESTER
 SG_ MCUR_OfstAng : 7|9@0+ (1.0,0.0) [0.0|360.0] "" TESTER
 SG_ MCUR_PHirAbnormalPercent : 35|4@0+ (10.0,0.0) [0.0|150.0] "" TESTER
 SG_ MCUR_RstResn : 19|4@0+ (1.0,0.0) [0.0|15.0] "" TESTER
 SG_ MCUR_SinAmp : 47|5@0+ (0.1,0.0) [0.0|2.5] "" TESTER
 SG_ MCUR_ToqDrtng : 36|1@0+ (1,0) [0|1] "" TESTER
 SG_ MCUR_UdCmd : 14|11@0+ (1.0,-1024.0) [-1024.0|1023.0] "" TESTER
 SG_ MCUR_UqCmd : 31|11@0+ (1.0,-1024.0) [-1024.0|1023.0] "" TESTER

BO_ 1305 MCUR_Fault : 32 TC
 SG_ MCUR_FaultNum1 : 23|12@0+ (1.0,0.0) [0.0|4095.0] "" VIU0
 SG_ MCUR_FaultNum10 : 123|12@0+ (1.0,0.0) [0.0|4095.0] "" VIU0
 SG_ MCUR_FaultNum11 : 143|12@0+ (1.0,0.0) [0.0|4095.0] "" VIU0
 SG_ MCUR_FaultNum12 : 147|12@0+ (1.0,0.0) [0.0|4095.0] "" VIU0
 SG_ MCUR_FaultNum13 : 167|12@0+ (1.0,0.0) [0.0|4095.0] "" VIU0
 SG_ MCUR_FaultNum14 : 171|12@0+ (1.0,0.0) [0.0|4095.0] "" VIU0
 SG_ MCUR_FaultNum15 : 191|12@0+ (1.0,0.0) [0.0|4095.0] "" VIU0
 SG_ MCUR_FaultNum16 : 195|12@0+ (1.0,0.0) [0.0|4095.0] "" VIU0
 SG_ MCUR_FaultNum17 : 215|12@0+ (1.0,0.0) [0.0|4095.0] "" VIU0
 SG_ MCUR_FaultNum18 : 219|12@0+ (1.0,0.0) [0.0|4095.0] "" VIU0
 SG_ MCUR_FaultNum19 : 239|12@0+ (1.0,0.0) [0.0|4095.0] "" VIU0
 SG_ MCUR_FaultNum2 : 27|12@0+ (1.0,0.0) [0.0|4095.0] "" VIU0
 SG_ MCUR_FaultNum20 : 243|12@0+ (1.0,0.0) [0.0|4095.0] "" VIU0
 SG_ MCUR_FaultNum3 : 47|12@0+ (1.0,0.0) [0.0|4095.0] "" VIU0
 SG_ MCUR_FaultNum4 : 51|12@0+ (1.0,0.0) [0.0|4095.0] "" VIU0
 SG_ MCUR_FaultNum5 : 71|12@0+ (1.0,0.0) [0.0|4095.0] "" VIU0
 SG_ MCUR_FaultNum6 : 75|12@0+ (1.0,0.0) [0.0|4095.0] "" VIU0
 SG_ MCUR_FaultNum7 : 95|12@0+ (1.0,0.0) [0.0|4095.0] "" VIU0
 SG_ MCUR_FaultNum8 : 99|12@0+ (1.0,0.0) [0.0|4095.0] "" VIU0
 SG_ MCUR_FaultNum9 : 119|12@0+ (1.0,0.0) [0.0|4095.0] "" VIU0
 SG_ MCUR_FrameIndex : 12|5@0+ (1.0,0.0) [0.0|31.0] "" VIU0
 SG_ MCUR_SupplierNum : 15|3@0+ (1.0,0.0) [0.0|7.0] "" VIU0
 SG_ MCUR_TotalFaultNum : 7|8@0+ (1.0,0.0) [0.0|255.0] "" VIU0

BO_ 262 MCUR_State_1 : 32 TC
 SG_ MCUR_ActRotSpd : 55|16@0+ (1.0,-32768.0) [-32768.0|32767.0] "rpm" PICU,VIU0
 SG_ MCUR_ActTq : 39|16@0+ (0.1,-3276.8) [-3276.8|3276.7] "Nm" PICU,VIU0
 SG_ MCUR_ActUnfilteredRotSpd : 119|16@0+ (1.0,-32768.0) [-32768.0|32767.0] "rpm" VIU0
 SG_ MCUR_BlkSt : 132|3@0+ (1,0) [0|7] "" VIU0
 SG_ MCUR_CompensationTq : 168|9@0+ (0.1,-25.5) [-25.5|25.6] "Nm" VIU0
 SG_ MCUR_DCB_CapDchaSts : 154|2@0+ (1,0) [0|3] "" BMS,VIU0
 SG_ MCUR_DCBoostChrgMaxOutpPwr : 151|10@0+ (1.0,0.0) [0.0|1000.0] "KW" VIU0
 SG_ MCUR_DCBoostChrgOperSts : 157|3@0+ (1,0) [0|7] "" VIU0
 SG_ MCUR_DischargeState : 170|2@0+ (1,0) [0|3] "" VIU0
 SG_ MCUR_FaultLevel : 191|3@0+ (1,0) [0|7] "" PICU,VIU0
 SG_ MCUR_FlowReq : 215|8@0+ (0.1,0.0) [0.0|25.5] "L/min" PICU
 SG_ MCUR_FlusSt : 173|3@0+ (1,0) [0|7] "" VIU0
 SG_ MCUR_HVIL_DCB_St : 141|2@0+ (1,0) [0|3] "" VIU0
 SG_ MCUR_IGBTmode : 186|2@0+ (1,0) [0|3] "" PICU,VIU0
 SG_ MCUR_IGBTOverTempWarn : 187|1@0+ (1,0) [0|1] "" VIU0
 SG_ MCUR_IGBTTempA : 239|8@0+ (1.0,-48.0) [-48.0|207.0] "℃" PICU,VIU0
 SG_ MCUR_IGBTTempB : 247|8@0+ (1.0,-48.0) [-48.0|207.0] "℃" PICU,VIU0
 SG_ MCUR_IGBTTempC : 255|8@0+ (1.0,-48.0) [-48.0|207.0] "℃" PICU,VIU0
 SG_ MCUR_MaxOutputDriveTq : 87|16@0+ (0.1,-3276.8) [-3276.8|3276.7] "Nm" VIU0
 SG_ MCUR_MaxOutputRegenTq : 103|16@0+ (0.1,-3276.8) [-3276.8|3276.7] "Nm" VIU0
 SG_ MCUR_MotOverTempWarn : 188|1@0+ (1,0) [0|1] "" VIU0
 SG_ MCUR_MotTemp : 223|8@0+ (1.0,-48.0) [-48.0|207.0] "℃" PICU,VIU0
 SG_ MCUR_MotWorkState : 31|4@0+ (1,0) [0|15] "" PICU,VIU0
 SG_ MCUR_OperMod : 27|4@0+ (1,0) [0|15] "" VIU0
 SG_ MCUR_RotorTemp : 231|8@0+ (1.0,-48.0) [-48.0|207.0] "℃" PICU,VIU0
 SG_ MCUR_RotSpdMaxLimit : 167|10@0+ (50.0,-20000.0) [-20000.0|20000.0] "rpm" VIU0
 SG_ MCUR_SpdModAvl : 152|1@0+ (1,0) [0|1] "" VIU0
 SG_ MCUR_SpdSVModFlt : 135|3@0+ (1,0) [0|7] "" VIU0
 SG_ MCUR_Standstill : 128|1@0+ (1,0) [0|1] "" VIU0
 SG_ MCUR_State_1_Checksum : 7|16@0+ (1.0,0.0) [0.0|65535.0] "" VIU0
 SG_ MCUR_State_1_Counter : 23|8@0+ (1.0,0.0) [0.0|255.0] "" VIU0
 SG_ MCUR_SVModAvl : 184|1@0+ (1,0) [0|1] "" VIU0
 SG_ MCUR_TarTq : 71|16@0+ (0.1,-3276.8) [-3276.8|3276.7] "Nm" VIU0
 SG_ MCUR_VehSldSt : 129|1@0+ (1,0) [0|1] "" VIU0

CM_ SG_ 1414 BMS_CellTSync "电芯温度同步参数";
CM_ SG_ 1414 BMS_SnsrT1 "探针温度值1";
CM_ SG_ 1414 BMS_SnsrT10 "探针温度值10";
CM_ SG_ 1414 BMS_SnsrT11 "探针温度值11";
CM_ SG_ 1414 BMS_SnsrT12 "探针温度值12";
CM_ SG_ 1414 BMS_SnsrT13 "探针温度值13";
CM_ SG_ 1414 BMS_SnsrT14 "探针温度值14";
CM_ SG_ 1414 BMS_SnsrT15 "探针温度值15";
CM_ SG_ 1414 BMS_SnsrT16 "探针温度值16";
CM_ SG_ 1414 BMS_SnsrT17 "探针温度值17";
CM_ SG_ 1414 BMS_SnsrT18 "探针温度值18";
CM_ SG_ 1414 BMS_SnsrT19 "探针温度值19";
CM_ SG_ 1414 BMS_SnsrT2 "探针温度值2";
CM_ SG_ 1414 BMS_SnsrT20 "探针温度值20";
CM_ SG_ 1414 BMS_SnsrT21 "探针温度值21";
CM_ SG_ 1414 BMS_SnsrT22 "探针温度值22";
CM_ SG_ 1414 BMS_SnsrT23 "探针温度值23";
CM_ SG_ 1414 BMS_SnsrT24 "探针温度值24";
CM_ SG_ 1414 BMS_SnsrT25 "探针温度值25";
CM_ SG_ 1414 BMS_SnsrT26 "探针温度值26";
CM_ SG_ 1414 BMS_SnsrT27 "探针温度值27";
CM_ SG_ 1414 BMS_SnsrT28 "探针温度值28";
CM_ SG_ 1414 BMS_SnsrT29 "探针温度值29";
CM_ SG_ 1414 BMS_SnsrT3 "探针温度值3";
CM_ SG_ 1414 BMS_SnsrT30 "探针温度值30";
CM_ SG_ 1414 BMS_SnsrT31 "探针温度值31";
CM_ SG_ 1414 BMS_SnsrT32 "探针温度值32";
CM_ SG_ 1414 BMS_SnsrT33 "探针温度值33";
CM_ SG_ 1414 BMS_SnsrT34 "探针温度值34";
CM_ SG_ 1414 BMS_SnsrT35 "探针温度值35";
CM_ SG_ 1414 BMS_SnsrT36 "探针温度值36";
CM_ SG_ 1414 BMS_SnsrT37 "探针温度值37";
CM_ SG_ 1414 BMS_SnsrT38 "探针温度值38";
CM_ SG_ 1414 BMS_SnsrT39 "探针温度值39";
CM_ SG_ 1414 BMS_SnsrT4 "探针温度值4";
CM_ SG_ 1414 BMS_SnsrT40 "探针温度值40";
CM_ SG_ 1414 BMS_SnsrT41 "探针温度值41";
CM_ SG_ 1414 BMS_SnsrT42 "探针温度值42";
CM_ SG_ 1414 BMS_SnsrT43 "探针温度值43";
CM_ SG_ 1414 BMS_SnsrT44 "探针温度值44";
CM_ SG_ 1414 BMS_SnsrT45 "探针温度值45";
CM_ SG_ 1414 BMS_SnsrT46 "探针温度值46";
CM_ SG_ 1414 BMS_SnsrT47 "探针温度值47";
CM_ SG_ 1414 BMS_SnsrT48 "探针温度值48";
CM_ SG_ 1414 BMS_SnsrT49 "探针温度值49";
CM_ SG_ 1414 BMS_SnsrT5 "探针温度值5";
CM_ SG_ 1414 BMS_SnsrT50 "探针温度值50";
CM_ SG_ 1414 BMS_SnsrT51 "探针温度值51";
CM_ SG_ 1414 BMS_SnsrT52 "探针温度值52";
CM_ SG_ 1414 BMS_SnsrT53 "探针温度值53";
CM_ SG_ 1414 BMS_SnsrT54 "探针温度值54";
CM_ SG_ 1414 BMS_SnsrT55 "探针温度值55";
CM_ SG_ 1414 BMS_SnsrT56 "探针温度值56";
CM_ SG_ 1414 BMS_SnsrT57 "探针温度值57";
CM_ SG_ 1414 BMS_SnsrT58 "探针温度值58";
CM_ SG_ 1414 BMS_SnsrT59 "探针温度值59";
CM_ SG_ 1414 BMS_SnsrT6 "探针温度值6";
CM_ SG_ 1414 BMS_SnsrT60 "探针温度值60";
CM_ SG_ 1414 BMS_SnsrT61 "探针温度值61";
CM_ SG_ 1414 BMS_SnsrT62 "探针温度值62";
CM_ SG_ 1414 BMS_SnsrT63 "探针温度值63";
CM_ SG_ 1414 BMS_SnsrT7 "探针温度值7";
CM_ SG_ 1414 BMS_SnsrT8 "探针温度值8";
CM_ SG_ 1414 BMS_SnsrT9 "探针温度值9";
CM_ SG_ 1457 BMS_CanMatrixMajorVersion "通讯矩阵主版本";
CM_ SG_ 1457 BMS_CanMatrixMinorVersion "通讯矩阵子版本";
CM_ SG_ 1457 BMS_CanMatrixPatchVersion "通讯矩阵版补充本";
CM_ SG_ 1457 BMS_CellPrmTblMajorVersion "电芯参数表主版本";
CM_ SG_ 1457 BMS_CellPrmTblMinorVersion "电芯参数表子版本";
CM_ SG_ 1457 BMS_CellPrmTblPatchVersion "电芯参数表补充版本";
CM_ SG_ 1457 BMS_FltDiagTblMajorVersion "故障诊断表主版本";
CM_ SG_ 1457 BMS_FltDiagTblMinorVersion "故障诊断表子版本";
CM_ SG_ 1457 BMS_FltDiagTblPatchVersion "故障诊断表补充版本";
CM_ SG_ 1457 BMS_HwVersion "硬件版本号";
CM_ SG_ 1457 BMS_SupplierCode "供应商代码";
CM_ SG_ 1457 BMS_SwMajorVersion "软件主版本号";
CM_ SG_ 1457 BMS_SwMinorVersion "软件子版本号";
CM_ SG_ 1457 BMS_SwPatchVersion "软件补充版本号";
CM_ SG_ 1457 BMS_SwVersionDay "软件版本日";
CM_ SG_ 1457 BMS_SwVersionMonth "软件版本月";
CM_ SG_ 1457 BMS_SwVersionYear "软件版本年-2000";
CM_ SG_ 1409 BMS_CellU1 "蓄电池单体电压(1)";
CM_ SG_ 1409 BMS_CellU10 "蓄电池单体电压(10)";
CM_ SG_ 1409 BMS_CellU11 "蓄电池单体电压(11)";
CM_ SG_ 1409 BMS_CellU12 "蓄电池单体电压(12)";
CM_ SG_ 1409 BMS_CellU13 "蓄电池单体电压(13)";
CM_ SG_ 1409 BMS_CellU14 "蓄电池单体电压(14)";
CM_ SG_ 1409 BMS_CellU15 "蓄电池单体电压(15)";
CM_ SG_ 1409 BMS_CellU16 "蓄电池单体电压(16)";
CM_ SG_ 1409 BMS_CellU17 "蓄电池单体电压(17)";
CM_ SG_ 1409 BMS_CellU18 "蓄电池单体电压(18)";
CM_ SG_ 1409 BMS_CellU19 "蓄电池单体电压(19)";
CM_ SG_ 1409 BMS_CellU2 "蓄电池单体电压(2)";
CM_ SG_ 1409 BMS_CellU20 "蓄电池单体电压(20)";
CM_ SG_ 1409 BMS_CellU21 "蓄电池单体电压(21)";
CM_ SG_ 1409 BMS_CellU22 "蓄电池单体电压(22)";
CM_ SG_ 1409 BMS_CellU23 "蓄电池单体电压(23)";
CM_ SG_ 1409 BMS_CellU24 "蓄电池单体电压(24)";
CM_ SG_ 1409 BMS_CellU25 "蓄电池单体电压(25)";
CM_ SG_ 1409 BMS_CellU26 "蓄电池单体电压(26)";
CM_ SG_ 1409 BMS_CellU27 "蓄电池单体电压(27)";
CM_ SG_ 1409 BMS_CellU28 "蓄电池单体电压(28)";
CM_ SG_ 1409 BMS_CellU29 "蓄电池单体电压(29)";
CM_ SG_ 1409 BMS_CellU3 "蓄电池单体电压(3)";
CM_ SG_ 1409 BMS_CellU30 "蓄电池单体电压(30)";
CM_ SG_ 1409 BMS_CellU31 "蓄电池单体电压(31)";
CM_ SG_ 1409 BMS_CellU32 "蓄电池单体电压(32)";
CM_ SG_ 1409 BMS_CellU33 "蓄电池单体电压(33)";
CM_ SG_ 1409 BMS_CellU34 "蓄电池单体电压(34)";
CM_ SG_ 1409 BMS_CellU35 "蓄电池单体电压(35)";
CM_ SG_ 1409 BMS_CellU36 "蓄电池单体电压(36)";
CM_ SG_ 1409 BMS_CellU37 "蓄电池单体电压(37)";
CM_ SG_ 1409 BMS_CellU38 "蓄电池单体电压(38)";
CM_ SG_ 1409 BMS_CellU39 "蓄电池单体电压(39)";
CM_ SG_ 1409 BMS_CellU4 "蓄电池单体电压(4)";
CM_ SG_ 1409 BMS_CellU5 "蓄电池单体电压(5)";
CM_ SG_ 1409 BMS_CellU6 "蓄电池单体电压(6)";
CM_ SG_ 1409 BMS_CellU7 "蓄电池单体电压(7)";
CM_ SG_ 1409 BMS_CellU8 "蓄电池单体电压(8)";
CM_ SG_ 1409 BMS_CellU9 "蓄电池单体电压(9)";
CM_ SG_ 1409 BMS_CellUSync1 "电芯电压同步参数1";
CM_ SG_ 1410 BMS_CellU40 "蓄电池单体电压(40)";
CM_ SG_ 1410 BMS_CellU41 "蓄电池单体电压(41)";
CM_ SG_ 1410 BMS_CellU42 "蓄电池单体电压(42)";
CM_ SG_ 1410 BMS_CellU43 "蓄电池单体电压(43)";
CM_ SG_ 1410 BMS_CellU44 "蓄电池单体电压(44)";
CM_ SG_ 1410 BMS_CellU45 "蓄电池单体电压(45)";
CM_ SG_ 1410 BMS_CellU46 "蓄电池单体电压(46)";
CM_ SG_ 1410 BMS_CellU47 "蓄电池单体电压(47)";
CM_ SG_ 1410 BMS_CellU48 "蓄电池单体电压(48)";
CM_ SG_ 1410 BMS_CellU49 "蓄电池单体电压(49)";
CM_ SG_ 1410 BMS_CellU50 "蓄电池单体电压(50)";
CM_ SG_ 1410 BMS_CellU51 "蓄电池单体电压(51)";
CM_ SG_ 1410 BMS_CellU52 "蓄电池单体电压(52)";
CM_ SG_ 1410 BMS_CellU53 "蓄电池单体电压(53)";
CM_ SG_ 1410 BMS_CellU54 "蓄电池单体电压(54)";
CM_ SG_ 1410 BMS_CellU55 "蓄电池单体电压(55)";
CM_ SG_ 1410 BMS_CellU56 "蓄电池单体电压(56)";
CM_ SG_ 1410 BMS_CellU57 "蓄电池单体电压(57)";
CM_ SG_ 1410 BMS_CellU58 "蓄电池单体电压(58)";
CM_ SG_ 1410 BMS_CellU59 "蓄电池单体电压(59)";
CM_ SG_ 1410 BMS_CellU60 "蓄电池单体电压(60)";
CM_ SG_ 1410 BMS_CellU61 "蓄电池单体电压(61)";
CM_ SG_ 1410 BMS_CellU62 "蓄电池单体电压(62)";
CM_ SG_ 1410 BMS_CellU63 "蓄电池单体电压(63)";
CM_ SG_ 1410 BMS_CellU64 "蓄电池单体电压(64)";
CM_ SG_ 1410 BMS_CellU65 "蓄电池单体电压(65)";
CM_ SG_ 1410 BMS_CellU66 "蓄电池单体电压(66)";
CM_ SG_ 1410 BMS_CellU67 "蓄电池单体电压(67)";
CM_ SG_ 1410 BMS_CellU68 "蓄电池单体电压(68)";
CM_ SG_ 1410 BMS_CellU69 "蓄电池单体电压(69)";
CM_ SG_ 1410 BMS_CellU70 "蓄电池单体电压(70)";
CM_ SG_ 1410 BMS_CellU71 "蓄电池单体电压(71)";
CM_ SG_ 1410 BMS_CellU72 "蓄电池单体电压(72)";
CM_ SG_ 1410 BMS_CellU73 "蓄电池单体电压(73)";
CM_ SG_ 1410 BMS_CellU74 "蓄电池单体电压(74)";
CM_ SG_ 1410 BMS_CellU75 "蓄电池单体电压(75)";
CM_ SG_ 1410 BMS_CellU76 "蓄电池单体电压(76)";
CM_ SG_ 1410 BMS_CellU77 "蓄电池单体电压(77)";
CM_ SG_ 1410 BMS_CellU78 "蓄电池单体电压(78)";
CM_ SG_ 1410 BMS_CellUSync2 "电芯电压同步参数2";
CM_ SG_ 1411 BMS_CellU100 "蓄电池单体电压(100)";
CM_ SG_ 1411 BMS_CellU101 "蓄电池单体电压(101)";
CM_ SG_ 1411 BMS_CellU102 "蓄电池单体电压(102)";
CM_ SG_ 1411 BMS_CellU103 "蓄电池单体电压(103)";
CM_ SG_ 1411 BMS_CellU104 "蓄电池单体电压(104)";
CM_ SG_ 1411 BMS_CellU105 "蓄电池单体电压(105)";
CM_ SG_ 1411 BMS_CellU106 "蓄电池单体电压(106)";
CM_ SG_ 1411 BMS_CellU107 "蓄电池单体电压(107)";
CM_ SG_ 1411 BMS_CellU108 "蓄电池单体电压(108)";
CM_ SG_ 1411 BMS_CellU109 "蓄电池单体电压(109)";
CM_ SG_ 1411 BMS_CellU110 "蓄电池单体电压(110)";
CM_ SG_ 1411 BMS_CellU111 "蓄电池单体电压(111)";
CM_ SG_ 1411 BMS_CellU112 "蓄电池单体电压(112)";
CM_ SG_ 1411 BMS_CellU113 "蓄电池单体电压(113)";
CM_ SG_ 1411 BMS_CellU114 "蓄电池单体电压(114)";
CM_ SG_ 1411 BMS_CellU115 "蓄电池单体电压(115)";
CM_ SG_ 1411 BMS_CellU116 "蓄电池单体电压(116)";
CM_ SG_ 1411 BMS_CellU117 "蓄电池单体电压(117)";
CM_ SG_ 1411 BMS_CellU79 "蓄电池单体电压(79)";
CM_ SG_ 1411 BMS_CellU80 "蓄电池单体电压(80)";
CM_ SG_ 1411 BMS_CellU81 "蓄电池单体电压(81)";
CM_ SG_ 1411 BMS_CellU82 "蓄电池单体电压(82)";
CM_ SG_ 1411 BMS_CellU83 "蓄电池单体电压(83)";
CM_ SG_ 1411 BMS_CellU84 "蓄电池单体电压(84)";
CM_ SG_ 1411 BMS_CellU85 "蓄电池单体电压(85)";
CM_ SG_ 1411 BMS_CellU86 "蓄电池单体电压(86)";
CM_ SG_ 1411 BMS_CellU87 "蓄电池单体电压(87)";
CM_ SG_ 1411 BMS_CellU88 "蓄电池单体电压(88)";
CM_ SG_ 1411 BMS_CellU89 "蓄电池单体电压(89)";
CM_ SG_ 1411 BMS_CellU90 "蓄电池单体电压(90)";
CM_ SG_ 1411 BMS_CellU91 "蓄电池单体电压(91)";
CM_ SG_ 1411 BMS_CellU92 "蓄电池单体电压(92)";
CM_ SG_ 1411 BMS_CellU93 "蓄电池单体电压(93)";
CM_ SG_ 1411 BMS_CellU94 "蓄电池单体电压(94)";
CM_ SG_ 1411 BMS_CellU95 "蓄电池单体电压(95)";
CM_ SG_ 1411 BMS_CellU96 "蓄电池单体电压(96)";
CM_ SG_ 1411 BMS_CellU97 "蓄电池单体电压(97)";
CM_ SG_ 1411 BMS_CellU98 "蓄电池单体电压(98)";
CM_ SG_ 1411 BMS_CellU99 "蓄电池单体电压(99)";
CM_ SG_ 1411 BMS_CellUSync3 "电芯电压同步参数3";
CM_ SG_ 1412 BMS_CellU118 "蓄电池单体电压(118)";
CM_ SG_ 1412 BMS_CellU119 "蓄电池单体电压(119)";
CM_ SG_ 1412 BMS_CellU120 "蓄电池单体电压(120)";
CM_ SG_ 1412 BMS_CellU121 "蓄电池单体电压(121)";
CM_ SG_ 1412 BMS_CellU122 "蓄电池单体电压(122)";
CM_ SG_ 1412 BMS_CellU123 "蓄电池单体电压(123)";
CM_ SG_ 1412 BMS_CellU124 "蓄电池单体电压(124)";
CM_ SG_ 1412 BMS_CellU125 "蓄电池单体电压(125)";
CM_ SG_ 1412 BMS_CellU126 "蓄电池单体电压(126)";
CM_ SG_ 1412 BMS_CellU127 "蓄电池单体电压(127)";
CM_ SG_ 1412 BMS_CellU128 "蓄电池单体电压(128)";
CM_ SG_ 1412 BMS_CellU129 "蓄电池单体电压(129)";
CM_ SG_ 1412 BMS_CellU130 "蓄电池单体电压(130)";
CM_ SG_ 1412 BMS_CellU131 "蓄电池单体电压(131)";
CM_ SG_ 1412 BMS_CellU132 "蓄电池单体电压(132)";
CM_ SG_ 1412 BMS_CellU133 "蓄电池单体电压(133)";
CM_ SG_ 1412 BMS_CellU134 "蓄电池单体电压(134)";
CM_ SG_ 1412 BMS_CellU135 "蓄电池单体电压(135)";
CM_ SG_ 1412 BMS_CellU136 "蓄电池单体电压(136)";
CM_ SG_ 1412 BMS_CellU137 "蓄电池单体电压(137)";
CM_ SG_ 1412 BMS_CellU138 "蓄电池单体电压(138)";
CM_ SG_ 1412 BMS_CellU139 "蓄电池单体电压(139)";
CM_ SG_ 1412 BMS_CellU140 "蓄电池单体电压(140)";
CM_ SG_ 1412 BMS_CellU141 "蓄电池单体电压(141)";
CM_ SG_ 1412 BMS_CellU142 "蓄电池单体电压(142)";
CM_ SG_ 1412 BMS_CellU143 "蓄电池单体电压(143)";
CM_ SG_ 1412 BMS_CellU144 "蓄电池单体电压(144)";
CM_ SG_ 1412 BMS_CellU145 "蓄电池单体电压(145)";
CM_ SG_ 1412 BMS_CellU146 "蓄电池单体电压(146)";
CM_ SG_ 1412 BMS_CellU147 "蓄电池单体电压(147)";
CM_ SG_ 1412 BMS_CellU148 "蓄电池单体电压(148)";
CM_ SG_ 1412 BMS_CellU149 "蓄电池单体电压(149)";
CM_ SG_ 1412 BMS_CellU150 "蓄电池单体电压(150)";
CM_ SG_ 1412 BMS_CellU151 "蓄电池单体电压(151)";
CM_ SG_ 1412 BMS_CellU152 "蓄电池单体电压(152)";
CM_ SG_ 1412 BMS_CellU153 "蓄电池单体电压(153)";
CM_ SG_ 1412 BMS_CellU154 "蓄电池单体电压(154)";
CM_ SG_ 1412 BMS_CellU155 "蓄电池单体电压(155)";
CM_ SG_ 1412 BMS_CellU156 "蓄电池单体电压(156)";
CM_ SG_ 1412 BMS_CellUSync4 "电芯电压同步参数4";
CM_ SG_ 1413 BMS_CellU157 "蓄电池单体电压(157)";
CM_ SG_ 1413 BMS_CellU158 "蓄电池单体电压(158)";
CM_ SG_ 1413 BMS_CellU159 "蓄电池单体电压(159)";
CM_ SG_ 1413 BMS_CellU160 "蓄电池单体电压(160)";
CM_ SG_ 1413 BMS_CellU161 "蓄电池单体电压(161)";
CM_ SG_ 1413 BMS_CellU162 "蓄电池单体电压(162)";
CM_ SG_ 1413 BMS_CellU163 "蓄电池单体电压(163)";
CM_ SG_ 1413 BMS_CellU164 "蓄电池单体电压(164)";
CM_ SG_ 1413 BMS_CellU165 "蓄电池单体电压(165)";
CM_ SG_ 1413 BMS_CellU166 "蓄电池单体电压(166)";
CM_ SG_ 1413 BMS_CellU167 "蓄电池单体电压(167)";
CM_ SG_ 1413 BMS_CellU168 "蓄电池单体电压(168)";
CM_ SG_ 1413 BMS_CellU169 "蓄电池单体电压(169)";
CM_ SG_ 1413 BMS_CellU170 "蓄电池单体电压(170)";
CM_ SG_ 1413 BMS_CellU171 "蓄电池单体电压(171)";
CM_ SG_ 1413 BMS_CellU172 "蓄电池单体电压(172)";
CM_ SG_ 1413 BMS_CellU173 "蓄电池单体电压(173)";
CM_ SG_ 1413 BMS_CellU174 "蓄电池单体电压(174)";
CM_ SG_ 1413 BMS_CellU175 "蓄电池单体电压(175)";
CM_ SG_ 1413 BMS_CellU176 "蓄电池单体电压(176)";
CM_ SG_ 1413 BMS_CellU177 "蓄电池单体电压(177)";
CM_ SG_ 1413 BMS_CellU178 "蓄电池单体电压(178)";
CM_ SG_ 1413 BMS_CellU179 "蓄电池单体电压(179)";
CM_ SG_ 1413 BMS_CellU180 "蓄电池单体电压(180)";
CM_ SG_ 1413 BMS_CellU181 "蓄电池单体电压(181)";
CM_ SG_ 1413 BMS_CellU182 "蓄电池单体电压(182)";
CM_ SG_ 1413 BMS_CellU183 "蓄电池单体电压(183)";
CM_ SG_ 1413 BMS_CellU184 "蓄电池单体电压(184)";
CM_ SG_ 1413 BMS_CellU185 "蓄电池单体电压(185)";
CM_ SG_ 1413 BMS_CellU186 "蓄电池单体电压(186)";
CM_ SG_ 1413 BMS_CellU187 "蓄电池单体电压(187)";
CM_ SG_ 1413 BMS_CellU188 "蓄电池单体电压(188)";
CM_ SG_ 1413 BMS_CellU189 "蓄电池单体电压(189)";
CM_ SG_ 1413 BMS_CellU190 "蓄电池单体电压(190)";
CM_ SG_ 1413 BMS_CellU191 "蓄电池单体电压(191)";
CM_ SG_ 1413 BMS_CellU192 "蓄电池单体电压(192)";
CM_ SG_ 1413 BMS_CellUSync5 "电芯电压同步参数5";
CM_ SG_ 1418 CDU_APS_PortA_Currt1 "APS 端口A电流1";
CM_ SG_ 1418 CDU_APS_PortA_Currt2 "APS 端口A电流2";
CM_ SG_ 1418 CDU_APS_PortA_Currt3 "APS 端口A电流3";
CM_ SG_ 1418 CDU_APS_PortA_U1 "APS 端口A电压1";
CM_ SG_ 1418 CDU_APS_PortA_U2 "APS 端口A电压2";
CM_ SG_ 1418 CDU_APS_PortB_Currt_DCDC "DCDC侧计算的PortB电流";
CM_ SG_ 1418 CDU_APS_PortB_Currt_Sfty "功能安全侧计算的PortB电流";
CM_ SG_ 1418 CDU_APS_PortB_U1 "APS 端口B电压1";
CM_ SG_ 1418 CDU_APS_PortB_U2 "APS 端口B电压2";
CM_ SG_ 1418 CDU_APS_SIGN "APS标记";
CM_ SG_ 1418 CDU_DetailedFltInfo "CDU详细故障信息汇总";
CM_ SG_ 787 CDU_DCDC_Checksum "CRC16 checksum  (DataID: 0x8313)";
CM_ SG_ 787 CDU_DCDC_Counter "Rolling Counter";
CM_ SG_ 787 DCDC_AlerSt "DCDC状态报警";
CM_ SG_ 787 DCDC_CopntTemp "DCDC器件温度";
CM_ SG_ 787 DCDC_DeratFlag "DCDC降额工作标志";
CM_ SG_ 787 DCDC_DeratReason1 "DCDC输入低压或高压降额";
CM_ SG_ 787 DCDC_DeratReason10 "DCDC降额工作原因10";
CM_ SG_ 787 DCDC_DeratReason11 "DCDC降额工作原因11";
CM_ SG_ 787 DCDC_DeratReason12 "DCDC降额工作原因12";
CM_ SG_ 787 DCDC_DeratReason2 "DCDC输出低压降额";
CM_ SG_ 787 DCDC_DeratReason3 "DCDC冷却液高温降额";
CM_ SG_ 787 DCDC_DeratReason4 "DCDC内部过温降额";
CM_ SG_ 787 DCDC_DeratReason5 "DCDC降额工作原因5";
CM_ SG_ 787 DCDC_DeratReason6 "DCDC降额工作原因6";
CM_ SG_ 787 DCDC_DeratReason7 "DCDC降额工作原因7";
CM_ SG_ 787 DCDC_DeratReason8 "DCDC降额工作原因8";
CM_ SG_ 787 DCDC_DeratReason9 "DCDC降额工作原因9";
CM_ SG_ 787 DCDC_EnergyConvrtDir "DCDC能量转换方向";
CM_ SG_ 787 DCDC_FaultLevel "DCDC故障等级";
CM_ SG_ 787 DCDC_FaultLightReq "DCDC故障灯点亮请求";
CM_ SG_ 787 DCDC_FlowReq "DCDC/OBC冷却液流量请求";
CM_ SG_ 787 DCDC_HVIL_48VDCDC_St "DCDC 48VDCDC接口高压互锁状态(预留)";
CM_ SG_ 787 DCDC_HVIL_Batt_St "DCDC 电池接口高压互锁状态";
CM_ SG_ 787 DCDC_HVIL_EAS_St "DCDC 压缩机接口高压互锁状态(预留)";
CM_ SG_ 787 DCDC_HVIL_MCU_St "DCDC MCU接口高压互锁状态(EVR)";
CM_ SG_ 787 DCDC_HVIL_PTC_St "DCDC PTC接口高压互锁状态(预留)";
CM_ SG_ 787 DCDC_HVIL_PTCR_St "DCDC PTCR接口高压互锁状态(预留)";
CM_ SG_ 787 DCDC_InpWtrTemp "DCDC/OBC入水口温度";
CM_ SG_ 787 DCDC_IptCurrt "DCDC输入电流";
CM_ SG_ 787 DCDC_IptVolt "DCDC输入电压";
CM_ SG_ 787 DCDC_LoopOut "DCDC环路值(仅用于问题定位)";
CM_ SG_ 787 DCDC_LvSidePwr "DCDC低压侧功率";
CM_ SG_ 787 DCDC_MaxOptPwr "DCDC最大输出功率";
CM_ SG_ 787 DCDC_NoLoadCurrtFlag "DCDC空载电流标志位";
CM_ SG_ 787 DCDC_OperSt "DCDC工作状态";
CM_ SG_ 787 DCDC_OptCurrt "DCDC 输出电流";
CM_ SG_ 787 DCDC_OptVolt "DCDC输出电压";
CM_ SG_ 787 DCDC_Oring_APS_Temp "DCDC oring/APS管温度";
CM_ SG_ 787 DCDC_OutWtrTemp "DCDC/OBC出水口温度";
CM_ SG_ 787 DCDC_OverTemp "DCDC温度报警";
CM_ SG_ 787 DCDC_PeakPwrTi "DCDC峰值功率时间";
CM_ SG_ 787 DCDC_PNGSt "PNG开关状态";
CM_ SG_ 1306 CDU_FaultNum1 "故障编号1";
CM_ SG_ 1306 CDU_FaultNum10 "故障编号10";
CM_ SG_ 1306 CDU_FaultNum11 "故障编号11";
CM_ SG_ 1306 CDU_FaultNum12 "故障编号12";
CM_ SG_ 1306 CDU_FaultNum13 "故障编号13";
CM_ SG_ 1306 CDU_FaultNum14 "故障编号14";
CM_ SG_ 1306 CDU_FaultNum15 "故障编号15";
CM_ SG_ 1306 CDU_FaultNum16 "故障编号16";
CM_ SG_ 1306 CDU_FaultNum17 "故障编号17";
CM_ SG_ 1306 CDU_FaultNum18 "故障编号18";
CM_ SG_ 1306 CDU_FaultNum19 "故障编号19";
CM_ SG_ 1306 CDU_FaultNum2 "故障编号2";
CM_ SG_ 1306 CDU_FaultNum20 "故障编号20";
CM_ SG_ 1306 CDU_FaultNum3 "故障编号3";
CM_ SG_ 1306 CDU_FaultNum4 "故障编号4";
CM_ SG_ 1306 CDU_FaultNum5 "故障编号5";
CM_ SG_ 1306 CDU_FaultNum6 "故障编号6";
CM_ SG_ 1306 CDU_FaultNum7 "故障编号7";
CM_ SG_ 1306 CDU_FaultNum8 "故障编号8";
CM_ SG_ 1306 CDU_FaultNum9 "故障编号9";
CM_ SG_ 1306 CDU_FrameIndex "帧序号";
CM_ SG_ 1306 CDU_SupplierNum "供应商代码";
CM_ SG_ 1306 CDU_TotalFaultNum "当前故障总数";
CM_ SG_ 790 CDU_OBC_1_Checksum "CRC16 checksum  (DataID: 0x8316)";
CM_ SG_ 790 CDU_OBC_1_Counter "Rolling Counter";
CM_ SG_ 790 OBC_ACInpFrq "交流输入电压频率";
CM_ SG_ 790 OBC_AcIptSts "OBC交流输入状态";
CM_ SG_ 790 OBC_AcIptType "OBC交流输入形式";
CM_ SG_ 790 OBC_CCRes "OBCCC阻值";
CM_ SG_ 790 OBC_ChrgDischrgStep "OBC充放电阶段(预留)";
CM_ SG_ 790 OBC_ChrgGunCCSts "OBC充电枪CC状态";
CM_ SG_ 790 OBC_CopntTemp "OBC器件温度";
CM_ SG_ 790 OBC_CPDuty "OBC接收CP占空比";
CM_ SG_ 790 OBC_CPFreqSts "OBC接收CP频率状态";
CM_ SG_ 790 OBC_CPFrq "CP占空比实际频率";
CM_ SG_ 790 OBC_CPOutpDuty "OBC输出CP占空比";
CM_ SG_ 790 OBC_CPOutpVolt "OBC输出CP电压峰值";
CM_ SG_ 790 OBC_CPSts "OBCCP信号状态";
CM_ SG_ 790 OBC_CPValidSt "CP有效状态";
CM_ SG_ 790 OBC_CPVolt "OBCCP电压峰值";
CM_ SG_ 790 OBC_DeratFlag "OBC降额工作标志";
CM_ SG_ 790 OBC_DeratReason1 "PFC母线电压过低降额保护";
CM_ SG_ 790 OBC_DeratReason10 "充电/逆变内部过温降额";
CM_ SG_ 790 OBC_DeratReason11 "弱电网降额";
CM_ SG_ 790 OBC_DeratReason12 "OBC降额工作原因12";
CM_ SG_ 790 OBC_DeratReason13 "OBC降额工作原因13";
CM_ SG_ 790 OBC_DeratReason14 "OBC降额工作原因14";
CM_ SG_ 790 OBC_DeratReason15 "OBC降额工作原因15";
CM_ SG_ 790 OBC_DeratReason16 "OBC降额工作原因16";
CM_ SG_ 790 OBC_DeratReason17 "OBC降额工作原因17";
CM_ SG_ 790 OBC_DeratReason18 "OBC降额工作原因18";
CM_ SG_ 790 OBC_DeratReason19 "OBC降额工作原因19";
CM_ SG_ 790 OBC_DeratReason2 "充电输入低压降额";
CM_ SG_ 790 OBC_DeratReason20 "OBC降额工作原因20";
CM_ SG_ 790 OBC_DeratReason21 "OBC降额工作原因21";
CM_ SG_ 790 OBC_DeratReason22 "OBC降额工作原因22";
CM_ SG_ 790 OBC_DeratReason23 "OBC降额工作原因23";
CM_ SG_ 790 OBC_DeratReason24 "OBC降额工作原因24";
CM_ SG_ 790 OBC_DeratReason3 "充电输入高压降额";
CM_ SG_ 790 OBC_DeratReason4 "充电输出电压过低降额";
CM_ SG_ 790 OBC_DeratReason5 "充电输出电压过高降额";
CM_ SG_ 790 OBC_DeratReason6 "充电内部环温过低降额";
CM_ SG_ 790 OBC_DeratReason7 "充电冷却液高温降额";
CM_ SG_ 790 OBC_DeratReason8 "逆变冷却液高温降额";
CM_ SG_ 790 OBC_DeratReason9 "逆变输入低压或高压降额";
CM_ SG_ 790 OBC_DischrgLoadForm "OBC放电负载形式";
CM_ SG_ 790 OBC_DisWorkMode "OBC车内逆变工作模式";
CM_ SG_ 790 OBC_EnergyConvrtDir "OBC能量转换方向";
CM_ SG_ 790 OBC_FastChargeRelayNegSts "快充继电器负极状态(EVR)";
CM_ SG_ 790 OBC_FastChargeRelayPosSts "快充继电器正极状态 (EVR)";
CM_ SG_ 790 OBC_FastChrgRelayNeg_Extd_U "快充继电器负极外部采样电压(仅用于问题定位)";
CM_ SG_ 790 OBC_FastChrgRelayPos_Extd_U "快充继电器正极外部采样电压(仅用于问题定位)";
CM_ SG_ 790 OBC_FaultLevel "OBC故障等级";
CM_ SG_ 790 OBC_FaultLightReq "OBC故障灯点亮请求";
CM_ SG_ 790 OBC_HVIL_AC_St "OBC 交流充放电接口高压互锁状态";
CM_ SG_ 790 OBC_HVIL_DC_St "OBC 直流充放电接口高压互锁状态(EVR)";
CM_ SG_ 790 OBC_InsulationR "逆变绝缘检测阻值(仅用于问题定位)";
CM_ SG_ 790 OBC_OperSt "OBC工作状态";
CM_ SG_ 790 OBC_RatedPwrLevel "OBC额定功率等级";
CM_ SG_ 790 OBC_S1Sts "OBC S1开关状态";
CM_ SG_ 790 OBC_S2Sts "OBC S2开关状态";
CM_ SG_ 790 OBC_S4Sts "OBC S4开关状态";
CM_ SG_ 790 OBC_WorkMode "OBC工作模式";
CM_ SG_ 794 CDU_KL15_Volt "KL15电压(仅用于问题定位)";
CM_ SG_ 794 CDU_KL30_Volt "KL30电压(仅用于问题定位)";
CM_ SG_ 794 OBC_ACL1Currt "OBC交流侧L1相电流";
CM_ SG_ 794 OBC_ACL1Volt "OBC交流侧L1相电压";
CM_ SG_ 794 OBC_ACL2Currt "OBC交流侧L2相电流";
CM_ SG_ 794 OBC_ACL2Volt "OBC交流侧L2相电压";
CM_ SG_ 794 OBC_ACL3Currt "OBC交流侧L3相电流";
CM_ SG_ 794 OBC_ACL3Volt "OBC交流侧L3相电压";
CM_ SG_ 794 OBC_ACPileMaxCurrt "交流充电桩允许最大电流";
CM_ SG_ 794 OBC_ACPwr "OBC交流侧功率";
CM_ SG_ 794 OBC_ChrgCablePermitCurrt "OBC充电线缆额定电流";
CM_ SG_ 794 OBC_ChrgEndNum "OBC充电结束码";
CM_ SG_ 794 OBC_ChrgOptMaxCurrt "OBC充电输出最大电流";
CM_ SG_ 794 OBC_ChrgOptMaxPwr "OBC充电输出最大功率";
CM_ SG_ 794 OBC_ChrgOptMaxVolt "OBC充电输出最大电压";
CM_ SG_ 794 OBC_ChrgOptMinVolt "OBC充电输出最小电压";
CM_ SG_ 794 OBC_DCChrgMod_LimCurrt "直流充电模式最大限制电流(EVR)";
CM_ SG_ 794 OBC_DCCurrt "OBC直流侧电流";
CM_ SG_ 794 OBC_DchaEndNum "OBC放电结束码";
CM_ SG_ 794 OBC_DCVolt "OBC直流侧电压";
CM_ SG_ 794 OBC_DischrgOptMaxPwr "OBC放电输出最大功率";
CM_ SG_ 1460 CDU_HwVersion "CDU硬件版本";
CM_ SG_ 1460 CDU_SupplierCode "CDU供应商代码";
CM_ SG_ 1460 CDU_SwMajorVersion "CDU软件主版本号";
CM_ SG_ 1460 CDU_SwMinorVersion "CDU软件子版本号";
CM_ SG_ 1460 CDU_SwPatchVersion "CDU软件补充版本号";
CM_ SG_ 1460 CDU_SwVersionDay "CDU软件版本日";
CM_ SG_ 1460 CDU_SwVersionMonth "CDU软件版本月";
CM_ SG_ 1460 CDU_SwVersionYear "CDU软件版本年-2000";
CM_ SG_ 1460 DCDC_SwMajorVersion "DCDC软件主版本号";
CM_ SG_ 1460 DCDC_SwMinorVersion "DCDC软件子版本号";
CM_ SG_ 1460 DCDC_SwPatchVersion "DCDC软件补充版本号";
CM_ SG_ 1460 DCDC_SwVersionDay "DCDC软件版本日";
CM_ SG_ 1460 DCDC_SwVersionMonth "DCDC软件版本月";
CM_ SG_ 1460 DCDC_SwVersionYear "DCDC软件版本年-2000";
CM_ SG_ 1460 OBC_SwMajorVersion "OBC软件主版本号";
CM_ SG_ 1460 OBC_SwMinorVersion "OBC软件子版本号";
CM_ SG_ 1460 OBC_SwPatchVersion "OBC软件补充版本号";
CM_ SG_ 1460 OBC_SwVersionDay "OBC软件版本日";
CM_ SG_ 1460 OBC_SwVersionMonth "OBC软件版本月";
CM_ SG_ 1460 OBC_SwVersionYear "OBC软件版本年-2000";
CM_ SG_ 872 EMS_ClpFebckMean "燃油短期修正";
CM_ SG_ 872 EMS_CorrFxMsThrot "主充修正系数";
CM_ SG_ 872 EMS_CorrFxPrsToLd "次充修正系数";
CM_ SG_ 872 EMS_DwnCatTrm "后氧闭环修正";
CM_ SG_ 872 EMS_EGRActPostion "EGR实际开度";
CM_ SG_ 872 EMS_EnKnkSts "发动机爆震";
CM_ SG_ 872 EMS_Lambda "前氧Lam";
CM_ SG_ 872 EMS_MulAdp "燃油长期自学习";
CM_ SG_ 872 EMS_SupKnkPuls "早燃脉冲";
CM_ SG_ 1421 EMS_FaultNum1 "故障编号1";
CM_ SG_ 1421 EMS_FaultNum10 "故障编号10";
CM_ SG_ 1421 EMS_FaultNum11 "故障编号11";
CM_ SG_ 1421 EMS_FaultNum12 "故障编号12";
CM_ SG_ 1421 EMS_FaultNum13 "故障编号13";
CM_ SG_ 1421 EMS_FaultNum14 "故障编号14";
CM_ SG_ 1421 EMS_FaultNum15 "故障编号15";
CM_ SG_ 1421 EMS_FaultNum16 "故障编号16";
CM_ SG_ 1421 EMS_FaultNum17 "故障编号17";
CM_ SG_ 1421 EMS_FaultNum18 "故障编号18";
CM_ SG_ 1421 EMS_FaultNum19 "故障编号19";
CM_ SG_ 1421 EMS_FaultNum2 "故障编号2";
CM_ SG_ 1421 EMS_FaultNum20 "故障编号20";
CM_ SG_ 1421 EMS_FaultNum3 "故障编号3";
CM_ SG_ 1421 EMS_FaultNum4 "故障编号4";
CM_ SG_ 1421 EMS_FaultNum5 "故障编号5";
CM_ SG_ 1421 EMS_FaultNum6 "故障编号6";
CM_ SG_ 1421 EMS_FaultNum7 "故障编号7";
CM_ SG_ 1421 EMS_FaultNum8 "故障编号8";
CM_ SG_ 1421 EMS_FaultNum9 "故障编号9";
CM_ SG_ 1421 EMS_FrameIndex "帧序号";
CM_ SG_ 1421 EMS_SupplierNum "供应商代码";
CM_ SG_ 1421 EMS_TotalFaultNum "当前故障总数";
CM_ SG_ 291 EMS_ActIgnAng "实际点火角";
CM_ SG_ 291 EMS_BasIgnAng "基础点火角";
CM_ SG_ 291 EMS_CalculatedLoadRat "发动机计算负荷比";
CM_ SG_ 291 EMS_CatHeatingReq "催化剂加热请求";
CM_ SG_ 291 EMS_DewPointEndSt "露点结束状态";
CM_ SG_ 291 EMS_DrvgCyc "驾驶循环";
CM_ SG_ 291 EMS_EngIdleCtrlSts "发动机怠速控制状态";
CM_ SG_ 291 EMS_EngKonckSt "发动机爆震状态";
CM_ SG_ 291 EMS_EngStartInhb "发动机禁止起机标志位";
CM_ SG_ 291 EMS_EngStartReq "发动机启动请求";
CM_ SG_ 291 EMS_EngStartSuccess "发动机启动成功标志位";
CM_ SG_ 291 EMS_EngStopInhb "发动机禁止停机标志位";
CM_ SG_ 291 EMS_ExhaustPhaseValue "发动机排气相位";
CM_ SG_ 291 EMS_ExhGasTMnfld "排气温度";
CM_ SG_ 291 EMS_FuelCmspMassFlow "燃油瞬时消耗量";
CM_ SG_ 291 EMS_IgnAngIntvSt "点火角干预状态";
CM_ SG_ 291 EMS_IgnCyc "点火循环";
CM_ SG_ 291 EMS_IntakePhaseValue "发动机进气相位";
CM_ SG_ 291 EMS_LimpHomeSt "发动机跛行回家状态";
CM_ SG_ 291 EMS_OilPWarnLamp "机油压力低报警";
CM_ SG_ 291 EMS_OilPWarnSt "机油压力告警状态";
CM_ SG_ 291 EMS_OperSt "发动机运行状态";
CM_ SG_ 291 EMS_Pvd "发动机增压压力pressure upstream throttle valve(pvd)";
CM_ SG_ 291 EMS_PvdVld "发动机增压压力有效位";
CM_ SG_ 291 EMS_RelAirChrg "相对空气负荷Relative air charge (rl)";
CM_ SG_ 291 EMS_State_1_Checksum "CRC16 checksum  (DataID: 0x8123)";
CM_ SG_ 291 EMS_State_1_Counter "Rolling Counter";
CM_ SG_ 291 EMS_StPrioWpDmd "工况协调优先级";
CM_ SG_ 291 EMS_ThrAbsPosn "绝对节气门开度_OBD";
CM_ SG_ 291 EMS_ThrRelPosn "相对节气门开度_OBD";
CM_ SG_ 291 EMS_TqCtrlInhbSt "发动机禁止扭矩控制状态";
CM_ SG_ 291 EMS_WarmupCyc "暖机循环";
CM_ SG_ 291 EMS_WorkpointReq "EMS工况协调需求";
CM_ SG_ 386 EMS_AfterRunReq "发动机后运行请求";
CM_ SG_ 386 EMS_AmbAirP "大气压力";
CM_ SG_ 386 EMS_AmbAirPVld "大气压力有效位";
CM_ SG_ 386 EMS_CACPumpReq "发动机中冷器需求水泵转速";
CM_ SG_ 386 EMS_CatTemp "催化器估计温度";
CM_ SG_ 386 EMS_CatTempVld "催化器估计温度有效位";
CM_ SG_ 386 EMS_CoolantFanReq "cool request风扇请求";
CM_ SG_ 386 EMS_EngCoolantTemp "发动机冷却水温";
CM_ SG_ 386 EMS_EngCoolantTempVld "发动机冷却水温有效位";
CM_ SG_ 386 EMS_EngFuelCutOffSt "发动机断油状态";
CM_ SG_ 386 EMS_EngFuleCutOffAlldSt "发动机断油允许标志位";
CM_ SG_ 386 EMS_EngIntkAirTemp "进气温度";
CM_ SG_ 386 EMS_EngOverSpdFlg "发动机超速标志位";
CM_ SG_ 386 EMS_EngSpdSnsrFltSt "发动机转速传感器故障状态";
CM_ SG_ 386 EMS_EngStopTi "发动机停机时间";
CM_ SG_ 386 EMS_EngThrPosn "发动机节气门位置";
CM_ SG_ 386 EMS_EngThrPosnFlt "发动机节气门位置故障状态";
CM_ SG_ 386 EMS_FitvFlt "燃油箱泄压阀故障状态";
CM_ SG_ 386 EMS_FitvSt "燃油箱泄压阀打开状态";
CM_ SG_ 386 EMS_FltLvl "EMS故障等级";
CM_ SG_ 386 EMS_FuelAddingAlldSt "加油允许状态";
CM_ SG_ 386 EMS_FuelCutOffDiagSt "断油诊断状态";
CM_ SG_ 386 EMS_FuelInjected "累计喷油量";
CM_ SG_ 386 EMS_FuelInjectedVld "累计喷油量有效位";
CM_ SG_ 386 EMS_FuelTankP "燃油箱压力";
CM_ SG_ 386 EMS_FuelTankPRlsSt "高压油箱泄压状态";
CM_ SG_ 386 EMS_IntkMnfldP "进气歧管压力";
CM_ SG_ 386 EMS_IntkMnfldPVld "进气歧管压力有效位";
CM_ SG_ 386 EMS_LvBattVolt "EMS供电电压";
CM_ SG_ 386 EMS_MilIndicator "MIL灯点亮请求";
CM_ SG_ 386 EMS_RadiatorOutWaterTemp "散热器出口温度";
CM_ SG_ 386 EMS_RadiatorOutWaterTempVld "散热器出口温度有效位";
CM_ SG_ 386 EMS_State_2_Checksum "CRC16 checksum  (DataID: 0x8182)";
CM_ SG_ 386 EMS_State_2_Counter "Rolling Counter";
CM_ SG_ 386 EMS_ThrFwdEngIntkAirTemp "节气门前进气温度";
CM_ SG_ 386 EMS_ThrFwdEngIntkAirTempVld "节气门前进气温度有效位";
CM_ SG_ 386 EMS_TWVE_ActPerc "三通水阀TWVE实际开度";
CM_ SG_ 386 EMS_TWVE_TrgtPerc "三通水阀TWVE目标开度";
CM_ SG_ 386 EMS_WarmupAch "EMS暖机完成标志位";
CM_ SG_ 386 EMS_WaterPumpRotSpd "EMS水泵转速";
CM_ SG_ 386 EMS_WaterPumpSt "EMS水泵状态";
CM_ SG_ 290 EMS_EngActSpd "发动机实际转速";
CM_ SG_ 290 EMS_EngActSpdVld "发动机实际转速有效位";
CM_ SG_ 290 EMS_EngCrankPosn "发动机曲轴位置";
CM_ SG_ 290 EMS_EngFricTq "发动机摩擦扭矩";
CM_ SG_ 290 EMS_EngFricTqVld "发动机摩擦扭矩有效位";
CM_ SG_ 290 EMS_EngineSpdLim "发动机转速限制值";
CM_ SG_ 290 EMS_FlyWhlActTq "发动机飞轮端实际扭矩";
CM_ SG_ 290 EMS_FlyWhlActTqVld "发动机飞轮端实际扭矩有效位";
CM_ SG_ 290 EMS_FlyWhlTqCrsLeadMax "发动机当前转速最大充气量,最优点火效率对应的曲轴端扭矩减去储备扭矩";
CM_ SG_ 290 EMS_FlyWhlTqCrsLeadMaxVld "发动机当前转速最大充气量,最优点火效率对应的曲轴端扭矩减去储备扭矩 有效位";
CM_ SG_ 290 EMS_FlyWhlTqCrsLeadMin "发动机当前转速最小充气量,最优点火效率对应的曲轴端扭矩";
CM_ SG_ 290 EMS_FlyWhlTqCrsLeadMinVld "发动机当前转速最小充气量,最优点火效率对应的曲轴端扭矩 有效位";
CM_ SG_ 290 EMS_FlyWhlTqCrsSetMax "发动机当前转速当前充气量,最优点火效率对应的曲轴端扭矩减去储备扭矩";
CM_ SG_ 290 EMS_FlyWhlTqCrsSetMaxVld "发动机当前转速当前充气量,最优点火效率对应的曲轴端扭矩减去储备扭矩 有效位";
CM_ SG_ 290 EMS_FlyWhlTqCrsSetMin "发动机当前转速当前充气量,最小点火效率对应的曲轴端扭矩";
CM_ SG_ 290 EMS_FlyWhlTqCrsSetMinVld "发动机当前转速当前充气量,最小点火效率对应的曲轴端扭矩 有效位";
CM_ SG_ 290 EMS_FlyWhlTqMinWoCutoff "发动机飞轮端最小扭矩(不断油)";
CM_ SG_ 290 EMS_FlyWhlTqMinWoCutoffVld "发动机飞轮端最小扭矩有效位";
CM_ SG_ 290 EMS_IdleSpdBaseRef "发动机怠速参考转速";
CM_ SG_ 290 EMS_IdleSpdCurr "发动机怠速仲裁转速";
CM_ SG_ 290 EMS_IdleSpdRefVld "发动机怠速有效位";
CM_ SG_ 290 EMS_MaxSpdWorkpointReq "工况协调最大转速需求";
CM_ SG_ 290 EMS_MaxTqWorkpointReq "工况协调最大扭矩需求";
CM_ SG_ 290 EMS_MinSpdWorkpointReq "工况协调最小转速需求";
CM_ SG_ 290 EMS_MinTqWorkpointReq "工况协调发动机最小扭矩需求";
CM_ SG_ 290 EMS_SpdSyncSt "发动机转速同步状态";
CM_ SG_ 290 EMS_Tq_Spd_Checksum "CRC16 checksum  (DataID: 0x8122)";
CM_ SG_ 290 EMS_Tq_Spd_Counter "Rolling Counter";
CM_ SG_ 1553 EMS_HwVersion "硬件版本号";
CM_ SG_ 1553 EMS_SupplierCode "供应商代码";
CM_ SG_ 1553 EMS_SwMajorVersion "软件主版本号";
CM_ SG_ 1553 EMS_SwMinorVersion "软件子版本号";
CM_ SG_ 1553 EMS_SwPatchVersion "软件补充版本号";
CM_ SG_ 1553 EMS_SwVersionDay "软件版本日";
CM_ SG_ 1553 EMS_SwVersionMonth "软件版本月";
CM_ SG_ 1553 EMS_SwVersionYear "软件版本年-2000";
CM_ SG_ 909 ESSPTC_HVIL_Sta "ESSPTC高压互锁状态";
CM_ SG_ 909 ESSPTCActuCrnt "ESSPTC实际电流";
CM_ SG_ 909 ESSPTCActuPWMDuty "ESSPTC实际PWM占空比";
CM_ SG_ 909 ESSPTCActuPwr "ESSPTC实际功率";
CM_ SG_ 909 ESSPTCActuVol "ESSPTC实际电压";
CM_ SG_ 909 ESSPTCFltLvl "ESSPTC故障等级";
CM_ SG_ 909 ESSPTCIGBTOverHeat "ESSPTC_IGBT过温";
CM_ SG_ 909 ESSPTCIGBTSts "ESSTC_IGBT状态";
CM_ SG_ 909 ESSPTCIGBTTem "ESSTC_IGBT温度";
CM_ SG_ 909 ESSPTCInptTem "ESSPTC入口温度";
CM_ SG_ 909 ESSPTCNTCSts "ESSPTC故障状态";
CM_ SG_ 909 ESSPTCOtptTem "ESSPTC出口温度";
CM_ SG_ 909 ESSPTCOverCrnt "ESSPTC过流";
CM_ SG_ 909 ESSPTCOverHeat "ESSPTC过温";
CM_ SG_ 909 ESSPTCOverVol "ESSPTC过压";
CM_ SG_ 909 ESSPTCPCBTem "ESSPTC_PCB温度";
CM_ SG_ 909 ESSPTCRlngCtr "PTC Rolling Counter 1";
CM_ SG_ 909 ESSPTCSecRlngCtr "PTC Rolling Counter 2";
CM_ SG_ 909 ESSPTCSts "ESSPTC状态";
CM_ SG_ 909 ESSPTCUnderVol "ESSPTC欠压";
CM_ SG_ 1423 GCU_FaultNum1 "故障编号1";
CM_ SG_ 1423 GCU_FaultNum10 "故障编号10";
CM_ SG_ 1423 GCU_FaultNum11 "故障编号11";
CM_ SG_ 1423 GCU_FaultNum12 "故障编号12";
CM_ SG_ 1423 GCU_FaultNum13 "故障编号13";
CM_ SG_ 1423 GCU_FaultNum14 "故障编号14";
CM_ SG_ 1423 GCU_FaultNum15 "故障编号15";
CM_ SG_ 1423 GCU_FaultNum16 "故障编号16";
CM_ SG_ 1423 GCU_FaultNum17 "故障编号17";
CM_ SG_ 1423 GCU_FaultNum18 "故障编号18";
CM_ SG_ 1423 GCU_FaultNum19 "故障编号19";
CM_ SG_ 1423 GCU_FaultNum2 "故障编号2";
CM_ SG_ 1423 GCU_FaultNum20 "故障编号20";
CM_ SG_ 1423 GCU_FaultNum3 "故障编号3";
CM_ SG_ 1423 GCU_FaultNum4 "故障编号4";
CM_ SG_ 1423 GCU_FaultNum5 "故障编号5";
CM_ SG_ 1423 GCU_FaultNum6 "故障编号6";
CM_ SG_ 1423 GCU_FaultNum7 "故障编号7";
CM_ SG_ 1423 GCU_FaultNum8 "故障编号8";
CM_ SG_ 1423 GCU_FaultNum9 "故障编号9";
CM_ SG_ 1423 GCU_FrameIndex "帧序号";
CM_ SG_ 1423 GCU_SupplierNum "供应商代码";
CM_ SG_ 1423 GCU_TotalFaultNum "当前故障总数";
CM_ SG_ 294 GCU_ActEff "当前效率(发电机系统)";
CM_ SG_ 294 GCU_ActMaxVolt "GCU电压最大值";
CM_ SG_ 294 GCU_ActMinVolt "GCU电压最小值";
CM_ SG_ 294 GCU_CurrtPhaA "A相电流";
CM_ SG_ 294 GCU_CurrtPhaB "B相电流";
CM_ SG_ 294 GCU_CurrtPhaC "C相电流";
CM_ SG_ 294 GCU_DCCurrt "电机直流母线电流";
CM_ SG_ 294 GCU_DchaSt "GCU高压主动放电状态";
CM_ SG_ 294 GCU_DCVolt "电机直流母线电压";
CM_ SG_ 294 GCU_FltLvl "故障等级";
CM_ SG_ 294 GCU_HVIL_St "GCU高压互锁状态";
CM_ SG_ 294 GCU_IGBTMod "GCU IGBT状态";
CM_ SG_ 294 GCU_MILReq "发电机点MIL灯请求";
CM_ SG_ 294 GCU_MotWorkSt "发电机工作状态";
CM_ SG_ 294 GCU_OBDFaultExistSts "当前驾驶循环GCU监测OBD实时故障标志位";
CM_ SG_ 294 GCU_OperMod "发电机控制器当前工作模式";
CM_ SG_ 294 GCU_ResolverFltTyp "旋变故障类型";
CM_ SG_ 294 GCU_State_1_Checksum "CRC16 checksum (DataID: 0x8126)";
CM_ SG_ 294 GCU_State_1_Counter "Rolling Counter";
CM_ SG_ 799 GCU_FlowReq "GCU冷却液流量请求";
CM_ SG_ 799 GCU_IGBTTempA "IGBT温度A";
CM_ SG_ 799 GCU_IGBTTempA_Chip "IGBT估算结温A";
CM_ SG_ 799 GCU_IGBTTempB "IGBT温度B";
CM_ SG_ 799 GCU_IGBTTempB_Chip "IGBT估算结温B";
CM_ SG_ 799 GCU_IGBTTempC "IGBT温度C";
CM_ SG_ 799 GCU_IGBTTempC_Chip "IGBT估算结温C";
CM_ SG_ 799 GCU_KL15OnSt "KL15唤醒状态";
CM_ SG_ 799 GCU_KL15Volt "KL15电压";
CM_ SG_ 799 GCU_KL30Volt "KL30电压";
CM_ SG_ 799 GCU_PCBTemp "控制器单板温度";
CM_ SG_ 799 GCU_RotorTemp "发电机转子温度";
CM_ SG_ 799 GCU_State_2_Checksum "CRC16 checksum (DataID: 0x831F)";
CM_ SG_ 799 GCU_State_2_Counter "Rolling Counter";
CM_ SG_ 799 GCU_TempWinding "发电机绕组温度";
CM_ SG_ 855 GCU_EOP_Actual_Speed "油泵反馈的实际转速占空步进值
F=(N/255)*100";
CM_ SG_ 855 GCU_EOP_AIRmix_Fault "空吸(干转)故障";
CM_ SG_ 855 GCU_EOP_Current "油泵反馈的实际电流";
CM_ SG_ 855 GCU_EOP_MOS_Temp "油泵反馈的实际MOS温度";
CM_ SG_ 855 GCU_EOP_Over_Current_Fault "过流故障";
CM_ SG_ 855 GCU_EOP_Over_Temp_Fault "过温停机故障";
CM_ SG_ 855 GCU_EOP_Over_Voltage_Fault "过压故障";
CM_ SG_ 855 GCU_EOP_Self_Check_Fault "自检故障";
CM_ SG_ 855 GCU_EOP_State "油泵反馈的运行状态";
CM_ SG_ 855 GCU_EOP_Stuck_Fault "堵转故障";
CM_ SG_ 855 GCU_EOP_Target_Speed "油泵目标转速占空步进值
F=(N/255)*100";
CM_ SG_ 855 GCU_EOP_Under_Voltage_Fault "欠压故障";
CM_ SG_ 855 GCU_EOP_Voltage "油泵反馈的实际电压";
CM_ SG_ 855 GCU_HVCalSt "GCU母线电压校准状态";
CM_ SG_ 293 GCU_ActRotSpd "发电机当前转速";
CM_ SG_ 293 GCU_ActTq "发电机当前扭矩";
CM_ SG_ 293 GCU_ActUnfilteredRotSpd "发电机当前未虑波转速";
CM_ SG_ 293 GCU_CompensationTq "发电机主动阻尼补偿扭矩值";
CM_ SG_ 293 GCU_MaxOutputEleTq "电机最大允许电动转矩";
CM_ SG_ 293 GCU_MaxOutputGenTq "电机最大允许发电转矩";
CM_ SG_ 293 GCU_RotSpdMaxLimit "故障时电机最高限制转速";
CM_ SG_ 293 GCU_Tq_Spd_Checksum "CRC16 checksum (DataID: 0x8125)";
CM_ SG_ 293 GCU_Tq_Spd_Counter "Rolling Counter";
CM_ SG_ 1465 GCU_HwVersion "硬件版本号";
CM_ SG_ 1465 GCU_SupplierCode "供应商代码";
CM_ SG_ 1465 GCU_SwMajorVersion "软件主版本号";
CM_ SG_ 1465 GCU_SwMinorVersion "软件子版本号";
CM_ SG_ 1465 GCU_SwPatchVersion "软件补充版本号";
CM_ SG_ 1465 GCU_SwVersionDay "软件版本日";
CM_ SG_ 1465 GCU_SwVersionMonth "软件版本月";
CM_ SG_ 1465 GCU_SwVersionYear "软件版本年-2000";
CM_ SG_ 279 IPB_SumOfEdgeFLWSS "左前轮速脉冲计数";
CM_ SG_ 279 IPB_SumOfEdgeFLWSSValid "左前轮速脉冲计数有效位";
CM_ SG_ 279 IPB_SumOfEdgeFRWSS "右前轮速脉冲计数";
CM_ SG_ 279 IPB_SumOfEdgeFRWSSValid "右前轮速脉冲计数有效位";
CM_ SG_ 279 IPB_SumOfEdgeRLWSS "左后轮速脉冲计数";
CM_ SG_ 279 IPB_SumOfEdgeRLWSSValid "左后轮速脉冲计数有效位";
CM_ SG_ 279 IPB_SumOfEdgeRRWSS "右后轮速脉冲计数";
CM_ SG_ 279 IPB_SumOfEdgeRRWSSValid "右后轮速脉冲计数有效位";
CM_ SG_ 279 IPB_VehicleSpeed "车速";
CM_ SG_ 279 IPB_VehicleSpeedValid "车速有效位";
CM_ SG_ 279 IPB_Wheel_Checksum "CRC16 checksum (DataID: 0x6117)";
CM_ SG_ 279 IPB_Wheel_RollingCounter "Rolling Counter";
CM_ SG_ 279 IPB_WheelDirectionFL "左前轮滚动方向";
CM_ SG_ 279 IPB_WheelDirectionFLValid "左前轮滚动方向有效";
CM_ SG_ 279 IPB_WheelDirectionFR "右前轮滚动方向";
CM_ SG_ 279 IPB_WheelDirectionFRValid "右前轮滚动方向有效";
CM_ SG_ 279 IPB_WheelDirectionRL "左后轮滚动方向";
CM_ SG_ 279 IPB_WheelDirectionRLValid "左后轮滚动方向有效";
CM_ SG_ 279 IPB_WheelDirectionRR "右后轮滚动方向";
CM_ SG_ 279 IPB_WheelDirectionRRValid "右后轮滚动方向有效";
CM_ SG_ 279 IPB_WheelSpeedFL "wheel speed front left
左前轮速";
CM_ SG_ 279 IPB_WheelSpeedFLValid "wheel speed front left Valid
左前轮速有效位";
CM_ SG_ 279 IPB_WheelSpeedFR "wheel speed front right
右前轮速";
CM_ SG_ 279 IPB_WheelSpeedFRValid "wheel speed front right Valid
右前轮速有效位";
CM_ SG_ 279 IPB_WheelSpeedRL "wheel speed rear left
左后轮速";
CM_ SG_ 279 IPB_WheelSpeedRLValid "wheel speed rear left Valid
左后轮速有效位";
CM_ SG_ 279 IPB_WheelSpeedRR "wheel speed rear right
右后轮速";
CM_ SG_ 279 IPB_WheelSpeedRRValid "wheel speed rear right Valid
右后轮速有效位";
CM_ SG_ 873 MCUR_AppPrefailResn "App复位原因";
CM_ SG_ 873 MCUR_BSWInitSts "实际内部模式请求值";
CM_ SG_ 873 MCUR_CosAmp "旋变cos幅值";
CM_ SG_ 873 MCUR_MonLmpResn "监控层进入跛行原因";
CM_ SG_ 873 MCUR_OffChkEnAngErrAvr "offset精度均值";
CM_ SG_ 873 MCUR_OfstAng "电机初始角";
CM_ SG_ 873 MCUR_PHirAbnormalPercent "磁链估算均值偏差";
CM_ SG_ 873 MCUR_RstResn "reset原因";
CM_ SG_ 873 MCUR_SinAmp "旋变SIN幅值";
CM_ SG_ 873 MCUR_UdCmd "ud";
CM_ SG_ 873 MCUR_UqCmd "Uq";
CM_ SG_ 1305 MCUR_FaultNum1 "故障编号1";
CM_ SG_ 1305 MCUR_FaultNum10 "故障编号10";
CM_ SG_ 1305 MCUR_FaultNum11 "故障编号11";
CM_ SG_ 1305 MCUR_FaultNum12 "故障编号12";
CM_ SG_ 1305 MCUR_FaultNum13 "故障编号13";
CM_ SG_ 1305 MCUR_FaultNum14 "故障编号14";
CM_ SG_ 1305 MCUR_FaultNum15 "故障编号15";
CM_ SG_ 1305 MCUR_FaultNum16 "故障编号16";
CM_ SG_ 1305 MCUR_FaultNum17 "故障编号17";
CM_ SG_ 1305 MCUR_FaultNum18 "故障编号18";
CM_ SG_ 1305 MCUR_FaultNum19 "故障编号19";
CM_ SG_ 1305 MCUR_FaultNum2 "故障编号2";
CM_ SG_ 1305 MCUR_FaultNum20 "故障编号20";
CM_ SG_ 1305 MCUR_FaultNum3 "故障编号3";
CM_ SG_ 1305 MCUR_FaultNum4 "故障编号4";
CM_ SG_ 1305 MCUR_FaultNum5 "故障编号5";
CM_ SG_ 1305 MCUR_FaultNum6 "故障编号6";
CM_ SG_ 1305 MCUR_FaultNum7 "故障编号7";
CM_ SG_ 1305 MCUR_FaultNum8 "故障编号8";
CM_ SG_ 1305 MCUR_FaultNum9 "故障编号9";
CM_ SG_ 1305 MCUR_FrameIndex "帧序号";
CM_ SG_ 1305 MCUR_SupplierNum "供应商代码";
CM_ SG_ 1305 MCUR_TotalFaultNum "当前故障总数";
CM_ SG_ 262 MCUR_ActRotSpd "电机当前转速";
CM_ SG_ 262 MCUR_ActTq "后电机当前转矩";
CM_ SG_ 262 MCUR_ActUnfilteredRotSpd "无滤波的电机反馈转速";
CM_ SG_ 262 MCUR_BlkSt "MCU卡停状态";
CM_ SG_ 262 MCUR_CompensationTq "电机主动阻尼补偿扭矩值";
CM_ SG_ 262 MCUR_DCB_CapDchaSts "DCB电容主动放电状态";
CM_ SG_ 262 MCUR_DCBoostChrgMaxOutpPwr "快充电压转换模块最大允许输出功率";
CM_ SG_ 262 MCUR_DCBoostChrgOperSts "快充电压转换模块工作状态";
CM_ SG_ 262 MCUR_DischargeState "电机控制器高压主动放电状态";
CM_ SG_ 262 MCUR_FaultLevel "电机系统故障等级";
CM_ SG_ 262 MCUR_FlowReq "MCUR冷却液流量请求";
CM_ SG_ 262 MCUR_FlusSt "磁链状态(异步机)";
CM_ SG_ 262 MCUR_HVIL_DCB_St "MCU侧(接DCB)高压互锁状态";
CM_ SG_ 262 MCUR_IGBTmode "MCUR IGBT状态";
CM_ SG_ 262 MCUR_IGBTOverTempWarn "控制系统IGBT过温报警";
CM_ SG_ 262 MCUR_IGBTTempA "IGBT温度A";
CM_ SG_ 262 MCUR_IGBTTempB "IGBT温度B";
CM_ SG_ 262 MCUR_IGBTTempC "IGBT温度C";
CM_ SG_ 262 MCUR_MaxOutputDriveTq "最大允许输出驱动扭矩";
CM_ SG_ 262 MCUR_MaxOutputRegenTq "最大允许输出发电扭矩";
CM_ SG_ 262 MCUR_MotOverTempWarn "电机温度过温报警";
CM_ SG_ 262 MCUR_MotTemp "电机温度";
CM_ SG_ 262 MCUR_MotWorkState "电机工作状态";
CM_ SG_ 262 MCUR_OperMod "后电机控制器当前工作模式";
CM_ SG_ 262 MCUR_RotorTemp "电机转子温度";
CM_ SG_ 262 MCUR_RotSpdMaxLimit "故障时后电机最高限制转速";
CM_ SG_ 262 MCUR_SpdModAvl "MCU转速模式可用状态";
CM_ SG_ 262 MCUR_SpdSVModFlt "转速模式或SV模式故障原因";
CM_ SG_ 262 MCUR_Standstill "MCU standstill状态";
CM_ SG_ 262 MCUR_State_1_Checksum "CRC16 checksum  (DataID: 0x8106)";
CM_ SG_ 262 MCUR_State_1_Counter "Rolling Counter";
CM_ SG_ 262 MCUR_SVModAvl "MCU SV模式可用状态";
CM_ SG_ 262 MCUR_TarTq "电机目标转矩";
CM_ SG_ 262 MCUR_VehSldSt "车辆是否溜车";

// Attribute definitions
BA_DEF_ BO_ "CANFD_BRS" ENUM "1","0"; //
BA_DEF_ BO_ "DiagRequest" ENUM "Yes","No"; //
BA_DEF_ BO_ "DiagResponse" ENUM "Yes","No"; //
BA_DEF_ BO_ "DiagState" ENUM "Yes","No"; //
BA_DEF_ BO_ "GenMsgSendType" ENUM "Cycle","Event","CE"; //
BA_DEF_ SG_ "GenSigSendType" ENUM "Cycle","OnWrite","OnWriteWithRepetition","OnChange","OnChangeWithRepetition"; //
BA_DEF_ BO_ "MSG IL Support" ENUM "Yes","No"; //
BA_DEF_ BO_ "NmMessage" ENUM "Yes","No"; //
BA_DEF_ BO_ "VFrameFormat" ENUM "StandardCAN","ExtendedCAN","reserved","J1939PG","reserved","reserved","reserved","reserved","reserved","reserved","reserved","reserved","reserved","reserved","StandardCAN_FD","ExtendedCAN_FD";
BA_DEF_ BO_ "GenMsgCycleTime" FLOAT 0 300000; // [ms]
BA_DEF_ BO_ "GenMsgStartDelayTime" FLOAT 0 300000; // [ms]
BA_DEF_ BO_ "GenMsgDelayTime" FLOAT 0 300000; // [ms]
BA_DEF_ SG_ "GenSigStartValue" FLOAT -1.7976931348623157E308 18446744073709551615;
BA_DEF_ BO_ "GenMsgNrOfRepetition" INT 0 100000;
BA_DEF_ BO_ "GenMsgCycleTimeFast" FLOAT 0 300000;

BA_DEF_DEF_ "CANFD_BRS" "1";
BA_DEF_DEF_ "DiagRequest" "No";
BA_DEF_DEF_ "DiagResponse" "No";
BA_DEF_DEF_ "DiagState" "No";
BA_DEF_DEF_ "GenMsgSendType" "Cycle";
BA_DEF_DEF_ "GenSigSendType" "Cycle";
BA_DEF_DEF_ "MSG IL Support" "Yes";
BA_DEF_DEF_ "NmMessage" "No";
BA_DEF_DEF_ "VFrameFormat" "J1939PG";
BA_DEF_DEF_ "GenSigStartValue" 0;
BA_DEF_DEF_ "GenMsgNrOfRepetition" 0;
// Frame: BMS_TSerials
BA_ "VFrameFormat" BO_ 1414 14;
BA_ "GenMsgCycleTime" BO_ 1414 1000.000;
BA_ "GenMsgStartDelayTime" BO_ 1414 0.000;
BA_ "GenSigStartValue" SG_ 1414 BMS_SnsrT1 254;
BA_ "GenSigStartValue" SG_ 1414 BMS_SnsrT10 254;
BA_ "GenSigStartValue" SG_ 1414 BMS_SnsrT11 254;
BA_ "GenSigStartValue" SG_ 1414 BMS_SnsrT12 254;
BA_ "GenSigStartValue" SG_ 1414 BMS_SnsrT13 254;
BA_ "GenSigStartValue" SG_ 1414 BMS_SnsrT14 254;
BA_ "GenSigStartValue" SG_ 1414 BMS_SnsrT15 254;
BA_ "GenSigStartValue" SG_ 1414 BMS_SnsrT16 254;
BA_ "GenSigStartValue" SG_ 1414 BMS_SnsrT17 254;
BA_ "GenSigStartValue" SG_ 1414 BMS_SnsrT18 254;
BA_ "GenSigStartValue" SG_ 1414 BMS_SnsrT19 254;
BA_ "GenSigStartValue" SG_ 1414 BMS_SnsrT2 254;
BA_ "GenSigStartValue" SG_ 1414 BMS_SnsrT20 254;
BA_ "GenSigStartValue" SG_ 1414 BMS_SnsrT21 254;
BA_ "GenSigStartValue" SG_ 1414 BMS_SnsrT22 254;
BA_ "GenSigStartValue" SG_ 1414 BMS_SnsrT23 254;
BA_ "GenSigStartValue" SG_ 1414 BMS_SnsrT24 254;
BA_ "GenSigStartValue" SG_ 1414 BMS_SnsrT25 254;
BA_ "GenSigStartValue" SG_ 1414 BMS_SnsrT26 254;
BA_ "GenSigStartValue" SG_ 1414 BMS_SnsrT27 254;
BA_ "GenSigStartValue" SG_ 1414 BMS_SnsrT28 254;
BA_ "GenSigStartValue" SG_ 1414 BMS_SnsrT29 254;
BA_ "GenSigStartValue" SG_ 1414 BMS_SnsrT3 254;
BA_ "GenSigStartValue" SG_ 1414 BMS_SnsrT30 254;
BA_ "GenSigStartValue" SG_ 1414 BMS_SnsrT31 254;
BA_ "GenSigStartValue" SG_ 1414 BMS_SnsrT32 254;
BA_ "GenSigStartValue" SG_ 1414 BMS_SnsrT33 254;
BA_ "GenSigStartValue" SG_ 1414 BMS_SnsrT34 254;
BA_ "GenSigStartValue" SG_ 1414 BMS_SnsrT35 254;
BA_ "GenSigStartValue" SG_ 1414 BMS_SnsrT36 254;
BA_ "GenSigStartValue" SG_ 1414 BMS_SnsrT37 254;
BA_ "GenSigStartValue" SG_ 1414 BMS_SnsrT38 254;
BA_ "GenSigStartValue" SG_ 1414 BMS_SnsrT39 254;
BA_ "GenSigStartValue" SG_ 1414 BMS_SnsrT4 254;
BA_ "GenSigStartValue" SG_ 1414 BMS_SnsrT40 254;
BA_ "GenSigStartValue" SG_ 1414 BMS_SnsrT41 254;
BA_ "GenSigStartValue" SG_ 1414 BMS_SnsrT42 254;
BA_ "GenSigStartValue" SG_ 1414 BMS_SnsrT43 254;
BA_ "GenSigStartValue" SG_ 1414 BMS_SnsrT44 254;
BA_ "GenSigStartValue" SG_ 1414 BMS_SnsrT45 254;
BA_ "GenSigStartValue" SG_ 1414 BMS_SnsrT46 254;
BA_ "GenSigStartValue" SG_ 1414 BMS_SnsrT47 254;
BA_ "GenSigStartValue" SG_ 1414 BMS_SnsrT48 254;
BA_ "GenSigStartValue" SG_ 1414 BMS_SnsrT49 254;
BA_ "GenSigStartValue" SG_ 1414 BMS_SnsrT5 254;
BA_ "GenSigStartValue" SG_ 1414 BMS_SnsrT50 254;
BA_ "GenSigStartValue" SG_ 1414 BMS_SnsrT51 254;
BA_ "GenSigStartValue" SG_ 1414 BMS_SnsrT52 254;
BA_ "GenSigStartValue" SG_ 1414 BMS_SnsrT53 254;
BA_ "GenSigStartValue" SG_ 1414 BMS_SnsrT54 254;
BA_ "GenSigStartValue" SG_ 1414 BMS_SnsrT55 254;
BA_ "GenSigStartValue" SG_ 1414 BMS_SnsrT56 254;
BA_ "GenSigStartValue" SG_ 1414 BMS_SnsrT57 254;
BA_ "GenSigStartValue" SG_ 1414 BMS_SnsrT58 254;
BA_ "GenSigStartValue" SG_ 1414 BMS_SnsrT59 254;
BA_ "GenSigStartValue" SG_ 1414 BMS_SnsrT6 254;
BA_ "GenSigStartValue" SG_ 1414 BMS_SnsrT60 254;
BA_ "GenSigStartValue" SG_ 1414 BMS_SnsrT61 254;
BA_ "GenSigStartValue" SG_ 1414 BMS_SnsrT62 254;
BA_ "GenSigStartValue" SG_ 1414 BMS_SnsrT63 254;
BA_ "GenSigStartValue" SG_ 1414 BMS_SnsrT7 254;
BA_ "GenSigStartValue" SG_ 1414 BMS_SnsrT8 254;
BA_ "GenSigStartValue" SG_ 1414 BMS_SnsrT9 254;
// Frame: BMS_Version
BA_ "VFrameFormat" BO_ 1457 14;
BA_ "GenMsgCycleTime" BO_ 1457 10000.000;
BA_ "GenMsgStartDelayTime" BO_ 1457 0.000;
// Frame: BMS_VoltSerials1
BA_ "VFrameFormat" BO_ 1409 14;
BA_ "GenMsgCycleTime" BO_ 1409 1000.000;
BA_ "GenMsgStartDelayTime" BO_ 1409 0.000;
BA_ "GenSigStartValue" SG_ 1409 BMS_CellU1 8190;
BA_ "GenSigStartValue" SG_ 1409 BMS_CellU10 8190;
BA_ "GenSigStartValue" SG_ 1409 BMS_CellU11 8190;
BA_ "GenSigStartValue" SG_ 1409 BMS_CellU12 8190;
BA_ "GenSigStartValue" SG_ 1409 BMS_CellU13 8190;
BA_ "GenSigStartValue" SG_ 1409 BMS_CellU14 8190;
BA_ "GenSigStartValue" SG_ 1409 BMS_CellU15 8190;
BA_ "GenSigStartValue" SG_ 1409 BMS_CellU16 8190;
BA_ "GenSigStartValue" SG_ 1409 BMS_CellU17 8190;
BA_ "GenSigStartValue" SG_ 1409 BMS_CellU18 8190;
BA_ "GenSigStartValue" SG_ 1409 BMS_CellU19 8190;
BA_ "GenSigStartValue" SG_ 1409 BMS_CellU2 8190;
BA_ "GenSigStartValue" SG_ 1409 BMS_CellU20 8190;
BA_ "GenSigStartValue" SG_ 1409 BMS_CellU21 8190;
BA_ "GenSigStartValue" SG_ 1409 BMS_CellU22 8190;
BA_ "GenSigStartValue" SG_ 1409 BMS_CellU23 8190;
BA_ "GenSigStartValue" SG_ 1409 BMS_CellU24 8190;
BA_ "GenSigStartValue" SG_ 1409 BMS_CellU25 8190;
BA_ "GenSigStartValue" SG_ 1409 BMS_CellU26 8190;
BA_ "GenSigStartValue" SG_ 1409 BMS_CellU27 8190;
BA_ "GenSigStartValue" SG_ 1409 BMS_CellU28 8190;
BA_ "GenSigStartValue" SG_ 1409 BMS_CellU29 8190;
BA_ "GenSigStartValue" SG_ 1409 BMS_CellU3 8190;
BA_ "GenSigStartValue" SG_ 1409 BMS_CellU30 8190;
BA_ "GenSigStartValue" SG_ 1409 BMS_CellU31 8190;
BA_ "GenSigStartValue" SG_ 1409 BMS_CellU32 8190;
BA_ "GenSigStartValue" SG_ 1409 BMS_CellU33 8190;
BA_ "GenSigStartValue" SG_ 1409 BMS_CellU34 8190;
BA_ "GenSigStartValue" SG_ 1409 BMS_CellU35 8190;
BA_ "GenSigStartValue" SG_ 1409 BMS_CellU36 8190;
BA_ "GenSigStartValue" SG_ 1409 BMS_CellU37 8190;
BA_ "GenSigStartValue" SG_ 1409 BMS_CellU38 8190;
BA_ "GenSigStartValue" SG_ 1409 BMS_CellU39 8190;
BA_ "GenSigStartValue" SG_ 1409 BMS_CellU4 8190;
BA_ "GenSigStartValue" SG_ 1409 BMS_CellU5 8190;
BA_ "GenSigStartValue" SG_ 1409 BMS_CellU6 8190;
BA_ "GenSigStartValue" SG_ 1409 BMS_CellU7 8190;
BA_ "GenSigStartValue" SG_ 1409 BMS_CellU8 8190;
BA_ "GenSigStartValue" SG_ 1409 BMS_CellU9 8190;
// Frame: BMS_VoltSerials2
BA_ "VFrameFormat" BO_ 1410 14;
BA_ "GenMsgCycleTime" BO_ 1410 1000.000;
BA_ "GenMsgStartDelayTime" BO_ 1410 0.000;
BA_ "GenSigStartValue" SG_ 1410 BMS_CellU40 8190;
BA_ "GenSigStartValue" SG_ 1410 BMS_CellU41 8190;
BA_ "GenSigStartValue" SG_ 1410 BMS_CellU42 8190;
BA_ "GenSigStartValue" SG_ 1410 BMS_CellU43 8190;
BA_ "GenSigStartValue" SG_ 1410 BMS_CellU44 8190;
BA_ "GenSigStartValue" SG_ 1410 BMS_CellU45 8190;
BA_ "GenSigStartValue" SG_ 1410 BMS_CellU46 8190;
BA_ "GenSigStartValue" SG_ 1410 BMS_CellU47 8190;
BA_ "GenSigStartValue" SG_ 1410 BMS_CellU48 8190;
BA_ "GenSigStartValue" SG_ 1410 BMS_CellU49 8190;
BA_ "GenSigStartValue" SG_ 1410 BMS_CellU50 8190;
BA_ "GenSigStartValue" SG_ 1410 BMS_CellU51 8190;
BA_ "GenSigStartValue" SG_ 1410 BMS_CellU52 8190;
BA_ "GenSigStartValue" SG_ 1410 BMS_CellU53 8190;
BA_ "GenSigStartValue" SG_ 1410 BMS_CellU54 8190;
BA_ "GenSigStartValue" SG_ 1410 BMS_CellU55 8190;
BA_ "GenSigStartValue" SG_ 1410 BMS_CellU56 8190;
BA_ "GenSigStartValue" SG_ 1410 BMS_CellU57 8190;
BA_ "GenSigStartValue" SG_ 1410 BMS_CellU58 8190;
BA_ "GenSigStartValue" SG_ 1410 BMS_CellU59 8190;
BA_ "GenSigStartValue" SG_ 1410 BMS_CellU60 8190;
BA_ "GenSigStartValue" SG_ 1410 BMS_CellU61 8190;
BA_ "GenSigStartValue" SG_ 1410 BMS_CellU62 8190;
BA_ "GenSigStartValue" SG_ 1410 BMS_CellU63 8190;
BA_ "GenSigStartValue" SG_ 1410 BMS_CellU64 8190;
BA_ "GenSigStartValue" SG_ 1410 BMS_CellU65 8190;
BA_ "GenSigStartValue" SG_ 1410 BMS_CellU66 8190;
BA_ "GenSigStartValue" SG_ 1410 BMS_CellU67 8190;
BA_ "GenSigStartValue" SG_ 1410 BMS_CellU68 8190;
BA_ "GenSigStartValue" SG_ 1410 BMS_CellU69 8190;
BA_ "GenSigStartValue" SG_ 1410 BMS_CellU70 8190;
BA_ "GenSigStartValue" SG_ 1410 BMS_CellU71 8190;
BA_ "GenSigStartValue" SG_ 1410 BMS_CellU72 8190;
BA_ "GenSigStartValue" SG_ 1410 BMS_CellU73 8190;
BA_ "GenSigStartValue" SG_ 1410 BMS_CellU74 8190;
BA_ "GenSigStartValue" SG_ 1410 BMS_CellU75 8190;
BA_ "GenSigStartValue" SG_ 1410 BMS_CellU76 8190;
BA_ "GenSigStartValue" SG_ 1410 BMS_CellU77 8190;
BA_ "GenSigStartValue" SG_ 1410 BMS_CellU78 8190;
// Frame: BMS_VoltSerials3
BA_ "VFrameFormat" BO_ 1411 14;
BA_ "GenMsgCycleTime" BO_ 1411 1000.000;
BA_ "GenMsgStartDelayTime" BO_ 1411 0.000;
BA_ "GenSigStartValue" SG_ 1411 BMS_CellU100 8190;
BA_ "GenSigStartValue" SG_ 1411 BMS_CellU101 8190;
BA_ "GenSigStartValue" SG_ 1411 BMS_CellU102 8190;
BA_ "GenSigStartValue" SG_ 1411 BMS_CellU103 8190;
BA_ "GenSigStartValue" SG_ 1411 BMS_CellU104 8190;
BA_ "GenSigStartValue" SG_ 1411 BMS_CellU105 8190;
BA_ "GenSigStartValue" SG_ 1411 BMS_CellU106 8190;
BA_ "GenSigStartValue" SG_ 1411 BMS_CellU107 8190;
BA_ "GenSigStartValue" SG_ 1411 BMS_CellU108 8190;
BA_ "GenSigStartValue" SG_ 1411 BMS_CellU109 8190;
BA_ "GenSigStartValue" SG_ 1411 BMS_CellU110 8190;
BA_ "GenSigStartValue" SG_ 1411 BMS_CellU111 8190;
BA_ "GenSigStartValue" SG_ 1411 BMS_CellU112 8190;
BA_ "GenSigStartValue" SG_ 1411 BMS_CellU113 8190;
BA_ "GenSigStartValue" SG_ 1411 BMS_CellU114 8190;
BA_ "GenSigStartValue" SG_ 1411 BMS_CellU115 8190;
BA_ "GenSigStartValue" SG_ 1411 BMS_CellU116 8190;
BA_ "GenSigStartValue" SG_ 1411 BMS_CellU117 8190;
BA_ "GenSigStartValue" SG_ 1411 BMS_CellU79 8190;
BA_ "GenSigStartValue" SG_ 1411 BMS_CellU80 8190;
BA_ "GenSigStartValue" SG_ 1411 BMS_CellU81 8190;
BA_ "GenSigStartValue" SG_ 1411 BMS_CellU82 8190;
BA_ "GenSigStartValue" SG_ 1411 BMS_CellU83 8190;
BA_ "GenSigStartValue" SG_ 1411 BMS_CellU84 8190;
BA_ "GenSigStartValue" SG_ 1411 BMS_CellU85 8190;
BA_ "GenSigStartValue" SG_ 1411 BMS_CellU86 8190;
BA_ "GenSigStartValue" SG_ 1411 BMS_CellU87 8190;
BA_ "GenSigStartValue" SG_ 1411 BMS_CellU88 8190;
BA_ "GenSigStartValue" SG_ 1411 BMS_CellU89 8190;
BA_ "GenSigStartValue" SG_ 1411 BMS_CellU90 8190;
BA_ "GenSigStartValue" SG_ 1411 BMS_CellU91 8190;
BA_ "GenSigStartValue" SG_ 1411 BMS_CellU92 8190;
BA_ "GenSigStartValue" SG_ 1411 BMS_CellU93 8190;
BA_ "GenSigStartValue" SG_ 1411 BMS_CellU94 8190;
BA_ "GenSigStartValue" SG_ 1411 BMS_CellU95 8190;
BA_ "GenSigStartValue" SG_ 1411 BMS_CellU96 8190;
BA_ "GenSigStartValue" SG_ 1411 BMS_CellU97 8190;
BA_ "GenSigStartValue" SG_ 1411 BMS_CellU98 8190;
BA_ "GenSigStartValue" SG_ 1411 BMS_CellU99 8190;
// Frame: BMS_VoltSerials4
BA_ "VFrameFormat" BO_ 1412 14;
BA_ "GenMsgCycleTime" BO_ 1412 1000.000;
BA_ "GenMsgStartDelayTime" BO_ 1412 0.000;
BA_ "GenSigStartValue" SG_ 1412 BMS_CellU118 8190;
BA_ "GenSigStartValue" SG_ 1412 BMS_CellU119 8190;
BA_ "GenSigStartValue" SG_ 1412 BMS_CellU120 8190;
BA_ "GenSigStartValue" SG_ 1412 BMS_CellU121 8190;
BA_ "GenSigStartValue" SG_ 1412 BMS_CellU122 8190;
BA_ "GenSigStartValue" SG_ 1412 BMS_CellU123 8190;
BA_ "GenSigStartValue" SG_ 1412 BMS_CellU124 8190;
BA_ "GenSigStartValue" SG_ 1412 BMS_CellU125 8190;
BA_ "GenSigStartValue" SG_ 1412 BMS_CellU126 8190;
BA_ "GenSigStartValue" SG_ 1412 BMS_CellU127 8190;
BA_ "GenSigStartValue" SG_ 1412 BMS_CellU128 8190;
BA_ "GenSigStartValue" SG_ 1412 BMS_CellU129 8190;
BA_ "GenSigStartValue" SG_ 1412 BMS_CellU130 8190;
BA_ "GenSigStartValue" SG_ 1412 BMS_CellU131 8190;
BA_ "GenSigStartValue" SG_ 1412 BMS_CellU132 8190;
BA_ "GenSigStartValue" SG_ 1412 BMS_CellU133 8190;
BA_ "GenSigStartValue" SG_ 1412 BMS_CellU134 8190;
BA_ "GenSigStartValue" SG_ 1412 BMS_CellU135 8190;
BA_ "GenSigStartValue" SG_ 1412 BMS_CellU136 8190;
BA_ "GenSigStartValue" SG_ 1412 BMS_CellU137 8190;
BA_ "GenSigStartValue" SG_ 1412 BMS_CellU138 8190;
BA_ "GenSigStartValue" SG_ 1412 BMS_CellU139 8190;
BA_ "GenSigStartValue" SG_ 1412 BMS_CellU140 8190;
BA_ "GenSigStartValue" SG_ 1412 BMS_CellU141 8190;
BA_ "GenSigStartValue" SG_ 1412 BMS_CellU142 8190;
BA_ "GenSigStartValue" SG_ 1412 BMS_CellU143 8190;
BA_ "GenSigStartValue" SG_ 1412 BMS_CellU144 8190;
BA_ "GenSigStartValue" SG_ 1412 BMS_CellU145 8190;
BA_ "GenSigStartValue" SG_ 1412 BMS_CellU146 8190;
BA_ "GenSigStartValue" SG_ 1412 BMS_CellU147 8190;
BA_ "GenSigStartValue" SG_ 1412 BMS_CellU148 8190;
BA_ "GenSigStartValue" SG_ 1412 BMS_CellU149 8190;
BA_ "GenSigStartValue" SG_ 1412 BMS_CellU150 8190;
BA_ "GenSigStartValue" SG_ 1412 BMS_CellU151 8190;
BA_ "GenSigStartValue" SG_ 1412 BMS_CellU152 8190;
BA_ "GenSigStartValue" SG_ 1412 BMS_CellU153 8190;
BA_ "GenSigStartValue" SG_ 1412 BMS_CellU154 8190;
BA_ "GenSigStartValue" SG_ 1412 BMS_CellU155 8190;
BA_ "GenSigStartValue" SG_ 1412 BMS_CellU156 8190;
// Frame: BMS_VoltSerials5
BA_ "VFrameFormat" BO_ 1413 14;
BA_ "GenMsgCycleTime" BO_ 1413 1000.000;
BA_ "GenMsgStartDelayTime" BO_ 1413 0.000;
BA_ "GenSigStartValue" SG_ 1413 BMS_CellU157 8190;
BA_ "GenSigStartValue" SG_ 1413 BMS_CellU158 8190;
BA_ "GenSigStartValue" SG_ 1413 BMS_CellU159 8190;
BA_ "GenSigStartValue" SG_ 1413 BMS_CellU160 8190;
BA_ "GenSigStartValue" SG_ 1413 BMS_CellU161 8190;
BA_ "GenSigStartValue" SG_ 1413 BMS_CellU162 8190;
BA_ "GenSigStartValue" SG_ 1413 BMS_CellU163 8190;
BA_ "GenSigStartValue" SG_ 1413 BMS_CellU164 8190;
BA_ "GenSigStartValue" SG_ 1413 BMS_CellU165 8190;
BA_ "GenSigStartValue" SG_ 1413 BMS_CellU166 8190;
BA_ "GenSigStartValue" SG_ 1413 BMS_CellU167 8190;
BA_ "GenSigStartValue" SG_ 1413 BMS_CellU168 8190;
BA_ "GenSigStartValue" SG_ 1413 BMS_CellU169 8190;
BA_ "GenSigStartValue" SG_ 1413 BMS_CellU170 8190;
BA_ "GenSigStartValue" SG_ 1413 BMS_CellU171 8190;
BA_ "GenSigStartValue" SG_ 1413 BMS_CellU172 8190;
BA_ "GenSigStartValue" SG_ 1413 BMS_CellU173 8190;
BA_ "GenSigStartValue" SG_ 1413 BMS_CellU174 8190;
BA_ "GenSigStartValue" SG_ 1413 BMS_CellU175 8190;
BA_ "GenSigStartValue" SG_ 1413 BMS_CellU176 8190;
BA_ "GenSigStartValue" SG_ 1413 BMS_CellU177 8190;
BA_ "GenSigStartValue" SG_ 1413 BMS_CellU178 8190;
BA_ "GenSigStartValue" SG_ 1413 BMS_CellU179 8190;
BA_ "GenSigStartValue" SG_ 1413 BMS_CellU180 8190;
BA_ "GenSigStartValue" SG_ 1413 BMS_CellU181 8190;
BA_ "GenSigStartValue" SG_ 1413 BMS_CellU182 8190;
BA_ "GenSigStartValue" SG_ 1413 BMS_CellU183 8190;
BA_ "GenSigStartValue" SG_ 1413 BMS_CellU184 8190;
BA_ "GenSigStartValue" SG_ 1413 BMS_CellU185 8190;
BA_ "GenSigStartValue" SG_ 1413 BMS_CellU186 8190;
BA_ "GenSigStartValue" SG_ 1413 BMS_CellU187 8190;
BA_ "GenSigStartValue" SG_ 1413 BMS_CellU188 8190;
BA_ "GenSigStartValue" SG_ 1413 BMS_CellU189 8190;
BA_ "GenSigStartValue" SG_ 1413 BMS_CellU190 8190;
BA_ "GenSigStartValue" SG_ 1413 BMS_CellU191 8190;
BA_ "GenSigStartValue" SG_ 1413 BMS_CellU192 8190;
// Frame: CDU_APS_State
BA_ "VFrameFormat" BO_ 1418 14;
BA_ "GenMsgCycleTime" BO_ 1418 1000.000;
BA_ "GenMsgStartDelayTime" BO_ 1418 0.000;
BA_ "GenSigStartValue" SG_ 1418 CDU_APS_PortA_Currt1 16382;
BA_ "GenSigStartValue" SG_ 1418 CDU_APS_PortA_Currt2 16382;
BA_ "GenSigStartValue" SG_ 1418 CDU_APS_PortA_Currt3 16382;
BA_ "GenSigStartValue" SG_ 1418 CDU_APS_PortA_U1 1022;
BA_ "GenSigStartValue" SG_ 1418 CDU_APS_PortA_U2 1022;
BA_ "GenSigStartValue" SG_ 1418 CDU_APS_PortB_Currt_DCDC 16382;
BA_ "GenSigStartValue" SG_ 1418 CDU_APS_PortB_Currt_Sfty 16382;
BA_ "GenSigStartValue" SG_ 1418 CDU_APS_PortB_U1 1022;
BA_ "GenSigStartValue" SG_ 1418 CDU_APS_PortB_U2 1022;
// Frame: CDU_DCDC
BA_ "VFrameFormat" BO_ 787 14;
BA_ "GenMsgCycleTime" BO_ 787 100.000;
BA_ "GenMsgStartDelayTime" BO_ 787 0.000;
BA_ "GenSigStartValue" SG_ 787 DCDC_Oring_APS_Temp 254;
BA_ "GenSigStartValue" SG_ 787 DCDC_PNGSt 1;
// Frame: CDU_Fault
BA_ "VFrameFormat" BO_ 1306 14;
BA_ "GenMsgCycleTime" BO_ 1306 500.000;
BA_ "GenMsgStartDelayTime" BO_ 1306 0.000;
// Frame: CDU_OBC_1
BA_ "VFrameFormat" BO_ 790 14;
BA_ "GenMsgCycleTime" BO_ 790 100.000;
BA_ "GenMsgStartDelayTime" BO_ 790 0.000;
// Frame: CDU_OBC_2
BA_ "VFrameFormat" BO_ 794 14;
BA_ "GenMsgCycleTime" BO_ 794 100.000;
BA_ "GenMsgStartDelayTime" BO_ 794 0.000;
BA_ "GenSigStartValue" SG_ 794 CDU_KL15_Volt 254;
BA_ "GenSigStartValue" SG_ 794 CDU_KL30_Volt 254;
BA_ "GenSigStartValue" SG_ 794 OBC_ACL2Currt 1022;
BA_ "GenSigStartValue" SG_ 794 OBC_ACL2Volt 4094;
BA_ "GenSigStartValue" SG_ 794 OBC_ACL3Currt 1022;
BA_ "GenSigStartValue" SG_ 794 OBC_ACL3Volt 4094;
BA_ "GenSigStartValue" SG_ 794 OBC_DCChrgMod_LimCurrt 150;
// Frame: CDU_Version
BA_ "VFrameFormat" BO_ 1460 14;
BA_ "GenMsgCycleTime" BO_ 1460 10000.000;
BA_ "GenMsgStartDelayTime" BO_ 1460 0.000;
// Frame: Diag_FuncReq_PT
BA_ "DiagState" BO_ 2015 0;
BA_ "GenMsgSendType" BO_ 2015 1;
BA_ "VFrameFormat" BO_ 2015 14;
BA_ "GenMsgDelayTime" BO_ 2015 20.000;
// Frame: Diag_PhyReq_AGS_L
BA_ "DiagRequest" BO_ 1768 0;
BA_ "GenMsgSendType" BO_ 1768 1;
BA_ "VFrameFormat" BO_ 1768 14;
BA_ "GenMsgDelayTime" BO_ 1768 20.000;
// Frame: Diag_PhyReq_AGS_L
BA_ "VFrameFormat" BO_ 1768 14;
BA_ "GenMsgSendType" BO_ 1768 1;
BA_ "GenMsgDelayTime" BO_ 1768 20.000;
// Frame: Diag_PhyReq_AGS_R
BA_ "DiagRequest" BO_ 1769 0;
BA_ "GenMsgSendType" BO_ 1769 1;
BA_ "VFrameFormat" BO_ 1769 14;
BA_ "GenMsgDelayTime" BO_ 1769 20.000;
// Frame: Diag_PhyReq_AGS_R
BA_ "VFrameFormat" BO_ 1769 14;
BA_ "GenMsgSendType" BO_ 1769 1;
BA_ "GenMsgDelayTime" BO_ 1769 20.000;
// Frame: Diag_PhyReq_BLOWER
BA_ "DiagRequest" BO_ 1775 0;
BA_ "GenMsgSendType" BO_ 1775 1;
BA_ "VFrameFormat" BO_ 1775 14;
BA_ "GenMsgDelayTime" BO_ 1775 20.000;
// Frame: Diag_PhyReq_BLOWER
BA_ "VFrameFormat" BO_ 1775 14;
BA_ "GenMsgSendType" BO_ 1775 1;
BA_ "GenMsgDelayTime" BO_ 1775 20.000;
// Frame: Diag_PhyReq_BMS
BA_ "DiagRequest" BO_ 1811 0;
BA_ "GenMsgSendType" BO_ 1811 1;
BA_ "VFrameFormat" BO_ 1811 14;
BA_ "GenMsgDelayTime" BO_ 1811 20.000;
// Frame: Diag_PhyReq_CCU
BA_ "DiagRequest" BO_ 1814 0;
BA_ "GenMsgSendType" BO_ 1814 1;
BA_ "VFrameFormat" BO_ 1814 14;
BA_ "GenMsgDelayTime" BO_ 1814 20.000;
// Frame: Diag_PhyReq_CCU
BA_ "VFrameFormat" BO_ 1814 14;
BA_ "GenMsgSendType" BO_ 1814 1;
BA_ "GenMsgDelayTime" BO_ 1814 20.000;
// Frame: Diag_PhyReq_CDU
BA_ "DiagRequest" BO_ 1853 0;
BA_ "GenMsgSendType" BO_ 1853 1;
BA_ "VFrameFormat" BO_ 1853 14;
BA_ "GenMsgDelayTime" BO_ 1853 20.000;
// Frame: Diag_PhyReq_ECCVC
BA_ "DiagRequest" BO_ 1774 0;
BA_ "GenMsgSendType" BO_ 1774 1;
BA_ "VFrameFormat" BO_ 1774 14;
BA_ "GenMsgDelayTime" BO_ 1774 20.000;
// Frame: Diag_PhyReq_EEMWP
BA_ "DiagRequest" BO_ 1651 0;
BA_ "GenMsgSendType" BO_ 1651 1;
BA_ "VFrameFormat" BO_ 1651 14;
BA_ "GenMsgDelayTime" BO_ 1651 20.000;
// Frame: Diag_PhyReq_EMS
BA_ "DiagRequest" BO_ 2016 0;
BA_ "GenMsgSendType" BO_ 2016 1;
BA_ "VFrameFormat" BO_ 2016 14;
BA_ "GenMsgDelayTime" BO_ 2016 20.000;
// Frame: Diag_PhyReq_GCU
BA_ "DiagRequest" BO_ 1819 0;
BA_ "GenMsgSendType" BO_ 1819 1;
BA_ "VFrameFormat" BO_ 1819 14;
BA_ "GenMsgDelayTime" BO_ 1819 20.000;
// Frame: Diag_PhyReq_HPC
BA_ "DiagRequest" BO_ 1830 0;
BA_ "GenMsgSendType" BO_ 1830 1;
BA_ "VFrameFormat" BO_ 1830 14;
BA_ "GenMsgDelayTime" BO_ 1830 20.000;
// Frame: Diag_PhyReq_MCUR
BA_ "DiagRequest" BO_ 1818 0;
BA_ "GenMsgSendType" BO_ 1818 1;
BA_ "VFrameFormat" BO_ 1818 14;
BA_ "GenMsgDelayTime" BO_ 1818 20.000;
// Frame: Diag_PhyReq_PDU
BA_ "DiagRequest" BO_ 1652 0;
BA_ "GenMsgSendType" BO_ 1652 1;
BA_ "VFrameFormat" BO_ 1652 14;
BA_ "GenMsgDelayTime" BO_ 1652 20.000;
// Frame: Diag_PhyReq_PTC
BA_ "DiagRequest" BO_ 1873 0;
BA_ "GenMsgSendType" BO_ 1873 1;
BA_ "VFrameFormat" BO_ 1873 14;
BA_ "GenMsgDelayTime" BO_ 1873 20.000;
// Frame: Diag_PhyReq_PTC
BA_ "VFrameFormat" BO_ 1873 14;
BA_ "GenMsgSendType" BO_ 1873 1;
BA_ "GenMsgDelayTime" BO_ 1873 20.000;
// Frame: Diag_PhyReq_TDU
BA_ "DiagRequest" BO_ 1815 0;
BA_ "GenMsgSendType" BO_ 1815 1;
BA_ "VFrameFormat" BO_ 1815 14;
BA_ "GenMsgDelayTime" BO_ 1815 20.000;
// Frame: Diag_Resp_AGS_L
BA_ "VFrameFormat" BO_ 1784 14;
BA_ "GenMsgSendType" BO_ 1784 1;
BA_ "GenMsgDelayTime" BO_ 1784 20.000;
// Frame: Diag_Resp_AGS_R
BA_ "VFrameFormat" BO_ 1785 14;
BA_ "GenMsgSendType" BO_ 1785 1;
BA_ "GenMsgDelayTime" BO_ 1785 20.000;
// Frame: Diag_Resp_BLOWER
BA_ "VFrameFormat" BO_ 1791 14;
BA_ "GenMsgSendType" BO_ 1791 1;
BA_ "GenMsgDelayTime" BO_ 1791 20.000;
// Frame: Diag_Resp_BMS
BA_ "DiagResponse" BO_ 1939 0;
BA_ "GenMsgSendType" BO_ 1939 1;
BA_ "VFrameFormat" BO_ 1939 14;
BA_ "GenMsgDelayTime" BO_ 1939 20.000;
// Frame: Diag_Resp_CCU
BA_ "VFrameFormat" BO_ 1942 14;
BA_ "GenMsgSendType" BO_ 1942 1;
BA_ "GenMsgDelayTime" BO_ 1942 20.000;
// Frame: Diag_Resp_CDU
BA_ "DiagResponse" BO_ 1981 0;
BA_ "GenMsgSendType" BO_ 1981 1;
BA_ "VFrameFormat" BO_ 1981 14;
BA_ "GenMsgDelayTime" BO_ 1981 20.000;
// Frame: Diag_Resp_ECCVC
BA_ "DiagResponse" BO_ 1790 0;
BA_ "GenMsgSendType" BO_ 1790 1;
BA_ "VFrameFormat" BO_ 1790 14;
BA_ "GenMsgDelayTime" BO_ 1790 20.000;
// Frame: Diag_Resp_EEMWP
BA_ "DiagResponse" BO_ 1659 0;
BA_ "GenMsgSendType" BO_ 1659 1;
BA_ "VFrameFormat" BO_ 1659 14;
BA_ "GenMsgDelayTime" BO_ 1659 20.000;
// Frame: Diag_Resp_EMS
BA_ "DiagResponse" BO_ 2024 0;
BA_ "GenMsgSendType" BO_ 2024 1;
BA_ "VFrameFormat" BO_ 2024 14;
BA_ "GenMsgDelayTime" BO_ 2024 20.000;
// Frame: Diag_Resp_GCU
BA_ "DiagResponse" BO_ 1947 0;
BA_ "GenMsgSendType" BO_ 1947 1;
BA_ "VFrameFormat" BO_ 1947 14;
BA_ "GenMsgDelayTime" BO_ 1947 20.000;
// Frame: Diag_Resp_MCUR
BA_ "DiagResponse" BO_ 1946 0;
BA_ "GenMsgSendType" BO_ 1946 1;
BA_ "VFrameFormat" BO_ 1946 14;
BA_ "GenMsgDelayTime" BO_ 1946 20.000;
// Frame: Diag_Resp_PDU
BA_ "DiagResponse" BO_ 1660 0;
BA_ "GenMsgSendType" BO_ 1660 1;
BA_ "VFrameFormat" BO_ 1660 14;
BA_ "GenMsgDelayTime" BO_ 1660 20.000;
// Frame: Diag_Resp_PTC
BA_ "VFrameFormat" BO_ 2001 14;
BA_ "GenMsgSendType" BO_ 2001 1;
BA_ "GenMsgDelayTime" BO_ 2001 20.000;
// Frame: EMS_CANFD_Tester
BA_ "VFrameFormat" BO_ 872 14;
BA_ "GenMsgCycleTime" BO_ 872 100.000;
BA_ "GenMsgStartDelayTime" BO_ 872 0.000;
// Frame: EMS_Fault
BA_ "VFrameFormat" BO_ 1421 14;
BA_ "GenMsgCycleTime" BO_ 1421 500.000;
BA_ "GenMsgStartDelayTime" BO_ 1421 0.000;
// Frame: EMS_State_1
BA_ "VFrameFormat" BO_ 291 14;
BA_ "GenMsgCycleTime" BO_ 291 20.000;
BA_ "GenMsgStartDelayTime" BO_ 291 0.000;
BA_ "GenSigStartValue" SG_ 291 EMS_OilSnsrResistorVal 510;
// Frame: EMS_State_2
BA_ "VFrameFormat" BO_ 386 14;
BA_ "GenMsgCycleTime" BO_ 386 50.000;
BA_ "GenMsgStartDelayTime" BO_ 386 0.000;
BA_ "GenSigStartValue" SG_ 386 EMS_TWVE_ActPerc 126;
BA_ "GenSigStartValue" SG_ 386 EMS_TWVE_TrgtPerc 126;
// Frame: EMS_Tq_Spd
BA_ "VFrameFormat" BO_ 290 14;
BA_ "GenMsgCycleTime" BO_ 290 10.000;
BA_ "GenMsgStartDelayTime" BO_ 290 0.000;
BA_ "GenSigStartValue" SG_ 290 EMS_MaxSpdWorkpointReq 3000;
BA_ "GenSigStartValue" SG_ 290 EMS_MaxTqWorkpointReq 1300;
BA_ "GenSigStartValue" SG_ 290 EMS_MinTqWorkpointReq 900;
// Frame: EMS_Version
BA_ "VFrameFormat" BO_ 1553 14;
BA_ "GenMsgCycleTime" BO_ 1553 10000.000;
BA_ "GenMsgStartDelayTime" BO_ 1553 0.000;
// Frame: ESSPTC_HVStsFD
BA_ "VFrameFormat" BO_ 909 14;
BA_ "GenMsgCycleTime" BO_ 909 100.000;
BA_ "GenMsgStartDelayTime" BO_ 909 0.000;
// Frame: GCU_Fault
BA_ "VFrameFormat" BO_ 1423 14;
BA_ "GenMsgCycleTime" BO_ 1423 500.000;
BA_ "GenMsgStartDelayTime" BO_ 1423 0.000;
// Frame: GCU_State_1
BA_ "VFrameFormat" BO_ 294 14;
BA_ "GenMsgCycleTime" BO_ 294 20.000;
BA_ "GenMsgStartDelayTime" BO_ 294 0.000;
BA_ "GenSigStartValue" SG_ 294 GCU_ActEff 254;
BA_ "GenSigStartValue" SG_ 294 GCU_ActMaxVolt 8190;
BA_ "GenSigStartValue" SG_ 294 GCU_ActMinVolt 8190;
BA_ "GenSigStartValue" SG_ 294 GCU_CurrtPhaA 32768;
BA_ "GenSigStartValue" SG_ 294 GCU_CurrtPhaB 32768;
BA_ "GenSigStartValue" SG_ 294 GCU_CurrtPhaC 32768;
BA_ "GenSigStartValue" SG_ 294 GCU_DCCurrt 10000;
// Frame: GCU_State_2
BA_ "VFrameFormat" BO_ 799 14;
BA_ "GenMsgCycleTime" BO_ 799 100.000;
BA_ "GenMsgStartDelayTime" BO_ 799 0.000;
BA_ "GenSigStartValue" SG_ 799 GCU_IGBTTempA 48;
BA_ "GenSigStartValue" SG_ 799 GCU_IGBTTempA_Chip 48;
BA_ "GenSigStartValue" SG_ 799 GCU_IGBTTempB 48;
BA_ "GenSigStartValue" SG_ 799 GCU_IGBTTempB_Chip 48;
BA_ "GenSigStartValue" SG_ 799 GCU_IGBTTempC 48;
BA_ "GenSigStartValue" SG_ 799 GCU_IGBTTempC_Chip 48;
BA_ "GenSigStartValue" SG_ 799 GCU_KL15Volt 254;
BA_ "GenSigStartValue" SG_ 799 GCU_KL30Volt 254;
BA_ "GenSigStartValue" SG_ 799 GCU_PCBTemp 48;
BA_ "GenSigStartValue" SG_ 799 GCU_RotorTemp 48;
BA_ "GenSigStartValue" SG_ 799 GCU_TempWinding 48;
// Frame: GCU_State_3
BA_ "VFrameFormat" BO_ 855 14;
BA_ "GenMsgCycleTime" BO_ 855 100.000;
BA_ "GenMsgStartDelayTime" BO_ 855 0.000;
BA_ "GenSigStartValue" SG_ 855 GCU_EOP_MOS_Temp 40;
// Frame: GCU_Tq_Spd
BA_ "VFrameFormat" BO_ 293 14;
BA_ "GenMsgCycleTime" BO_ 293 10.000;
BA_ "GenMsgStartDelayTime" BO_ 293 0.000;
BA_ "GenSigStartValue" SG_ 293 GCU_ActRotSpd 32768;
BA_ "GenSigStartValue" SG_ 293 GCU_ActTq 32768;
BA_ "GenSigStartValue" SG_ 293 GCU_ActUnfilteredRotSpd 32768;
BA_ "GenSigStartValue" SG_ 293 GCU_CompensationTq 255;
BA_ "GenSigStartValue" SG_ 293 GCU_MaxOutputEleTq 32768;
BA_ "GenSigStartValue" SG_ 293 GCU_MaxOutputGenTq 32768;
BA_ "GenSigStartValue" SG_ 293 GCU_RotSpdMaxLimit 400;
// Frame: GCU_Version
BA_ "VFrameFormat" BO_ 1465 14;
BA_ "GenMsgCycleTime" BO_ 1465 10000.000;
BA_ "GenMsgStartDelayTime" BO_ 1465 0.000;
// Frame: IPB_Wheel
BA_ "VFrameFormat" BO_ 279 14;
BA_ "GenMsgCycleTime" BO_ 279 10.000;
BA_ "GenMsgStartDelayTime" BO_ 279 0.000;
// Frame: MCUR_CANFD_Tester
BA_ "VFrameFormat" BO_ 873 14;
BA_ "GenMsgCycleTime" BO_ 873 100.000;
BA_ "GenMsgStartDelayTime" BO_ 873 0.000;
BA_ "GenSigStartValue" SG_ 873 MCUR_OfstAng 360;
BA_ "GenSigStartValue" SG_ 873 MCUR_UdCmd 2047;
BA_ "GenSigStartValue" SG_ 873 MCUR_UqCmd 2047;
// Frame: MCUR_Fault
BA_ "VFrameFormat" BO_ 1305 14;
BA_ "GenMsgCycleTime" BO_ 1305 500.000;
BA_ "GenMsgStartDelayTime" BO_ 1305 0.000;
// Frame: MCUR_State_1
BA_ "VFrameFormat" BO_ 262 14;
BA_ "GenMsgCycleTime" BO_ 262 10.000;
BA_ "GenMsgStartDelayTime" BO_ 262 0.000;
BA_ "GenSigStartValue" SG_ 262 MCUR_ActRotSpd 32768;
BA_ "GenSigStartValue" SG_ 262 MCUR_ActTq 32768;
BA_ "GenSigStartValue" SG_ 262 MCUR_ActUnfilteredRotSpd 32768;
BA_ "GenSigStartValue" SG_ 262 MCUR_CompensationTq 255;
BA_ "GenSigStartValue" SG_ 262 MCUR_IGBTTempA 48;
BA_ "GenSigStartValue" SG_ 262 MCUR_IGBTTempB 48;
BA_ "GenSigStartValue" SG_ 262 MCUR_IGBTTempC 48;
BA_ "GenSigStartValue" SG_ 262 MCUR_MaxOutputDriveTq 32768;
BA_ "GenSigStartValue" SG_ 262 MCUR_MaxOutputRegenTq 32768;
BA_ "GenSigStartValue" SG_ 262 MCUR_MotTemp 48;
BA_ "GenSigStartValue" SG_ 262 MCUR_RotorTemp 48;
BA_ "GenSigStartValue" SG_ 262 MCUR_RotSpdMaxLimit 400;
BA_ "GenSigStartValue" SG_ 262 MCUR_TarTq 32768;
VAL_ 1414 BMS_SnsrT1 254 "BMS_SnsrT1_254_Initial_Value" 255 "BMS_SnsrT1_255_Invalid";
VAL_ 1414 BMS_SnsrT10 254 "BMS_SnsrT10_254_Initial_Value" 255 "BMS_SnsrT10_255_Invalid";
VAL_ 1414 BMS_SnsrT11 254 "BMS_SnsrT11_254_Initial_Value" 255 "BMS_SnsrT11_255_Invalid";
VAL_ 1414 BMS_SnsrT12 254 "BMS_SnsrT12_254_Initial_Value" 255 "BMS_SnsrT12_255_Invalid";
VAL_ 1414 BMS_SnsrT13 254 "BMS_SnsrT13_254_Initial_Value" 255 "BMS_SnsrT13_255_Invalid";
VAL_ 1414 BMS_SnsrT14 254 "BMS_SnsrT14_254_Initial_Value" 255 "BMS_SnsrT14_255_Invalid";
VAL_ 1414 BMS_SnsrT15 254 "BMS_SnsrT15_254_Initial_Value" 255 "BMS_SnsrT15_255_Invalid";
VAL_ 1414 BMS_SnsrT16 254 "BMS_SnsrT16_254_Initial_Value" 255 "BMS_SnsrT16_255_Invalid";
VAL_ 1414 BMS_SnsrT17 254 "BMS_SnsrT17_254_Initial_Value" 255 "BMS_SnsrT17_255_Invalid";
VAL_ 1414 BMS_SnsrT18 254 "BMS_SnsrT18_254_Initial_Value" 255 "BMS_SnsrT18_255_Invalid";
VAL_ 1414 BMS_SnsrT19 254 "BMS_SnsrT19_254_Initial_Value" 255 "BMS_SnsrT19_255_Invalid";
VAL_ 1414 BMS_SnsrT2 254 "BMS_SnsrT2_254_Initial_Value" 255 "BMS_SnsrT2_255_Invalid";
VAL_ 1414 BMS_SnsrT20 254 "BMS_SnsrT20_254_Initial_Value" 255 "BMS_SnsrT20_255_Invalid";
VAL_ 1414 BMS_SnsrT21 254 "BMS_SnsrT21_254_Initial_Value" 255 "BMS_SnsrT21_255_Invalid";
VAL_ 1414 BMS_SnsrT22 254 "BMS_SnsrT22_254_Initial_Value" 255 "BMS_SnsrT22_255_Invalid";
VAL_ 1414 BMS_SnsrT23 254 "BMS_SnsrT23_254_Initial_Value" 255 "BMS_SnsrT23_255_Invalid";
VAL_ 1414 BMS_SnsrT24 254 "BMS_SnsrT24_254_Initial_Value" 255 "BMS_SnsrT24_255_Invalid";
VAL_ 1414 BMS_SnsrT25 254 "BMS_SnsrT25_254_Initial_Value" 255 "BMS_SnsrT25_255_Invalid";
VAL_ 1414 BMS_SnsrT26 254 "BMS_SnsrT26_254_Initial_Value" 255 "BMS_SnsrT26_255_Invalid";
VAL_ 1414 BMS_SnsrT27 254 "BMS_SnsrT27_254_Initial_Value" 255 "BMS_SnsrT27_255_Invalid";
VAL_ 1414 BMS_SnsrT28 254 "BMS_SnsrT28_254_Initial_Value" 255 "BMS_SnsrT28_255_Invalid";
VAL_ 1414 BMS_SnsrT29 254 "BMS_SnsrT29_254_Initial_Value" 255 "BMS_SnsrT29_255_Invalid";
VAL_ 1414 BMS_SnsrT3 254 "BMS_SnsrT3_254_Initial_Value" 255 "BMS_SnsrT3_255_Invalid";
VAL_ 1414 BMS_SnsrT30 254 "BMS_SnsrT30_254_Initial_Value" 255 "BMS_SnsrT30_255_Invalid";
VAL_ 1414 BMS_SnsrT31 254 "BMS_SnsrT31_254_Initial_Value" 255 "BMS_SnsrT31_255_Invalid";
VAL_ 1414 BMS_SnsrT32 254 "BMS_SnsrT32_254_Initial_Value" 255 "BMS_SnsrT32_255_Invalid";
VAL_ 1414 BMS_SnsrT33 254 "BMS_SnsrT33_254_Initial_Value" 255 "BMS_SnsrT33_255_Invalid";
VAL_ 1414 BMS_SnsrT34 254 "BMS_SnsrT34_254_Initial_Value" 255 "BMS_SnsrT34_255_Invalid";
VAL_ 1414 BMS_SnsrT35 254 "BMS_SnsrT35_254_Initial_Value" 255 "BMS_SnsrT35_255_Invalid";
VAL_ 1414 BMS_SnsrT36 254 "BMS_SnsrT36_254_Initial_Value" 255 "BMS_SnsrT36_255_Invalid";
VAL_ 1414 BMS_SnsrT37 254 "BMS_SnsrT37_254_Initial_Value" 255 "BMS_SnsrT37_255_Invalid";
VAL_ 1414 BMS_SnsrT38 254 "BMS_SnsrT38_254_Initial_Value" 255 "BMS_SnsrT38_255_Invalid";
VAL_ 1414 BMS_SnsrT39 254 "BMS_SnsrT39_254_Initial_Value" 255 "BMS_SnsrT39_255_Invalid";
VAL_ 1414 BMS_SnsrT4 254 "BMS_SnsrT4_254_Initial_Value" 255 "BMS_SnsrT4_255_Invalid";
VAL_ 1414 BMS_SnsrT40 254 "BMS_SnsrT40_254_Initial_Value" 255 "BMS_SnsrT40_255_Invalid";
VAL_ 1414 BMS_SnsrT41 254 "BMS_SnsrT41_254_Initial_Value" 255 "BMS_SnsrT41_255_Invalid";
VAL_ 1414 BMS_SnsrT42 254 "BMS_SnsrT42_254_Initial_Value" 255 "BMS_SnsrT42_255_Invalid";
VAL_ 1414 BMS_SnsrT43 254 "BMS_SnsrT43_254_Initial_Value" 255 "BMS_SnsrT43_255_Invalid";
VAL_ 1414 BMS_SnsrT44 254 "BMS_SnsrT44_254_Initial_Value" 255 "BMS_SnsrT44_255_Invalid";
VAL_ 1414 BMS_SnsrT45 254 "BMS_SnsrT45_254_Initial_Value" 255 "BMS_SnsrT45_255_Invalid";
VAL_ 1414 BMS_SnsrT46 254 "BMS_SnsrT46_254_Initial_Value" 255 "BMS_SnsrT46_255_Invalid";
VAL_ 1414 BMS_SnsrT47 254 "BMS_SnsrT47_254_Initial_Value" 255 "BMS_SnsrT47_255_Invalid";
VAL_ 1414 BMS_SnsrT48 254 "BMS_SnsrT48_254_Initial_Value" 255 "BMS_SnsrT48_255_Invalid";
VAL_ 1414 BMS_SnsrT49 254 "BMS_SnsrT49_254_Initial_Value" 255 "BMS_SnsrT49_255_Invalid";
VAL_ 1414 BMS_SnsrT5 254 "BMS_SnsrT5_254_Initial_Value" 255 "BMS_SnsrT5_255_Invalid";
VAL_ 1414 BMS_SnsrT50 254 "BMS_SnsrT50_254_Initial_Value" 255 "BMS_SnsrT50_255_Invalid";
VAL_ 1414 BMS_SnsrT51 254 "BMS_SnsrT51_254_Initial_Value" 255 "BMS_SnsrT51_255_Invalid";
VAL_ 1414 BMS_SnsrT52 254 "BMS_SnsrT52_254_Initial_Value" 255 "BMS_SnsrT52_255_Invalid";
VAL_ 1414 BMS_SnsrT53 254 "BMS_SnsrT53_254_Initial_Value" 255 "BMS_SnsrT53_255_Invalid";
VAL_ 1414 BMS_SnsrT54 254 "BMS_SnsrT54_254_Initial_Value" 255 "BMS_SnsrT54_255_Invalid";
VAL_ 1414 BMS_SnsrT55 254 "BMS_SnsrT55_254_Initial_Value" 255 "BMS_SnsrT55_255_Invalid";
VAL_ 1414 BMS_SnsrT56 254 "BMS_SnsrT56_254_Initial_Value" 255 "BMS_SnsrT56_255_Invalid";
VAL_ 1414 BMS_SnsrT57 254 "BMS_SnsrT57_254_Initial_Value" 255 "BMS_SnsrT57_255_Invalid";
VAL_ 1414 BMS_SnsrT58 254 "BMS_SnsrT58_254_Initial_Value" 255 "BMS_SnsrT58_255_Invalid";
VAL_ 1414 BMS_SnsrT59 254 "BMS_SnsrT59_254_Initial_Value" 255 "BMS_SnsrT59_255_Invalid";
VAL_ 1414 BMS_SnsrT6 254 "BMS_SnsrT6_254_Initial_Value" 255 "BMS_SnsrT6_255_Invalid";
VAL_ 1414 BMS_SnsrT60 254 "BMS_SnsrT60_254_Initial_Value" 255 "BMS_SnsrT60_255_Invalid";
VAL_ 1414 BMS_SnsrT61 254 "BMS_SnsrT61_254_Initial_Value" 255 "BMS_SnsrT61_255_Invalid";
VAL_ 1414 BMS_SnsrT62 254 "BMS_SnsrT62_254_Initial_Value" 255 "BMS_SnsrT62_255_Invalid";
VAL_ 1414 BMS_SnsrT63 254 "BMS_SnsrT63_254_Initial_Value" 255 "BMS_SnsrT63_255_Invalid";
VAL_ 1414 BMS_SnsrT7 254 "BMS_SnsrT7_254_Initial_Value" 255 "BMS_SnsrT7_255_Invalid";
VAL_ 1414 BMS_SnsrT8 254 "BMS_SnsrT8_254_Initial_Value" 255 "BMS_SnsrT8_255_Invalid";
VAL_ 1414 BMS_SnsrT9 254 "BMS_SnsrT9_254_Initial_Value" 255 "BMS_SnsrT9_255_Invalid";
VAL_ 1457 BMS_CanMatrixMajorVersion 255 "BMS_CanMatrixMajorVersion_255_Invalid";
VAL_ 1457 BMS_CanMatrixMinorVersion 255 "BMS_CanMatrixMinorVersion_255_Invalid";
VAL_ 1457 BMS_CanMatrixPatchVersion 255 "BMS_CanMatrixPatchVersion_255_Invalid";
VAL_ 1457 BMS_CellPrmTblMajorVersion 255 "BMS_CellPrmTblMajorVersion_255_Invalid";
VAL_ 1457 BMS_CellPrmTblMinorVersion 255 "BMS_CellPrmTblMinorVersion_255_Invalid";
VAL_ 1457 BMS_CellPrmTblPatchVersion 255 "BMS_CellPrmTblPatchVersion_255_Invalid";
VAL_ 1457 BMS_FltDiagTblMajorVersion 255 "BMS_FltDiagTblMajorVersion_255_Invalid";
VAL_ 1457 BMS_FltDiagTblMinorVersion 255 "BMS_FltDiagTblMinorVersion_255_Invalid";
VAL_ 1457 BMS_FltDiagTblPatchVersion 255 "BMS_FltDiagTblPatchVersion_255_Invalid";
VAL_ 1409 BMS_CellU1 8190 "BMS_CellU1_8190_Initial_Value" 8191 "BMS_CellU1_8191_Invalid";
VAL_ 1409 BMS_CellU10 8190 "BMS_CellU10_8190_Initial_Value" 8191 "BMS_CellU10_8191_Invalid";
VAL_ 1409 BMS_CellU11 8190 "BMS_CellU11_8190_Initial_Value" 8191 "BMS_CellU11_8191_Invalid";
VAL_ 1409 BMS_CellU12 8190 "BMS_CellU12_8190_Initial_Value" 8191 "BMS_CellU12_8191_Invalid";
VAL_ 1409 BMS_CellU13 8190 "BMS_CellU13_8190_Initial_Value" 8191 "BMS_CellU13_8191_Invalid";
VAL_ 1409 BMS_CellU14 8190 "BMS_CellU14_8190_Initial_Value" 8191 "BMS_CellU14_8191_Invalid";
VAL_ 1409 BMS_CellU15 8190 "BMS_CellU15_8190_Initial_Value" 8191 "BMS_CellU15_8191_Invalid";
VAL_ 1409 BMS_CellU16 8190 "BMS_CellU16_8190_Initial_Value" 8191 "BMS_CellU16_8191_Invalid";
VAL_ 1409 BMS_CellU17 8190 "BMS_CellU17_8190_Initial_Value" 8191 "BMS_CellU17_8191_Invalid";
VAL_ 1409 BMS_CellU18 8190 "BMS_CellU18_8190_Initial_Value" 8191 "BMS_CellU18_8191_Invalid";
VAL_ 1409 BMS_CellU19 8190 "BMS_CellU19_8190_Initial_Value" 8191 "BMS_CellU19_8191_Invalid";
VAL_ 1409 BMS_CellU2 8190 "BMS_CellU2_8190_Initial_Value" 8191 "BMS_CellU2_8191_Invalid";
VAL_ 1409 BMS_CellU20 8190 "BMS_CellU20_8190_Initial_Value" 8191 "BMS_CellU20_8191_Invalid";
VAL_ 1409 BMS_CellU21 8190 "BMS_CellU21_8190_Initial_Value" 8191 "BMS_CellU21_8191_Invalid";
VAL_ 1409 BMS_CellU22 8190 "BMS_CellU22_8190_Initial_Value" 8191 "BMS_CellU22_8191_Invalid";
VAL_ 1409 BMS_CellU23 8190 "BMS_CellU23_8190_Initial_Value" 8191 "BMS_CellU23_8191_Invalid";
VAL_ 1409 BMS_CellU24 8190 "BMS_CellU24_8190_Initial_Value" 8191 "BMS_CellU24_8191_Invalid";
VAL_ 1409 BMS_CellU25 8190 "BMS_CellU25_8190_Initial_Value" 8191 "BMS_CellU25_8191_Invalid";
VAL_ 1409 BMS_CellU26 8190 "BMS_CellU26_8190_Initial_Value" 8191 "BMS_CellU26_8191_Invalid";
VAL_ 1409 BMS_CellU27 8190 "BMS_CellU27_8190_Initial_Value" 8191 "BMS_CellU27_8191_Invalid";
VAL_ 1409 BMS_CellU28 8190 "BMS_CellU28_8190_Initial_Value" 8191 "BMS_CellU28_8191_Invalid";
VAL_ 1409 BMS_CellU29 8190 "BMS_CellU29_8190_Initial_Value" 8191 "BMS_CellU29_8191_Invalid";
VAL_ 1409 BMS_CellU3 8190 "BMS_CellU3_8190_Initial_Value" 8191 "BMS_CellU3_8191_Invalid";
VAL_ 1409 BMS_CellU30 8190 "BMS_CellU30_8190_Initial_Value" 8191 "BMS_CellU30_8191_Invalid";
VAL_ 1409 BMS_CellU31 8190 "BMS_CellU31_8190_Initial_Value" 8191 "BMS_CellU31_8191_Invalid";
VAL_ 1409 BMS_CellU32 8190 "BMS_CellU32_8190_Initial_Value" 8191 "BMS_CellU32_8191_Invalid";
VAL_ 1409 BMS_CellU33 8190 "BMS_CellU33_8190_Initial_Value" 8191 "BMS_CellU33_8191_Invalid";
VAL_ 1409 BMS_CellU34 8190 "BMS_CellU34_8190_Initial_Value" 8191 "BMS_CellU34_8191_Invalid";
VAL_ 1409 BMS_CellU35 8190 "BMS_CellU35_8190_Initial_Value" 8191 "BMS_CellU35_8191_Invalid";
VAL_ 1409 BMS_CellU36 8190 "BMS_CellU36_8190_Initial_Value" 8191 "BMS_CellU36_8191_Invalid";
VAL_ 1409 BMS_CellU37 8190 "BMS_CellU37_8190_Initial_Value" 8191 "BMS_CellU37_8191_Invalid";
VAL_ 1409 BMS_CellU38 8190 "BMS_CellU38_8190_Initial_Value" 8191 "BMS_CellU38_8191_Invalid";
VAL_ 1409 BMS_CellU39 8190 "BMS_CellU39_8190_Initial_Value" 8191 "BMS_CellU39_8191_Invalid";
VAL_ 1409 BMS_CellU4 8190 "BMS_CellU4_8190_Initial_Value" 8191 "BMS_CellU4_8191_Invalid";
VAL_ 1409 BMS_CellU5 8190 "BMS_CellU5_8190_Initial_Value" 8191 "BMS_CellU5_8191_Invalid";
VAL_ 1409 BMS_CellU6 8190 "BMS_CellU6_8190_Initial_Value" 8191 "BMS_CellU6_8191_Invalid";
VAL_ 1409 BMS_CellU7 8190 "BMS_CellU7_8190_Initial_Value" 8191 "BMS_CellU7_8191_Invalid";
VAL_ 1409 BMS_CellU8 8190 "BMS_CellU8_8190_Initial_Value" 8191 "BMS_CellU8_8191_Invalid";
VAL_ 1409 BMS_CellU9 8190 "BMS_CellU9_8190_Initial_Value" 8191 "BMS_CellU9_8191_Invalid";
VAL_ 1410 BMS_CellU40 8190 "BMS_CellU40_8190_Initial_Value" 8191 "BMS_CellU40_8191_Invalid";
VAL_ 1410 BMS_CellU41 8190 "BMS_CellU41_8190_Initial_Value" 8191 "BMS_CellU41_8191_Invalid";
VAL_ 1410 BMS_CellU42 8190 "BMS_CellU42_8190_Initial_Value" 8191 "BMS_CellU42_8191_Invalid";
VAL_ 1410 BMS_CellU43 8190 "BMS_CellU43_8190_Initial_Value" 8191 "BMS_CellU43_8191_Invalid";
VAL_ 1410 BMS_CellU44 8190 "BMS_CellU44_8190_Initial_Value" 8191 "BMS_CellU44_8191_Invalid";
VAL_ 1410 BMS_CellU45 8190 "BMS_CellU45_8190_Initial_Value" 8191 "BMS_CellU45_8191_Invalid";
VAL_ 1410 BMS_CellU46 8190 "BMS_CellU46_8190_Initial_Value" 8191 "BMS_CellU46_8191_Invalid";
VAL_ 1410 BMS_CellU47 8190 "BMS_CellU47_8190_Initial_Value" 8191 "BMS_CellU47_8191_Invalid";
VAL_ 1410 BMS_CellU48 8190 "BMS_CellU48_8190_Initial_Value" 8191 "BMS_CellU48_8191_Invalid";
VAL_ 1410 BMS_CellU49 8190 "BMS_CellU49_8190_Initial_Value" 8191 "BMS_CellU49_8191_Invalid";
VAL_ 1410 BMS_CellU50 8190 "BMS_CellU50_8190_Initial_Value" 8191 "BMS_CellU50_8191_Invalid";
VAL_ 1410 BMS_CellU51 8190 "BMS_CellU51_8190_Initial_Value" 8191 "BMS_CellU51_8191_Invalid";
VAL_ 1410 BMS_CellU52 8190 "BMS_CellU52_8190_Initial_Value" 8191 "BMS_CellU52_8191_Invalid";
VAL_ 1410 BMS_CellU53 8190 "BMS_CellU53_8190_Initial_Value" 8191 "BMS_CellU53_8191_Invalid";
VAL_ 1410 BMS_CellU54 8190 "BMS_CellU54_8190_Initial_Value" 8191 "BMS_CellU54_8191_Invalid";
VAL_ 1410 BMS_CellU55 8190 "BMS_CellU55_8190_Initial_Value" 8191 "BMS_CellU55_8191_Invalid";
VAL_ 1410 BMS_CellU56 8190 "BMS_CellU56_8190_Initial_Value" 8191 "BMS_CellU56_8191_Invalid";
VAL_ 1410 BMS_CellU57 8190 "BMS_CellU57_8190_Initial_Value" 8191 "BMS_CellU57_8191_Invalid";
VAL_ 1410 BMS_CellU58 8190 "BMS_CellU58_8190_Initial_Value" 8191 "BMS_CellU58_8191_Invalid";
VAL_ 1410 BMS_CellU59 8190 "BMS_CellU59_8190_Initial_Value" 8191 "BMS_CellU59_8191_Invalid";
VAL_ 1410 BMS_CellU60 8190 "BMS_CellU60_8190_Initial_Value" 8191 "BMS_CellU60_8191_Invalid";
VAL_ 1410 BMS_CellU61 8190 "BMS_CellU61_8190_Initial_Value" 8191 "BMS_CellU61_8191_Invalid";
VAL_ 1410 BMS_CellU62 8190 "BMS_CellU62_8190_Initial_Value" 8191 "BMS_CellU62_8191_Invalid";
VAL_ 1410 BMS_CellU63 8190 "BMS_CellU63_8190_Initial_Value" 8191 "BMS_CellU63_8191_Invalid";
VAL_ 1410 BMS_CellU64 8190 "BMS_CellU64_8190_Initial_Value" 8191 "BMS_CellU64_8191_Invalid";
VAL_ 1410 BMS_CellU65 8190 "BMS_CellU65_8190_Initial_Value" 8191 "BMS_CellU65_8191_Invalid";
VAL_ 1410 BMS_CellU66 8190 "BMS_CellU66_8190_Initial_Value" 8191 "BMS_CellU66_8191_Invalid";
VAL_ 1410 BMS_CellU67 8190 "BMS_CellU67_8190_Initial_Value" 8191 "BMS_CellU67_8191_Invalid";
VAL_ 1410 BMS_CellU68 8190 "BMS_CellU68_8190_Initial_Value" 8191 "BMS_CellU68_8191_Invalid";
VAL_ 1410 BMS_CellU69 8190 "BMS_CellU69_8190_Initial_Value" 8191 "BMS_CellU69_8191_Invalid";
VAL_ 1410 BMS_CellU70 8190 "BMS_CellU70_8190_Initial_Value" 8191 "BMS_CellU70_8191_Invalid";
VAL_ 1410 BMS_CellU71 8190 "BMS_CellU71_8190_Initial_Value" 8191 "BMS_CellU71_8191_Invalid";
VAL_ 1410 BMS_CellU72 8190 "BMS_CellU72_8190_Initial_Value" 8191 "BMS_CellU72_8191_Invalid";
VAL_ 1410 BMS_CellU73 8190 "BMS_CellU73_8190_Initial_Value" 8191 "BMS_CellU73_8191_Invalid";
VAL_ 1410 BMS_CellU74 8190 "BMS_CellU74_8190_Initial_Value" 8191 "BMS_CellU74_8191_Invalid";
VAL_ 1410 BMS_CellU75 8190 "BMS_CellU75_8190_Initial_Value" 8191 "BMS_CellU75_8191_Invalid";
VAL_ 1410 BMS_CellU76 8190 "BMS_CellU76_8190_Initial_Value" 8191 "BMS_CellU76_8191_Invalid";
VAL_ 1410 BMS_CellU77 8190 "BMS_CellU77_8190_Initial_Value" 8191 "BMS_CellU77_8191_Invalid";
VAL_ 1410 BMS_CellU78 8190 "BMS_CellU78_8190_Initial_Value" 8191 "BMS_CellU78_8191_Invalid";
VAL_ 1411 BMS_CellU100 8190 "BMS_CellU100_8190_Initial_Value" 8191 "BMS_CellU100_8191_Invalid";
VAL_ 1411 BMS_CellU101 8190 "BMS_CellU101_8190_Initial_Value" 8191 "BMS_CellU101_8191_Invalid";
VAL_ 1411 BMS_CellU102 8190 "BMS_CellU102_8190_Initial_Value" 8191 "BMS_CellU102_8191_Invalid";
VAL_ 1411 BMS_CellU103 8190 "BMS_CellU103_8190_Initial_Value" 8191 "BMS_CellU103_8191_Invalid";
VAL_ 1411 BMS_CellU104 8190 "BMS_CellU104_8190_Initial_Value" 8191 "BMS_CellU104_8191_Invalid";
VAL_ 1411 BMS_CellU105 8190 "BMS_CellU105_8190_Initial_Value" 8191 "BMS_CellU105_8191_Invalid";
VAL_ 1411 BMS_CellU106 8190 "BMS_CellU106_8190_Initial_Value" 8191 "BMS_CellU106_8191_Invalid";
VAL_ 1411 BMS_CellU107 8190 "BMS_CellU107_8190_Initial_Value" 8191 "BMS_CellU107_8191_Invalid";
VAL_ 1411 BMS_CellU108 8190 "BMS_CellU108_8190_Initial_Value" 8191 "BMS_CellU108_8191_Invalid";
VAL_ 1411 BMS_CellU109 8190 "BMS_CellU109_8190_Initial_Value" 8191 "BMS_CellU109_8191_Invalid";
VAL_ 1411 BMS_CellU110 8190 "BMS_CellU110_8190_Initial_Value" 8191 "BMS_CellU110_8191_Invalid";
VAL_ 1411 BMS_CellU111 8190 "BMS_CellU111_8190_Initial_Value" 8191 "BMS_CellU111_8191_Invalid";
VAL_ 1411 BMS_CellU112 8190 "BMS_CellU112_8190_Initial_Value" 8191 "BMS_CellU112_8191_Invalid";
VAL_ 1411 BMS_CellU113 8190 "BMS_CellU113_8190_Initial_Value" 8191 "BMS_CellU113_8191_Invalid";
VAL_ 1411 BMS_CellU114 8190 "BMS_CellU114_8190_Initial_Value" 8191 "BMS_CellU114_8191_Invalid";
VAL_ 1411 BMS_CellU115 8190 "BMS_CellU115_8190_Initial_Value" 8191 "BMS_CellU115_8191_Invalid";
VAL_ 1411 BMS_CellU116 8190 "BMS_CellU116_8190_Initial_Value" 8191 "BMS_CellU116_8191_Invalid";
VAL_ 1411 BMS_CellU117 8190 "BMS_CellU117_8190_Initial_Value" 8191 "BMS_CellU117_8191_Invalid";
VAL_ 1411 BMS_CellU79 8190 "BMS_CellU79_8190_Initial_Value" 8191 "BMS_CellU79_8191_Invalid";
VAL_ 1411 BMS_CellU80 8190 "BMS_CellU80_8190_Initial_Value" 8191 "BMS_CellU80_8191_Invalid";
VAL_ 1411 BMS_CellU81 8190 "BMS_CellU81_8190_Initial_Value" 8191 "BMS_CellU81_8191_Invalid";
VAL_ 1411 BMS_CellU82 8190 "BMS_CellU82_8190_Initial_Value" 8191 "BMS_CellU82_8191_Invalid";
VAL_ 1411 BMS_CellU83 8190 "BMS_CellU83_8190_Initial_Value" 8191 "BMS_CellU83_8191_Invalid";
VAL_ 1411 BMS_CellU84 8190 "BMS_CellU84_8190_Initial_Value" 8191 "BMS_CellU84_8191_Invalid";
VAL_ 1411 BMS_CellU85 8190 "BMS_CellU85_8190_Initial_Value" 8191 "BMS_CellU85_8191_Invalid";
VAL_ 1411 BMS_CellU86 8190 "BMS_CellU86_8190_Initial_Value" 8191 "BMS_CellU86_8191_Invalid";
VAL_ 1411 BMS_CellU87 8190 "BMS_CellU87_8190_Initial_Value" 8191 "BMS_CellU87_8191_Invalid";
VAL_ 1411 BMS_CellU88 8190 "BMS_CellU88_8190_Initial_Value" 8191 "BMS_CellU88_8191_Invalid";
VAL_ 1411 BMS_CellU89 8190 "BMS_CellU89_8190_Initial_Value" 8191 "BMS_CellU89_8191_Invalid";
VAL_ 1411 BMS_CellU90 8190 "BMS_CellU90_8190_Initial_Value" 8191 "BMS_CellU90_8191_Invalid";
VAL_ 1411 BMS_CellU91 8190 "BMS_CellU91_8190_Initial_Value" 8191 "BMS_CellU91_8191_Invalid";
VAL_ 1411 BMS_CellU92 8190 "BMS_CellU92_8190_Initial_Value" 8191 "BMS_CellU92_8191_Invalid";
VAL_ 1411 BMS_CellU93 8190 "BMS_CellU93_8190_Initial_Value" 8191 "BMS_CellU93_8191_Invalid";
VAL_ 1411 BMS_CellU94 8190 "BMS_CellU94_8190_Initial_Value" 8191 "BMS_CellU94_8191_Invalid";
VAL_ 1411 BMS_CellU95 8190 "BMS_CellU95_8190_Initial_Value" 8191 "BMS_CellU95_8191_Invalid";
VAL_ 1411 BMS_CellU96 8190 "BMS_CellU96_8190_Initial_Value" 8191 "BMS_CellU96_8191_Invalid";
VAL_ 1411 BMS_CellU97 8190 "BMS_CellU97_8190_Initial_Value" 8191 "BMS_CellU97_8191_Invalid";
VAL_ 1411 BMS_CellU98 8190 "BMS_CellU98_8190_Initial_Value" 8191 "BMS_CellU98_8191_Invalid";
VAL_ 1411 BMS_CellU99 8190 "BMS_CellU99_8190_Initial_Value" 8191 "BMS_CellU99_8191_Invalid";
VAL_ 1412 BMS_CellU118 8190 "BMS_CellU118_8190_Initial_Value" 8191 "BMS_CellU118_8191_Invalid";
VAL_ 1412 BMS_CellU119 8190 "BMS_CellU119_8190_Initial_Value" 8191 "BMS_CellU119_8191_Invalid";
VAL_ 1412 BMS_CellU120 8190 "BMS_CellU120_8190_Initial_Value" 8191 "BMS_CellU120_8191_Invalid";
VAL_ 1412 BMS_CellU121 8190 "BMS_CellU121_8190_Initial_Value" 8191 "BMS_CellU121_8191_Invalid";
VAL_ 1412 BMS_CellU122 8190 "BMS_CellU122_8190_Initial_Value" 8191 "BMS_CellU122_8191_Invalid";
VAL_ 1412 BMS_CellU123 8190 "BMS_CellU123_8190_Initial_Value" 8191 "BMS_CellU123_8191_Invalid";
VAL_ 1412 BMS_CellU124 8190 "BMS_CellU124_8190_Initial_Value" 8191 "BMS_CellU124_8191_Invalid";
VAL_ 1412 BMS_CellU125 8190 "BMS_CellU125_8190_Initial_Value" 8191 "BMS_CellU125_8191_Invalid";
VAL_ 1412 BMS_CellU126 8190 "BMS_CellU126_8190_Initial_Value" 8191 "BMS_CellU126_8191_Invalid";
VAL_ 1412 BMS_CellU127 8190 "BMS_CellU127_8190_Initial_Value" 8191 "BMS_CellU127_8191_Invalid";
VAL_ 1412 BMS_CellU128 8190 "BMS_CellU128_8190_Initial_Value" 8191 "BMS_CellU128_8191_Invalid";
VAL_ 1412 BMS_CellU129 8190 "BMS_CellU129_8190_Initial_Value" 8191 "BMS_CellU129_8191_Invalid";
VAL_ 1412 BMS_CellU130 8190 "BMS_CellU130_8190_Initial_Value" 8191 "BMS_CellU130_8191_Invalid";
VAL_ 1412 BMS_CellU131 8190 "BMS_CellU131_8190_Initial_Value" 8191 "BMS_CellU131_8191_Invalid";
VAL_ 1412 BMS_CellU132 8190 "BMS_CellU132_8190_Initial_Value" 8191 "BMS_CellU132_8191_Invalid";
VAL_ 1412 BMS_CellU133 8190 "BMS_CellU133_8190_Initial_Value" 8191 "BMS_CellU133_8191_Invalid";
VAL_ 1412 BMS_CellU134 8190 "BMS_CellU134_8190_Initial_Value" 8191 "BMS_CellU134_8191_Invalid";
VAL_ 1412 BMS_CellU135 8190 "BMS_CellU135_8190_Initial_Value" 8191 "BMS_CellU135_8191_Invalid";
VAL_ 1412 BMS_CellU136 8190 "BMS_CellU136_8190_Initial_Value" 8191 "BMS_CellU136_8191_Invalid";
VAL_ 1412 BMS_CellU137 8190 "BMS_CellU137_8190_Initial_Value" 8191 "BMS_CellU137_8191_Invalid";
VAL_ 1412 BMS_CellU138 8190 "BMS_CellU138_8190_Initial_Value" 8191 "BMS_CellU138_8191_Invalid";
VAL_ 1412 BMS_CellU139 8190 "BMS_CellU139_8190_Initial_Value" 8191 "BMS_CellU139_8191_Invalid";
VAL_ 1412 BMS_CellU140 8190 "BMS_CellU140_8190_Initial_Value" 8191 "BMS_CellU140_8191_Invalid";
VAL_ 1412 BMS_CellU141 8190 "BMS_CellU141_8190_Initial_Value" 8191 "BMS_CellU141_8191_Invalid";
VAL_ 1412 BMS_CellU142 8190 "BMS_CellU142_8190_Initial_Value" 8191 "BMS_CellU142_8191_Invalid";
VAL_ 1412 BMS_CellU143 8190 "BMS_CellU143_8190_Initial_Value" 8191 "BMS_CellU143_8191_Invalid";
VAL_ 1412 BMS_CellU144 8190 "BMS_CellU144_8190_Initial_Value" 8191 "BMS_CellU144_8191_Invalid";
VAL_ 1412 BMS_CellU145 8190 "BMS_CellU145_8190_Initial_Value" 8191 "BMS_CellU145_8191_Invalid";
VAL_ 1412 BMS_CellU146 8190 "BMS_CellU146_8190_Initial_Value" 8191 "BMS_CellU146_8191_Invalid";
VAL_ 1412 BMS_CellU147 8190 "BMS_CellU147_8190_Initial_Value" 8191 "BMS_CellU147_8191_Invalid";
VAL_ 1412 BMS_CellU148 8190 "BMS_CellU148_8190_Initial_Value" 8191 "BMS_CellU148_8191_Invalid";
VAL_ 1412 BMS_CellU149 8190 "BMS_CellU149_8190_Initial_Value" 8191 "BMS_CellU149_8191_Invalid";
VAL_ 1412 BMS_CellU150 8190 "BMS_CellU150_8190_Initial_Value" 8191 "BMS_CellU150_8191_Invalid";
VAL_ 1412 BMS_CellU151 8190 "BMS_CellU151_8190_Initial_Value" 8191 "BMS_CellU151_8191_Invalid";
VAL_ 1412 BMS_CellU152 8190 "BMS_CellU152_8190_Initial_Value" 8191 "BMS_CellU152_8191_Invalid";
VAL_ 1412 BMS_CellU153 8190 "BMS_CellU153_8190_Initial_Value" 8191 "BMS_CellU153_8191_Invalid";
VAL_ 1412 BMS_CellU154 8190 "BMS_CellU154_8190_Initial_Value" 8191 "BMS_CellU154_8191_Invalid";
VAL_ 1412 BMS_CellU155 8190 "BMS_CellU155_8190_Initial_Value" 8191 "BMS_CellU155_8191_Invalid";
VAL_ 1412 BMS_CellU156 8190 "BMS_CellU156_8190_Initial_Value" 8191 "BMS_CellU156_8191_Invalid";
VAL_ 1413 BMS_CellU157 8190 "BMS_CellU157_8190_Initial_Value" 8191 "BMS_CellU157_8191_Invalid";
VAL_ 1413 BMS_CellU158 8190 "BMS_CellU158_8190_Initial_Value" 8191 "BMS_CellU158_8191_Invalid";
VAL_ 1413 BMS_CellU159 8190 "BMS_CellU159_8190_Initial_Value" 8191 "BMS_CellU159_8191_Invalid";
VAL_ 1413 BMS_CellU160 8190 "BMS_CellU160_8190_Initial_Value" 8191 "BMS_CellU160_8191_Invalid";
VAL_ 1413 BMS_CellU161 8190 "BMS_CellU161_8190_Initial_Value" 8191 "BMS_CellU161_8191_Invalid";
VAL_ 1413 BMS_CellU162 8190 "BMS_CellU162_8190_Initial_Value" 8191 "BMS_CellU162_8191_Invalid";
VAL_ 1413 BMS_CellU163 8190 "BMS_CellU163_8190_Initial_Value" 8191 "BMS_CellU163_8191_Invalid";
VAL_ 1413 BMS_CellU164 8190 "BMS_CellU164_8190_Initial_Value" 8191 "BMS_CellU164_8191_Invalid";
VAL_ 1413 BMS_CellU165 8190 "BMS_CellU165_8190_Initial_Value" 8191 "BMS_CellU165_8191_Invalid";
VAL_ 1413 BMS_CellU166 8190 "BMS_CellU166_8190_Initial_Value" 8191 "BMS_CellU166_8191_Invalid";
VAL_ 1413 BMS_CellU167 8190 "BMS_CellU167_8190_Initial_Value" 8191 "BMS_CellU167_8191_Invalid";
VAL_ 1413 BMS_CellU168 8190 "BMS_CellU168_8190_Initial_Value" 8191 "BMS_CellU168_8191_Invalid";
VAL_ 1413 BMS_CellU169 8190 "BMS_CellU169_8190_Initial_Value" 8191 "BMS_CellU169_8191_Invalid";
VAL_ 1413 BMS_CellU170 8190 "BMS_CellU170_8190_Initial_Value" 8191 "BMS_CellU170_8191_Invalid";
VAL_ 1413 BMS_CellU171 8190 "BMS_CellU171_8190_Initial_Value" 8191 "BMS_CellU171_8191_Invalid";
VAL_ 1413 BMS_CellU172 8190 "BMS_CellU172_8190_Initial_Value" 8191 "BMS_CellU172_8191_Invalid";
VAL_ 1413 BMS_CellU173 8190 "BMS_CellU173_8190_Initial_Value" 8191 "BMS_CellU173_8191_Invalid";
VAL_ 1413 BMS_CellU174 8190 "BMS_CellU174_8190_Initial_Value" 8191 "BMS_CellU174_8191_Invalid";
VAL_ 1413 BMS_CellU175 8190 "BMS_CellU175_8190_Initial_Value" 8191 "BMS_CellU175_8191_Invalid";
VAL_ 1413 BMS_CellU176 8190 "BMS_CellU176_8190_Initial_Value" 8191 "BMS_CellU176_8191_Invalid";
VAL_ 1413 BMS_CellU177 8190 "BMS_CellU177_8190_Initial_Value" 8191 "BMS_CellU177_8191_Invalid";
VAL_ 1413 BMS_CellU178 8190 "BMS_CellU178_8190_Initial_Value" 8191 "BMS_CellU178_8191_Invalid";
VAL_ 1413 BMS_CellU179 8190 "BMS_CellU179_8190_Initial_Value" 8191 "BMS_CellU179_8191_Invalid";
VAL_ 1413 BMS_CellU180 8190 "BMS_CellU180_8190_Initial_Value" 8191 "BMS_CellU180_8191_Invalid";
VAL_ 1413 BMS_CellU181 8190 "BMS_CellU181_8190_Initial_Value" 8191 "BMS_CellU181_8191_Invalid";
VAL_ 1413 BMS_CellU182 8190 "BMS_CellU182_8190_Initial_Value" 8191 "BMS_CellU182_8191_Invalid";
VAL_ 1413 BMS_CellU183 8190 "BMS_CellU183_8190_Initial_Value" 8191 "BMS_CellU183_8191_Invalid";
VAL_ 1413 BMS_CellU184 8190 "BMS_CellU184_8190_Initial_Value" 8191 "BMS_CellU184_8191_Invalid";
VAL_ 1413 BMS_CellU185 8190 "BMS_CellU185_8190_Initial_Value" 8191 "BMS_CellU185_8191_Invalid";
VAL_ 1413 BMS_CellU186 8190 "BMS_CellU186_8190_Initial_Value" 8191 "BMS_CellU186_8191_Invalid";
VAL_ 1413 BMS_CellU187 8190 "BMS_CellU187_8190_Initial_Value" 8191 "BMS_CellU187_8191_Invalid";
VAL_ 1413 BMS_CellU188 8190 "BMS_CellU188_8190_Initial_Value" 8191 "BMS_CellU188_8191_Invalid";
VAL_ 1413 BMS_CellU189 8190 "BMS_CellU189_8190_Initial_Value" 8191 "BMS_CellU189_8191_Invalid";
VAL_ 1413 BMS_CellU190 8190 "BMS_CellU190_8190_Initial_Value" 8191 "BMS_CellU190_8191_Invalid";
VAL_ 1413 BMS_CellU191 8190 "BMS_CellU191_8190_Initial_Value" 8191 "BMS_CellU191_8191_Invalid";
VAL_ 1413 BMS_CellU192 8190 "BMS_CellU192_8190_Initial_Value" 8191 "BMS_CellU192_8191_Invalid";
VAL_ 1418 CDU_APS_PortA_Currt1 16382 "CDU_APS_PortA_Currt1_16382_Initial" 16383 "CDU_APS_PortA_Currt1_16383_Invalid";
VAL_ 1418 CDU_APS_PortA_Currt2 16382 "CDU_APS_PortA_Currt2_16382_Initial" 16383 "CDU_APS_PortA_Currt2_16383_Invalid";
VAL_ 1418 CDU_APS_PortA_Currt3 16382 "CDU_APS_PortA_Currt3_16382_Initial" 16383 "CDU_APS_PortA_Currt3_16383_Invalid";
VAL_ 1418 CDU_APS_PortA_U1 1022 "CDU_APS_PortA_U1_1022_Initial" 1023 "CDU_APS_PortA_U1_1023_Invalid";
VAL_ 1418 CDU_APS_PortA_U2 1022 "CDU_APS_PortA_U2_1022_Initial" 1023 "CDU_APS_PortA_U2_1023_Invalid";
VAL_ 1418 CDU_APS_PortB_Currt_DCDC 16382 "CDU_APS_PortB_Currt_DCDC_16382_Initial" 16383 "CDU_APS_PortB_Currt_DCDC_16383_Invalid";
VAL_ 1418 CDU_APS_PortB_Currt_Sfty 16382 "CDU_APS_PortB_Currt_Sfty_16382_Initial" 16383 "CDU_APS_PortB_Currt_Sfty_16383_Invalid";
VAL_ 1418 CDU_APS_PortB_U1 1022 "CDU_APS_PortB_U1_1022_Initial" 1023 "CDU_APS_PortB_U1_1023_Invalid";
VAL_ 1418 CDU_APS_PortB_U2 1022 "CDU_APS_PortB_U2_1022_Initial" 1023 "CDU_APS_PortB_U2_1023_Invalid";
VAL_ 1418 CDU_APS_SIGN 0 "CDU_APS_SIGN_0_APS" 1 "CDU_APS_SIGN_1_No_APS";
VAL_ 787 DCDC_AlerSt 0 "DCDC_AlerSt_0_No_Error" 1 "DCDC_AlerSt_1_Error";
VAL_ 787 DCDC_CopntTemp 255 "DCDC_CopntTemp_255_Invalid";
VAL_ 787 DCDC_DeratFlag 0 "DCDC_DeratFlag_0_Nomal_Working" 1 "DCDC_DeratFlag_1_Derating_Working";
VAL_ 787 DCDC_DeratReason1 0 "DCDC_DeratReason1_0_Normal" 1 "DCDC_DeratReason1_1_Abnormal";
VAL_ 787 DCDC_DeratReason10 0 "DCDC_DeratReason10_0_Normal" 1 "DCDC_DeratReason10_1_Abnormal";
VAL_ 787 DCDC_DeratReason11 0 "DCDC_DeratReason11_0_Normal" 1 "DCDC_DeratReason11_1_Abnormal";
VAL_ 787 DCDC_DeratReason12 0 "DCDC_DeratReason12_0_Normal" 1 "DCDC_DeratReason12_1_Abnormal";
VAL_ 787 DCDC_DeratReason2 0 "DCDC_DeratReason2_0_Normal" 1 "DCDC_DeratReason2_1_Abnormal";
VAL_ 787 DCDC_DeratReason3 0 "DCDC_DeratReason3_0_Normal" 1 "DCDC_DeratReason3_1_Abnormal";
VAL_ 787 DCDC_DeratReason4 0 "DCDC_DeratReason4_0_Normal" 1 "DCDC_DeratReason4_1_Abnormal";
VAL_ 787 DCDC_DeratReason5 0 "DCDC_DeratReason5_0_Normal" 1 "DCDC_DeratReason5_1_Abnormal";
VAL_ 787 DCDC_DeratReason6 0 "DCDC_DeratReason6_0_Normal" 1 "DCDC_DeratReason6_1_Abnormal";
VAL_ 787 DCDC_DeratReason7 0 "DCDC_DeratReason7_0_Normal" 1 "DCDC_DeratReason7_1_Abnormal";
VAL_ 787 DCDC_DeratReason8 0 "DCDC_DeratReason8_0_Normal" 1 "DCDC_DeratReason8_1_Abnormal";
VAL_ 787 DCDC_DeratReason9 0 "DCDC_DeratReason9_0_Normal" 1 "DCDC_DeratReason9_1_Abnormal";
VAL_ 787 DCDC_EnergyConvrtDir 0 "DCDC_EnergyConvrtDir_0_Uni_Direction" 1 "DCDC_EnergyConvrtDir_1_Bi_Direction";
VAL_ 787 DCDC_FaultLevel 0 "DCDC_FaultLevel_0_Normal" 1 "DCDC_FaultLevel_1_Level1" 2 "DCDC_FaultLevel_2_Level2" 3 "DCDC_FaultLevel_3_Level3" 4 "DCDC_FaultLevel_4_Level4" 5 "DCDC_FaultLevel_5_Level5" 6 "DCDC_FaultLevel_6_Reseverd";
VAL_ 787 DCDC_FaultLightReq 0 "DCDC_FaultLightReq_0_No_Request" 1 "DCDC_FaultLightReq_1_Request";
VAL_ 787 DCDC_FlowReq 0 "DCDC_FlowReq_0_0" 1 "DCDC_FlowReq_1_1" 2 "DCDC_FlowReq_2_2" 3 "DCDC_FlowReq_3_3" 4 "DCDC_FlowReq_4_4" 5 "DCDC_FlowReq_5_5" 6 "DCDC_FlowReq_6_6" 7 "DCDC_FlowReq_7_7" 8 "DCDC_FlowReq_8_8" 9 "DCDC_FlowReq_9_9" 10 "DCDC_FlowReq_10_10" 11 "DCDC_FlowReq_11_11" 12 "DCDC_FlowReq_12_12" 13 "DCDC_FlowReq_13_Reserved";
VAL_ 787 DCDC_HVIL_48VDCDC_St 0 "DCDC_HVIL_48VDCDC_St_0_Not_ready" 1 "DCDC_HVIL_48VDCDC_St_1_Lock" 2 "DCDC_HVIL_48VDCDC_St_2_Unlock" 3 "DCDC_HVIL_48VDCDC_St_3_HW_Fault";
VAL_ 787 DCDC_HVIL_Batt_St 0 "DCDC_HVIL_Batt_St_0_Not_ready" 1 "DCDC_HVIL_Batt_St_1_Lock" 2 "DCDC_HVIL_Batt_St_2_Unlock" 3 "DCDC_HVIL_Batt_St_3_HW_Fault";
VAL_ 787 DCDC_HVIL_EAS_St 0 "DCDC_HVIL_EAS_St_0_Not_ready" 1 "DCDC_HVIL_EAS_St_1_Lock" 2 "DCDC_HVIL_EAS_St_2_Unlock" 3 "DCDC_HVIL_EAS_St_3_HW_Fault";
VAL_ 787 DCDC_HVIL_MCU_St 0 "DCDC_HVIL_MCU_St_0_Not_ready" 1 "DCDC_HVIL_MCU_St_1_Lock" 2 "DCDC_HVIL_MCU_St_2_Unlock" 3 "DCDC_HVIL_MCU_St_3_HW_Fault";
VAL_ 787 DCDC_HVIL_PTC_St 0 "DCDC_HVIL_PTC_St_0_Not_ready" 1 "DCDC_HVIL_PTC_St_1_Lock" 2 "DCDC_HVIL_PTC_St_2_Unlock" 3 "DCDC_HVIL_PTC_St_3_HW_Fault";
VAL_ 787 DCDC_HVIL_PTCR_St 0 "DCDC_HVIL_PTCR_St_0_Not_ready" 1 "DCDC_HVIL_PTCR_St_1_Lock" 2 "DCDC_HVIL_PTCR_St_2_Unlock" 3 "DCDC_HVIL_PTCR_St_3_HW_Fault";
VAL_ 787 DCDC_InpWtrTemp 255 "DCDC_InpWtrTemp_255_Invalid";
VAL_ 787 DCDC_IptCurrt 511 "DCDC_IptCurrt_511_Invalid";
VAL_ 787 DCDC_IptVolt 16383 "DCDC_IptVolt_16383_Invalid";
VAL_ 787 DCDC_MaxOptPwr 1023 "DCDC_MaxOptPwr_1023_Invalid";
VAL_ 787 DCDC_NoLoadCurrtFlag 0 "DCDC_NoLoadCurrtFlag_0_Not_ready" 1 "DCDC_NoLoadCurrtFlag_1_With_Load" 2 "DCDC_NoLoadCurrtFlag_2_Without_Load" 3 "DCDC_NoLoadCurrtFlag_3_Reserved";
VAL_ 787 DCDC_OperSt 0 "DCDC_OperSt_0_Initial" 1 "DCDC_OperSt_1_Standby" 2 "DCDC_OperSt_2_Work" 3 "DCDC_OperSt_3_Fault" 4 "DCDC_OperSt_4_Safety" 5 "DCDC_OperSt_5_PreSleep(Not_reported_within_100_ms)" 6 "DCDC_OperSt_6_Reserved";
VAL_ 787 DCDC_OptCurrt 4095 "DCDC_OptCurrt_4095_Invalid";
VAL_ 787 DCDC_OptVolt 1023 "DCDC_OptVolt_1023_Invalid";
VAL_ 787 DCDC_Oring_APS_Temp 254 "DCDC_Oring_APS_Temp_254_Initial" 255 "DCDC_Oring_APS_Temp_255_Invalid";
VAL_ 787 DCDC_OutWtrTemp 255 "DCDC_OutWtrTemp_255_Invalid" 255 "DCDC_OutWtrTemp_255_Invalid";
VAL_ 787 DCDC_OverTemp 0 "DCDC_OverTemp_0_No_Error" 1 "DCDC_OverTemp_1_Error";
VAL_ 787 DCDC_PeakPwrTi 4095 "DCDC_PeakPwrTi_4095_Invalid";
VAL_ 787 DCDC_PNGSt 0 "DCDC_PNGSt_0_Open" 1 "DCDC_PNGSt_1_Close" 2 "DCDC_PNGSt_2_Reserved" 3 "DCDC_PNGSt_3_Reserved";
VAL_ 790 OBC_ACInpFrq 127 "OBC_ACInpFrq_127_Invalid";
VAL_ 790 OBC_AcIptSts 0 "OBC_AcIptSts_0_AC_power_is_normal" 1 "OBC_AcIptSts_1_No_electricity_or_Undervoltage" 2 "OBC_AcIptSts_2_Ac_power_is_blackout" 3 "OBC_AcIptSts_3_Overvoltage";
VAL_ 790 OBC_AcIptType 0 "OBC_AcIptType_0_One_Phase" 1 "OBC_AcIptType_1_Three_Phase";
VAL_ 790 OBC_ChrgGunCCSts 0 "OBC_ChrgGunCCSts_0_Invalid_CC_Res" 1 "OBC_ChrgGunCCSts_1_Not_Connected" 2 "OBC_ChrgGunCCSts_2_Half_Connected" 3 "OBC_ChrgGunCCSts_3_ACChrg_Full_Connected" 4 "OBC_ChrgGunCCSts_4_V2L_Cun_Full_Connected" 5 "OBC_ChrgGunCCSts_5_V2V_Gun_Full_Connected" 6 "OBC_ChrgGunCCSts_6_Unknown(Full_Connected)" 7 "OBC_ChrgGunCCSts_7_Reserved";
VAL_ 790 OBC_CopntTemp 255 "OBC_CopntTemp_255_Invalid";
VAL_ 790 OBC_CPDuty 1023 "OBC_CPDuty_1023_Invalid";
VAL_ 790 OBC_CPFreqSts 0 "OBC_CPFreqSts_0_CP_is_within_500Hz_to1500Hz" 1 "OBC_CPFreqSts_1_CP_is_beyond_500Hz_to_1500Hz";
VAL_ 790 OBC_CPFrq 4095 "OBC_CPFrq_4095_Invalid";
VAL_ 790 OBC_CPOutpDuty 1023 "OBC_CPOutpDuty_1023_Invalid";
VAL_ 790 OBC_CPOutpVolt 127 "OBC_CPOutpVolt_127_Invalid";
VAL_ 790 OBC_CPSts 0 "OBC_CPSts_0_no_CP_signal" 1 "OBC_CPSts_1_CP_is_12V_high_level" 2 "OBC_CPSts_2_CP_is_9V_high_level" 3 "OBC_CPSts_3_CP_is_9V_PWM" 4 "OBC_CPSts_4_CP_is_6V_PWM" 5 "OBC_CPSts_5_CP_is_6V_high_level" 6 "OBC_CPSts_6_CP_is_12V_PWM" 7 "OBC_CPSts_7_CP_signal_is_abnormal";
VAL_ 790 OBC_CPValidSt 0 "OBC_CPValidSt_0_Not_Connected" 1 "OBC_CPValidSt_1_Valid" 2 "OBC_CPValidSt_2_Invalid" 3 "OBC_CPValidSt_3_Reserved";
VAL_ 790 OBC_CPVolt 127 "OBC_CPVolt_127_Invalid";
VAL_ 790 OBC_DeratFlag 0 "OBC_DeratFlag_0_Nomal_Working" 1 "OBC_DeratFlag_1_Derating_Working";
VAL_ 790 OBC_DeratReason1 0 "OBC_DeratReason1_0_Normal" 1 "OBC_DeratReason1_1_Abnormal";
VAL_ 790 OBC_DeratReason10 0 "OBC_DeratReason10_0_Normal" 1 "OBC_DeratReason10_1_Abnormal";
VAL_ 790 OBC_DeratReason11 0 "OBC_DeratReason11_0_Normal" 1 "OBC_DeratReason11_1_Abnormal";
VAL_ 790 OBC_DeratReason12 0 "OBC_DeratReason12_0_Normal" 1 "OBC_DeratReason12_1_Abnormal";
VAL_ 790 OBC_DeratReason13 0 "OBC_DeratReason13_0_Normal" 1 "OBC_DeratReason13_1_Abnormal";
VAL_ 790 OBC_DeratReason14 0 "OBC_DeratReason14_0_Normal" 1 "OBC_DeratReason14_1_Abnormal";
VAL_ 790 OBC_DeratReason15 0 "OBC_DeratReason15_0_Normal" 1 "OBC_DeratReason15_1_Abnormal";
VAL_ 790 OBC_DeratReason16 0 "OBC_DeratReason16_0_Normal" 1 "OBC_DeratReason16_1_Abnormal";
VAL_ 790 OBC_DeratReason17 0 "OBC_DeratReason17_0_Normal" 1 "OBC_DeratReason17_1_Abnormal";
VAL_ 790 OBC_DeratReason18 0 "OBC_DeratReason18_0_Normal" 1 "OBC_DeratReason18_1_Abnormal";
VAL_ 790 OBC_DeratReason19 0 "OBC_DeratReason19_0_Normal" 1 "OBC_DeratReason19_1_Abnormal";
VAL_ 790 OBC_DeratReason2 0 "OBC_DeratReason2_0_Normal" 1 "OBC_DeratReason2_1_Abnormal";
VAL_ 790 OBC_DeratReason20 0 "OBC_DeratReason20_0_Normal" 1 "OBC_DeratReason20_1_Abnormal";
VAL_ 790 OBC_DeratReason21 0 "OBC_DeratReason21_0_Normal" 1 "OBC_DeratReason21_1_Abnormal";
VAL_ 790 OBC_DeratReason22 0 "OBC_DeratReason22_0_Normal" 1 "OBC_DeratReason22_1_Abnormal";
VAL_ 790 OBC_DeratReason23 0 "OBC_DeratReason23_0_Normal" 1 "OBC_DeratReason23_1_Abnormal";
VAL_ 790 OBC_DeratReason24 0 "OBC_DeratReason24_0_Normal" 1 "OBC_DeratReason24_1_Abnormal";
VAL_ 790 OBC_DeratReason3 0 "OBC_DeratReason3_0_Normal" 1 "OBC_DeratReason3_1_Abnormal";
VAL_ 790 OBC_DeratReason4 0 "OBC_DeratReason4_0_Normal" 1 "OBC_DeratReason4_1_Abnormal";
VAL_ 790 OBC_DeratReason5 0 "OBC_DeratReason5_0_Normal" 1 "OBC_DeratReason5_1_Abnormal";
VAL_ 790 OBC_DeratReason6 0 "OBC_DeratReason6_0_Normal" 1 "OBC_DeratReason6_1_Abnormal";
VAL_ 790 OBC_DeratReason7 0 "OBC_DeratReason7_0_Normal" 1 "OBC_DeratReason7_1_Abnormal";
VAL_ 790 OBC_DeratReason8 0 "OBC_DeratReason8_0_Normal" 1 "OBC_DeratReason8_1_Abnormal";
VAL_ 790 OBC_DeratReason9 0 "OBC_DeratReason9_0_Normal" 1 "OBC_DeratReason9_1_Abnormal";
VAL_ 790 OBC_DischrgLoadForm 0 "OBC_DischrgLoadForm_0_Unknown" 1 "OBC_DischrgLoadForm_1_Non-intelligent_load" 2 "OBC_DischrgLoadForm_2_Intelligent_loads" 3 "OBC_DischrgLoadForm_3_Reserved";
VAL_ 790 OBC_DisWorkMode 0 "OBC_DisWorkMode_0_No_mode" 1 "OBC_DisWorkMode_1_DCACMode" 2 "OBC_DisWorkMode_2_Reserved";
VAL_ 790 OBC_EnergyConvrtDir 0 "OBC_EnergyConvrtDir_0_Uni_Direction" 1 "OBC_EnergyConvrtDir_1_Bi_Direction";
VAL_ 790 OBC_FastChargeRelayNegSts 0 "OBC_FastChargeRelayNegSts_0_OPEN" 1 "OBC_FastChargeRelayNegSts_1_CLOSE" 2 "OBC_FastChargeRelayNegSts_2_FAULT" 3 "OBC_FastChargeRelayNegSts_3_Reserved";
VAL_ 790 OBC_FastChargeRelayPosSts 0 "OBC_FastChargeRelayPosSts_0_OPEN" 1 "OBC_FastChargeRelayPosSts_1_CLOSE" 2 "OBC_FastChargeRelayPosSts_2_FAULT" 3 "OBC_FastChargeRelayPosSts_3_Reserved";
VAL_ 790 OBC_FaultLevel 0 "OBC_FaultLevel_0_Normal" 1 "OBC_FaultLevel_1_Level1" 2 "OBC_FaultLevel_2_Level2" 3 "OBC_FaultLevel_3_Level3" 4 "OBC_FaultLevel_4_Level4" 5 "OBC_FaultLevel_5_Level5" 6 "OBC_FaultLevel_6_Level6_EVR" 7 "OBC_FaultLevel_7_Reseverd";
VAL_ 790 OBC_FaultLightReq 0 "OBC_FaultLightReq_0_No_Request" 1 "OBC_FaultLightReq_1_Request";
VAL_ 790 OBC_HVIL_AC_St 0 "OBC_HVIL_AC_St_0_Not_ready" 1 "OBC_HVIL_AC_St_1_Lock" 2 "OBC_HVIL_AC_St_2_Unlock" 3 "OBC_HVIL_AC_St_3_HW_Fault";
VAL_ 790 OBC_HVIL_DC_St 0 "OBC_HVIL_DC_St_0_Not_ready" 1 "OBC_HVIL_DC_St_1_Lock" 2 "OBC_HVIL_DC_St_2_Unlock" 3 "OBC_HVIL_DC_St_3_HW_Fault";
VAL_ 790 OBC_OperSt 0 "OBC_OperSt_0_Initial" 1 "OBC_OperSt_1_Standby" 2 "OBC_OperSt_2_AC_Charge" 3 "OBC_OperSt_3_Bat_Heat" 4 "OBC_OperSt_4_AC_Discharge" 5 "OBC_OperSt_5_Fault" 6 "OBC_OperSt_6_Safety" 7 "OBC_OperSt_7_PreSleep" 8 "OBC_OperSt_8_Reserved";
VAL_ 790 OBC_RatedPwrLevel 0 "OBC_RatedPwrLevel_0_9.9kW" 1 "OBC_RatedPwrLevel_1_reserved" 2 "OBC_RatedPwrLevel_2_3.3kW" 3 "OBC_RatedPwrLevel_3_6.6kW" 4 "OBC_RatedPwrLevel_4_reserved";
VAL_ 790 OBC_S1Sts 0 "OBC_S1Sts_0_12V_Output" 1 "OBC_S1Sts_1_PWM_Output";
VAL_ 790 OBC_S2Sts 0 "OBC_S2Sts_0_Open" 1 "OBC_S2Sts_1_Close";
VAL_ 790 OBC_S4Sts 0 "OBC_S4Sts_0_Detection_status" 1 "OBC_S4Sts_1_Output_status";
VAL_ 790 OBC_WorkMode 0 "OBC_WorkMode_0_No_mode" 1 "OBC_WorkMode_1_DcChargeMode" 2 "OBC_WorkMode_2_AcChargeMode" 3 "OBC_WorkMode_3_BatteryWarm" 4 "OBC_WorkMode_4_InverterMode" 5 "OBC_WorkMode_5_Reserved";
VAL_ 794 CDU_KL15_Volt 254 "CDU_KL15_Volt_254_Initial" 255 "CDU_KL15_Volt_255_Invalid";
VAL_ 794 CDU_KL30_Volt 254 "CDU_KL30_Volt_254_Initial" 255 "CDU_KL30_Volt_255_Invalid";
VAL_ 794 OBC_ACL1Currt 1023 "OBC_ACL1Currt_1023_Invalid";
VAL_ 794 OBC_ACL1Volt 4095 "OBC_ACL1Volt_4095_Invalid";
VAL_ 794 OBC_ACL2Currt 1022 "OBC_ACL2Currt_1022_Initial" 1023 "OBC_ACL2Currt_1023_Invalid";
VAL_ 794 OBC_ACL2Volt 4094 "OBC_ACL2Volt_4094_Initial" 4095 "OBC_ACL2Volt_4095_Invalid";
VAL_ 794 OBC_ACL3Currt 1022 "OBC_ACL3Currt_1022_Initial" 1023 "OBC_ACL3Currt_1023_Invalid";
VAL_ 794 OBC_ACL3Volt 4094 "OBC_ACL3Volt_4094_Initial" 4095 "OBC_ACL3Volt_4095_Invalid";
VAL_ 794 OBC_ACPileMaxCurrt 255 "OBC_ACPileMaxCurrt_255_Invalid";
VAL_ 794 OBC_ACPwr 2047 "OBC_ACPwr_2047_Invalid";
VAL_ 794 OBC_ChrgCablePermitCurrt 0 "OBC_ChrgCablePermitCurrt_0_Unknown" 1 "OBC_ChrgCablePermitCurrt_1_10A" 2 "OBC_ChrgCablePermitCurrt_2_16A" 3 "OBC_ChrgCablePermitCurrt_3_32A" 4 "OBC_ChrgCablePermitCurrt_4_63A" 5 "OBC_ChrgCablePermitCurrt_5_Reserved";
VAL_ 794 OBC_ChrgOptMaxCurrt 1023 "OBC_ChrgOptMaxCurrt_1023_Invalid";
VAL_ 794 OBC_ChrgOptMaxPwr 2047 "OBC_ChrgOptMaxPwr_2047_Invalid";
VAL_ 794 OBC_ChrgOptMaxVolt 1023 "OBC_ChrgOptMaxVolt_1023_Invalid";
VAL_ 794 OBC_ChrgOptMinVolt 1023 "OBC_ChrgOptMinVolt_1023_Invalid";
VAL_ 794 OBC_DCChrgMod_LimCurrt 511 "OBC_DCChrgMod_LimCurrt_511_Invalid";
VAL_ 794 OBC_DCCurrt 2047 "OBC_DCCurrt_2047_Invalid";
VAL_ 794 OBC_DCVolt 4095 "OBC_DCVolt_4095_Invalid";
VAL_ 794 OBC_DischrgOptMaxPwr 1023 "OBC_DischrgOptMaxPwr_1023_Invalid";
VAL_ 291 EMS_CalculatedLoadRat 255 "EMS_CalculatedLoadRat_255_无效值";
VAL_ 291 EMS_CatHeatingReq 0 "EMS_CatHeatingReq_0_No_Request" 1 "EMS_CatHeatingReq_1_Request";
VAL_ 291 EMS_DewPointEndSt 0 "EMS_DewPointEndSt_0_Dew_Point_Not_End" 1 "EMS_DewPointEndSt_1_Dew_Point_End";
VAL_ 291 EMS_DrvgCyc 0 "EMS_DrvgCyc_0_NOT_ACHIEVED" 1 "EMS_DrvgCyc_1_ACHIEVED";
VAL_ 291 EMS_EngIdleCtrlSts 0 "EMS_EngIdleCtrlSts_0_Not_in_Idle_Status" 1 "EMS_EngIdleCtrlSts_1_in_Idle_Status";
VAL_ 291 EMS_EngKonckSt 0 "EMS_EngKonckSt_0_No_Engine_Knock" 1 "EMS_EngKonckSt_1_Engine_Knocking";
VAL_ 291 EMS_EngStartInhb 0 "EMS_EngStartInhb_0_No_Inhibit" 1 "EMS_EngStartInhb_1_Stop_Inhibit";
VAL_ 291 EMS_EngStartReq 0 "EMS_EngStartReq_0_No_Start_Request" 1 "EMS_EngStartReq_1_Start_Request" 2 "EMS_EngStartReq_2_Reserved" 3 "EMS_EngStartReq_3_Invalid";
VAL_ 291 EMS_EngStartSuccess 0 "EMS_EngStartSuccess_0_Start_Not_Success" 1 "EMS_EngStartSuccess_1_Start_Success";
VAL_ 291 EMS_EngStopInhb 0 "EMS_EngStopInhb_0_No_Inhibit" 1 "EMS_EngStopInhb_1_Stop_Inhibit";
VAL_ 291 EMS_FuelSigFlt 0 "EMS_FuelSigFlt_0_Normal" 1 "EMS_FuelSigFlt_1_油位信号输入电路对电源短路（主副箱任何一路发生对电源短路）" 2 "EMS_FuelSigFlt_2_油位信号输入电路对地短路（主副箱任何一路发生对地短路）" 3 "EMS_FuelSigFlt_3_油位信号输入电路开路（主副箱任何一路发生开路）" 4 "EMS_FuelSigFlt_4_Reserved" 7 "EMS_FuelSigFlt_7_Invalid";
VAL_ 291 EMS_IgnAngIntvSt 0 "EMS_IgnAngIntvSt_0_No_Intervention" 1 "EMS_IgnAngIntvSt_1_Intervening";
VAL_ 291 EMS_IgnCyc 0 "EMS_IgnCyc_0_NOT_ACHIEVED" 1 "EMS_IgnCyc_1_ACHIEVED";
VAL_ 291 EMS_LimpHomeSt 0 "EMS_LimpHomeSt_0_Normal" 1 "EMS_LimpHomeSt_1_Limp_home";
VAL_ 291 EMS_OilPWarnLamp 0 "EMS_OilPWarnLamp_0_Initial" 1 "EMS_OilPWarnLamp_1_No_Warning" 2 "EMS_OilPWarnLamp_2_Warning" 3 "EMS_OilPWarnLamp_3_Invalid";
VAL_ 291 EMS_OilPWarnSt 0 "EMS_OilPWarnSt_0_No_Warn" 1 "EMS_OilPWarnSt_1_High_Pressure" 2 "EMS_OilPWarnSt_2_Low_Pressure" 3 "EMS_OilPWarnSt_3_Fault";
VAL_ 291 EMS_OilSnsrResistorVal 510 "EMS_OilSnsrResistorVal_510_Initial" 511 "EMS_OilSnsrResistorVal_511_Invalid";
VAL_ 291 EMS_OperSt 0 "EMS_OperSt_0_Key_Off" 1 "EMS_OperSt_1_Initial" 2 "EMS_OperSt_2_Stop" 3 "EMS_OperSt_3_Cranking" 4 "EMS_OperSt_4_Running" 5 "EMS_OperSt_5_Stopping" 6 "EMS_OperSt_6_Reserved" 7 "EMS_OperSt_7_Fault";
VAL_ 291 EMS_PvdVld 0 "EMS_PvdVld_0_Invalid" 1 "EMS_PvdVld_1_Valid";
VAL_ 291 EMS_TqCtrlInhbSt 0 "EMS_TqCtrlInhbSt_0_Torque_Control_Allowed" 1 "EMS_TqCtrlInhbSt_1_Torque_Control_Inhibit";
VAL_ 291 EMS_WarmupCyc 0 "EMS_WarmupCyc_0_NOT_ACHIEVED" 1 "EMS_WarmupCyc_1_ACHIEVED";
VAL_ 291 EMS_WorkpointReq 0 "EMS_WorkpointReq_0_无EMS工况协调需求" 1 "EMS_WorkpointReq_1_有EMS工况协调需求";
VAL_ 386 EMS_AfterRunReq 0 "EMS_AfterRunReq_0_No_request" 1 "EMS_AfterRunReq_1_Request";
VAL_ 386 EMS_AmbAirPVld 0 "EMS_AmbAirPVld_0_Invalid" 1 "EMS_AmbAirPVld_1_Valid";
VAL_ 386 EMS_CatTempVld 0 "EMS_CatTempVld_0_Invalid" 1 "EMS_CatTempVld_1_Valid";
VAL_ 386 EMS_EngCoolantTempVld 0 "EMS_EngCoolantTempVld_0_Invalid" 1 "EMS_EngCoolantTempVld_1_Valid";
VAL_ 386 EMS_EngFuelCutOffSt 0 "EMS_EngFuelCutOffSt_0_Not_in_Fuel_Cut" 1 "EMS_EngFuelCutOffSt_1_in_Fuel_Cut";
VAL_ 386 EMS_EngFuleCutOffAlldSt 0 "EMS_EngFuleCutOffAlldSt_0_Disable(Not_Permit_Cut_Fuel)" 1 "EMS_EngFuleCutOffAlldSt_1_Enable(Permit_Cut_Fuel)";
VAL_ 386 EMS_EngOverSpdFlg 0 "EMS_EngOverSpdFlg_0_No_over_Speed" 1 "EMS_EngOverSpdFlg_1_over_Speed";
VAL_ 386 EMS_EngSpdSnsrFltSt 0 "EMS_EngSpdSnsrFltSt_0_No_Error" 1 "EMS_EngSpdSnsrFltSt_1_Error";
VAL_ 386 EMS_EngThrPosnFlt 0 "EMS_EngThrPosnFlt_0_Normal" 1 "EMS_EngThrPosnFlt_1_Fault";
VAL_ 386 EMS_FitvFlt 0 "EMS_FitvFlt_0_No_Fault" 1 "EMS_FitvFlt_1_Can_not_open" 2 "EMS_FitvFlt_2_Can_not_close" 3 "EMS_FitvFlt_3_Reserved";
VAL_ 386 EMS_FitvSt 0 "EMS_FitvSt_0_Closed" 1 "EMS_FitvSt_1_Open" 2 "EMS_FitvSt_2_Error" 3 "EMS_FitvSt_3_None";
VAL_ 386 EMS_FltLvl 0 "EMS_FltLvl_0_No_Fault" 1 "EMS_FltLvl_1_Slight_Error" 2 "EMS_FltLvl_2_Restart_Problem" 3 "EMS_FltLvl_3_Torque_Limited" 4 "EMS_FltLvl_4_Idle_Limp_Home" 5 "EMS_FltLvl_5_Need_Shut_Down" 6 "EMS_FltLvl_6_Reserved" 7 "EMS_FltLvl_7_Invalid";
VAL_ 386 EMS_FuelAddingAlldSt 0 "EMS_FuelAddingAlldSt_0_Not_Allow_INC" 1 "EMS_FuelAddingAlldSt_1_Allow_INC_允许加油" 2 "EMS_FuelAddingAlldSt_2_None" 3 "EMS_FuelAddingAlldSt_3_Error";
VAL_ 386 EMS_FuelCutOffDiagSt 0 "EMS_FuelCutOffDiagSt_0_Off" 1 "EMS_FuelCutOffDiagSt_1_Ready" 2 "EMS_FuelCutOffDiagSt_2_Testting" 3 "EMS_FuelCutOffDiagSt_3_Finish";
VAL_ 386 EMS_FuelInjectedVld 0 "EMS_FuelInjectedVld_0_Invalid" 1 "EMS_FuelInjectedVld_1_Valid";
VAL_ 386 EMS_FuelTankP 1023 "EMS_FuelTankP_1023_Invalid";
VAL_ 386 EMS_FuelTankPRlsSt 0 "EMS_FuelTankPRlsSt_0_No_Release" 1 "EMS_FuelTankPRlsSt_1_Released";
VAL_ 386 EMS_IntkMnfldPVld 0 "EMS_IntkMnfldPVld_0_Invalid" 1 "EMS_IntkMnfldPVld_1_Valid";
VAL_ 386 EMS_MilIndicator 0 "EMS_MilIndicator_0_OFF" 1 "EMS_MilIndicator_1_ON" 2 "EMS_MilIndicator_2_ERROR" 3 "EMS_MilIndicator_3_None";
VAL_ 386 EMS_RadiatorOutWaterTempVld 0 "EMS_RadiatorOutWaterTempVld_0_Invalid" 1 "EMS_RadiatorOutWaterTempVld_1_Valid";
VAL_ 386 EMS_ThrFwdEngIntkAirTempVld 0 "EMS_ThrFwdEngIntkAirTempVld_0_Invalid" 1 "EMS_ThrFwdEngIntkAirTempVld_1_Valid";
VAL_ 386 EMS_TWVE_ActPerc 126 "EMS_TWVE_ActPerc_126_Initial_Value" 127 "EMS_TWVE_ActPerc_127_Invalid";
VAL_ 386 EMS_TWVE_TrgtPerc 126 "EMS_TWVE_TrgtPerc_126_Initial_Value" 127 "EMS_TWVE_TrgtPerc_127_Invalid";
VAL_ 386 EMS_WarmupAch 0 "EMS_WarmupAch_0_Not_Achieved" 1 "EMS_WarmupAch_1_Achieved";
VAL_ 386 EMS_WaterPumpSt 0 "EMS_WaterPumpSt_0_Normal" 1 "EMS_WaterPumpSt_1_Fault";
VAL_ 290 EMS_EngActSpdVld 0 "EMS_EngActSpdVld_0_Invalid" 1 "EMS_EngActSpdVld_1_Valid";
VAL_ 290 EMS_EngFricTqVld 0 "EMS_EngFricTqVld_0_Invalid" 1 "EMS_EngFricTqVld_1_Valid";
VAL_ 290 EMS_FlyWhlActTqVld 0 "EMS_FlyWhlActTqVld_0_Invalid" 1 "EMS_FlyWhlActTqVld_1_Valid";
VAL_ 290 EMS_FlyWhlTqCrsLeadMaxVld 0 "EMS_FlyWhlTqCrsLeadMaxVld_0_Invalid" 1 "EMS_FlyWhlTqCrsLeadMaxVld_1_Valid";
VAL_ 290 EMS_FlyWhlTqCrsLeadMinVld 0 "EMS_FlyWhlTqCrsLeadMinVld_0_Invalid" 1 "EMS_FlyWhlTqCrsLeadMinVld_1_Valid";
VAL_ 290 EMS_FlyWhlTqCrsSetMaxVld 0 "EMS_FlyWhlTqCrsSetMaxVld_0_Invalid" 1 "EMS_FlyWhlTqCrsSetMaxVld_1_Valid";
VAL_ 290 EMS_FlyWhlTqCrsSetMinVld 0 "EMS_FlyWhlTqCrsSetMinVld_0_Invalid" 1 "EMS_FlyWhlTqCrsSetMinVld_1_Valid";
VAL_ 290 EMS_FlyWhlTqMinWoCutoffVld 0 "EMS_FlyWhlTqMinWoCutoffVld_0_Invalid" 1 "EMS_FlyWhlTqMinWoCutoffVld_1_Valid";
VAL_ 290 EMS_IdleSpdRefVld 0 "EMS_IdleSpdRefVld_0_Invalid" 1 "EMS_IdleSpdRefVld_1_Valid";
VAL_ 290 EMS_SpdSyncSt 0 "EMS_SpdSyncSt_0_Not_Sync" 1 "EMS_SpdSyncSt_1_Sync";
VAL_ 909 ESSPTC_HVIL_Sta 0 "ESSPTC_HVIL_Sta_0_ESSPTC_HVIL_Sta_0_Initial" 1 "ESSPTC_HVIL_Sta_1_ESSPTC_HVIL_Sta_1_Normal" 2 "ESSPTC_HVIL_Sta_2_ESSPTC_HVIL_Sta_2_Fault" 3 "ESSPTC_HVIL_Sta_3_ESSPTC_HVIL_Sta_3_Short_Circuit";
VAL_ 909 ESSPTCFltLvl 0 "ESSPTCFltLvl_0_PTCFltLvl_0_LEVEL0" 1 "ESSPTCFltLvl_0_PTCFltLvl_1_LEVEL1" 2 "ESSPTCFltLvl_0_PTCFltLvl_2_LEVEL2" 3 "ESSPTCFltLvl_0_PTCFltLvl_3_LEVEL3";
VAL_ 909 ESSPTCIGBTOverHeat 0 "ESSPTCIGBTOverHeat_0_PTCIGBTOverHeat_0_IgbtGood" 1 "ESSPTCIGBTOverHeat_1_PTCIGBTOverHeat_1_OverHeat";
VAL_ 909 ESSPTCIGBTSts 0 "ESSPTCIGBTSts_0_PTCIGBTSts_0_Normal" 1 "ESSPTCIGBTSts_0_PTCIGBTSts_1_PTCIGBTSts_1_Fault";
VAL_ 909 ESSPTCNTCSts 0 "ESSPTCNTCSts_0_PTCNTCSts_0_AllSensorIsGood" 1 "ESSPTCNTCSts_1_PTCNTCSts_1_IgbtSensorBad_PtcInSensorGood_PtcOutSensorGood" 2 "ESSPTCNTCSts_2_PTCNTCSts_2_IgbtSensorGood_PtcInSensorBad_Ptc_out_sensorGood" 3 "ESSPTCNTCSts_3_PTCNTCSts_3_IgbtSensorBad_PtcInSensorBad_Ptc_out_sensorGood" 4 "ESSPTCNTCSts_4_PTCNTCSts_4_IgbtSensorGood_PtcInSensorGood_PtcOutSensorBad" 5 "ESSPTCNTCSts_5_PTCNTCSts_5_IgbtSensorBad_PtcInSensorGood_PtcOutSensorBad" 6 "ESSPTCNTCSts_6_PTCNTCSts_6_IgbtSensorGood_PtcInSensorBad_PtcOutSensorBad" 7 "ESSPTCNTCSts_7_PTCNTCSts_7_AllSensorBad";
VAL_ 909 ESSPTCOverCrnt 0 "ESSPTCOverCrnt_0_PTCOverCrnt_0_Inactived" 1 "ESSPTCOverCrnt_1_PTCOverCrnt_1_Actived";
VAL_ 909 ESSPTCOverHeat 0 "ESSPTCOverHeat_0_PTCOverHeat_0_Inactived" 1 "ESSPTCOverHeat_1_PTCOverHeat_1_Actived";
VAL_ 909 ESSPTCOverVol 0 "ESSPTCOverVol_0_PTCOverVol_0_Inactived" 1 "ESSPTCOverVol_1_PTCOverVol_1_Actived";
VAL_ 909 ESSPTCSts 0 "ESSPTCSts_0_PTCSts_0_NotWorking0x1" 1 "ESSPTCSts_1_PTCSts_1_Working" 2 "ESSPTCSts_2_PTCSts_2_EmergencyStop" 3 "ESSPTCSts_3_PTCSts_3_PrepareToStart";
VAL_ 909 ESSPTCUnderVol 0 "ESSPTCUnderVol_0_PTCUnderVol_0_Inactived" 1 "ESSPTCUnderVol_1_PTCUnderVol_1_Actived";
VAL_ 294 GCU_ActEff 254 "GCU_ActEff_254_Initial" 255 "GCU_ActEff_255_Invalid";
VAL_ 294 GCU_ActMaxVolt 8190 "GCU_ActMaxVolt_8190_Initial" 8191 "GCU_ActMaxVolt_8191_Invalid";
VAL_ 294 GCU_ActMinVolt 8190 "GCU_ActMinVolt_8190_Initial" 8191 "GCU_ActMinVolt_8191_Invalid";
VAL_ 294 GCU_CurrtPhaA 65535 "GCU_CurrtPhaA_65535_Invalid";
VAL_ 294 GCU_CurrtPhaB 65535 "GCU_CurrtPhaB_65535_Invalid";
VAL_ 294 GCU_CurrtPhaC 65535 "GCU_CurrtPhaC_65535_Invalid";
VAL_ 294 GCU_DCCurrt 65535 "GCU_DCCurrt_65535_Invalid";
VAL_ 294 GCU_DchaSt 0 "GCU_DchaSt_0_未放电" 1 "GCU_DchaSt_1_放电中" 2 "GCU_DchaSt_2_放电完成" 3 "GCU_DchaSt_3_放电失败";
VAL_ 294 GCU_DCVolt 65535 "GCU_DCVolt_65535_Invalid";
VAL_ 294 GCU_FltLvl 0 "GCU_FltLvl_0_Normal" 1 "GCU_FltLvl_1_Level_1" 2 "GCU_FltLvl_2_Level_2" 3 "GCU_FltLvl_3_Level_3" 4 "GCU_FltLvl_4_Level_4" 5 "GCU_FltLvl_5_Level_5" 6 "GCU_FltLvl_6_Reserved" 7 "GCU_FltLvl_7_Reserved";
VAL_ 294 GCU_HVIL_St 0 "GCU_HVIL_St_0_Not_ready" 1 "GCU_HVIL_St_1_Lock" 2 "GCU_HVIL_St_2_Unlock" 3 "GCU_HVIL_St_3_HW_Fault";
VAL_ 294 GCU_IGBTMod 0 "GCU_IGBTMod_0_PWM_Off" 1 "GCU_IGBTMod_1_PWM_On" 2 "GCU_IGBTMod_2_ASC" 3 "GCU_IGBTMod_3_Invalid";
VAL_ 294 GCU_MILReq 0 "GCU_MILReq_0_No_Request" 1 "GCU_MILReq_1_Request";
VAL_ 294 GCU_MotWorkSt 0 "GCU_MotWorkSt_0_初始化" 1 "GCU_MotWorkSt_1_耗电" 2 "GCU_MotWorkSt_2_发电" 3 "GCU_MotWorkSt_3_关管" 4 "GCU_MotWorkSt_4_准备" 5 "GCU_MotWorkSt_5_异常" 15 "GCU_MotWorkSt_15_无效";
VAL_ 294 GCU_OBDFaultExistSts 0 "GCU_OBDFaultExistSts_0_No_OBD_Fault" 1 "GCU_OBDFaultExistSts_1_OBD_Fault";
VAL_ 294 GCU_OperMod 0 "GCU_OperMod_0_Initial初始化" 1 "GCU_OperMod_1_LVStandby低压待机" 2 "GCU_OperMod_2_HVStandby高压待机" 3 "GCU_OperMod_3_TorqueMode转矩模式" 4 "GCU_OperMod_4_SpeedMode转速模式" 5 "GCU_OperMod_5_ElectricResolverSelf-calibration旋变自标定" 6 "GCU_OperMod_6_Fault故障态" 7 "GCU_OperMod_7_PowerOff下电态" 8 "GCU_OperMod_8_DisCharging主动放电态" 9 "GCU_OperMod_9_VoltageClosedLoop电压闭环" 10 "GCU_OperMod_10_Reserved";
VAL_ 294 GCU_ResolverFltTyp 0 "GCU_ResolverFltTyp_0_无故障" 1 "GCU_ResolverFltTyp_1_EXC频率故障" 2 "GCU_ResolverFltTyp_2_EXC占空比故障" 3 "GCU_ResolverFltTyp_3_SIN单端+超范围" 4 "GCU_ResolverFltTyp_4_SIN单端-超范围" 5 "GCU_ResolverFltTyp_5_COS单端+超范围" 6 "GCU_ResolverFltTyp_6_COS单端-超范围" 7 "GCU_ResolverFltTyp_7_LEVEL12SIN采样信号差" 8 "GCU_ResolverFltTyp_8_LEVEL12COS采样信号差" 9 "GCU_ResolverFltTyp_9_LEVEL1/2的角度差值" 10 "GCU_ResolverFltTyp_10_SIN^2+COS^2波动量" 11 "GCU_ResolverFltTyp_11_SIN^2+COS^2!" 12 "GCU_ResolverFltTyp_12_旋变sin信号超范围" 13 "GCU_ResolverFltTyp_13_旋变cos信号超范围" 14 "GCU_ResolverFltTyp_14_Reserved";
VAL_ 799 GCU_FlowReq 255 "GCU_FlowReq_255_Invalid";
VAL_ 799 GCU_IGBTTempA 255 "GCU_IGBTTempA_255_Invalid";
VAL_ 799 GCU_IGBTTempA_Chip 255 "GCU_IGBTTempA_Chip_255_Invalid";
VAL_ 799 GCU_IGBTTempB 255 "GCU_IGBTTempB_255_Invalid";
VAL_ 799 GCU_IGBTTempB_Chip 255 "GCU_IGBTTempB_Chip_255_Invalid";
VAL_ 799 GCU_IGBTTempC 255 "GCU_IGBTTempC_255_Invalid";
VAL_ 799 GCU_IGBTTempC_Chip 255 "GCU_IGBTTempC_Chip_255_Invalid";
VAL_ 799 GCU_KL15OnSt 0 "GCU_KL15OnSt_0_Initial初始化" 1 "GCU_KL15OnSt_1_KL15_OFF" 2 "GCU_KL15OnSt_2_KL15_ON" 3 "GCU_KL15OnSt_3_Invalid";
VAL_ 799 GCU_KL15Volt 254 "GCU_KL15Volt_254_Initial" 255 "GCU_KL15Volt_255_Invalid";
VAL_ 799 GCU_KL30Volt 254 "GCU_KL30Volt_254_Initial" 255 "GCU_KL30Volt_255_Invalid";
VAL_ 799 GCU_PCBTemp 255 "GCU_PCBTemp_255_Invalid";
VAL_ 799 GCU_RotorTemp 255 "GCU_RotorTemp_255_Invalid";
VAL_ 799 GCU_TempWinding 255 "GCU_TempWinding_255_Invalid";
VAL_ 855 GCU_EOP_AIRmix_Fault 0 "GCU_EOP_AIRmix_Fault_0_此故障未发生" 1 "GCU_EOP_AIRmix_Fault_1_进入此故障状态";
VAL_ 855 GCU_EOP_Current 255 "GCU_EOP_Current_255_Invalid";
VAL_ 855 GCU_EOP_MOS_Temp 255 "GCU_EOP_MOS_Temp_255_Invalid";
VAL_ 855 GCU_EOP_Over_Current_Fault 0 "GCU_EOP_Over_Current_Fault_0_此故障未发生" 1 "GCU_EOP_Over_Current_Fault_1_进入此故障状态";
VAL_ 855 GCU_EOP_Over_Temp_Fault 0 "GCU_EOP_Over_Temp_Fault_0_此故障未发生" 1 "GCU_EOP_Over_Temp_Fault_1_进入此故障状态";
VAL_ 855 GCU_EOP_Over_Voltage_Fault 0 "GCU_EOP_Over_Voltage_Fault_0_此故障未发生" 1 "GCU_EOP_Over_Voltage_Fault_1_进入此故障状态";
VAL_ 855 GCU_EOP_Self_Check_Fault 0 "GCU_EOP_Self_Check_Fault_0_此故障未发生" 1 "GCU_EOP_Self_Check_Fault_1_进入此故障状态";
VAL_ 855 GCU_EOP_State 0 "GCU_EOP_State_0_油泵停止" 1 "GCU_EOP_State_1_油泵正常运行" 2 "GCU_EOP_State_2_油泵降额运行" 3 "GCU_EOP_State_3_油泵因故障停止";
VAL_ 855 GCU_EOP_Stuck_Fault 0 "GCU_EOP_Stuck_Fault_0_此故障未发生" 1 "GCU_EOP_Stuck_Fault_1_进入此故障状态";
VAL_ 855 GCU_EOP_Under_Voltage_Fault 0 "GCU_EOP_Under_Voltage_Fault_0_此故障未发生" 1 "GCU_EOP_Under_Voltage_Fault_1_进入此故障状态";
VAL_ 855 GCU_EOP_Voltage 255 "GCU_EOP_Voltage_255_Invalid";
VAL_ 855 GCU_HVCalSt 0 "GCU_HVCalSt_0_未校准" 1 "GCU_HVCalSt_1_校准中" 2 "GCU_HVCalSt_2_校准失败" 3 "GCU_HVCalSt_3_校准完成";
VAL_ 293 GCU_ActRotSpd 65535 "GCU_ActRotSpd_65535_Invalid";
VAL_ 293 GCU_ActTq 65535 "GCU_ActTq_65535_Invalid";
VAL_ 293 GCU_ActUnfilteredRotSpd 65535 "GCU_ActUnfilteredRotSpd_65535_Invalid";
VAL_ 293 GCU_CompensationTq 511 "GCU_CompensationTq_511_Invalid";
VAL_ 293 GCU_MaxOutputEleTq 65535 "GCU_MaxOutputEleTq_65535_Invalid";
VAL_ 293 GCU_MaxOutputGenTq 65535 "GCU_MaxOutputGenTq_65535_Invalid";
VAL_ 293 GCU_RotSpdMaxLimit 1023 "GCU_RotSpdMaxLimit_1023_Invalid";
VAL_ 279 IPB_SumOfEdgeFLWSS 65535 "IPB_SumOfEdgeFLWSS_65535_Invalid";
VAL_ 279 IPB_SumOfEdgeFLWSSValid 0 "IPB_SumOfEdgeFLWSSValid_0_Invalid" 1 "IPB_SumOfEdgeFLWSSValid_1_Valid";
VAL_ 279 IPB_SumOfEdgeFRWSS 65535 "IPB_SumOfEdgeFRWSS_65535_Invalid";
VAL_ 279 IPB_SumOfEdgeFRWSSValid 0 "IPB_SumOfEdgeFRWSSValid_0_Invalid" 1 "IPB_SumOfEdgeFRWSSValid_1_Valid";
VAL_ 279 IPB_SumOfEdgeRLWSS 65535 "IPB_SumOfEdgeRLWSS_65535_Invalid";
VAL_ 279 IPB_SumOfEdgeRLWSSValid 0 "IPB_SumOfEdgeRLWSSValid_0_Invalid" 1 "IPB_SumOfEdgeRLWSSValid_1_Valid";
VAL_ 279 IPB_SumOfEdgeRRWSS 65535 "IPB_SumOfEdgeRRWSS_65535_Invalid";
VAL_ 279 IPB_SumOfEdgeRRWSSValid 0 "IPB_SumOfEdgeRRWSSValid_0_Invalid" 1 "IPB_SumOfEdgeRRWSSValid_1_Valid";
VAL_ 279 IPB_VehicleSpeed 8191 "IPB_VehicleSpeed_8191_Invalid";
VAL_ 279 IPB_VehicleSpeedValid 0 "IPB_VehicleSpeedValid_0_Invalid" 1 "IPB_VehicleSpeedValid_1_Valid";
VAL_ 279 IPB_WheelDirectionFL 0 "IPB_WheelDirectionFL_0_Undefined" 1 "IPB_WheelDirectionFL_1_Forward" 2 "IPB_WheelDirectionFL_2_Backward" 3 "IPB_WheelDirectionFL_3_Stop";
VAL_ 279 IPB_WheelDirectionFLValid 0 "IPB_WheelDirectionFLValid_0_Invalid" 1 "IPB_WheelDirectionFLValid_1_Valid";
VAL_ 279 IPB_WheelDirectionFR 0 "IPB_WheelDirectionFR_0_Undefined" 1 "IPB_WheelDirectionFR_1_Forward" 2 "IPB_WheelDirectionFR_2_Backward" 3 "IPB_WheelDirectionFR_3_Stop";
VAL_ 279 IPB_WheelDirectionFRValid 0 "IPB_WheelDirectionFRValid_0_Invalid" 1 "IPB_WheelDirectionFRValid_1_Valid";
VAL_ 279 IPB_WheelDirectionRL 0 "IPB_WheelDirectionRL_0_Undefined" 1 "IPB_WheelDirectionRL_1_Forward" 2 "IPB_WheelDirectionRL_2_Backward" 3 "IPB_WheelDirectionRL_3_Stop";
VAL_ 279 IPB_WheelDirectionRLValid 0 "IPB_WheelDirectionRLValid_0_Invalid" 1 "IPB_WheelDirectionRLValid_1_Valid";
VAL_ 279 IPB_WheelDirectionRR 0 "IPB_WheelDirectionRR_0_Undefined" 1 "IPB_WheelDirectionRR_1_Forward" 2 "IPB_WheelDirectionRR_2_Backward" 3 "IPB_WheelDirectionRR_3_Stop";
VAL_ 279 IPB_WheelDirectionRRValid 0 "IPB_WheelDirectionRRValid_0_Invalid" 1 "IPB_WheelDirectionRRValid_1_Valid";
VAL_ 279 IPB_WheelSpeedFL 8191 "IPB_WheelSpeedFL_8191_Invalid";
VAL_ 279 IPB_WheelSpeedFLValid 0 "IPB_WheelSpeedFLValid_0_Invalid" 1 "IPB_WheelSpeedFLValid_1_Valid";
VAL_ 279 IPB_WheelSpeedFR 8191 "IPB_WheelSpeedFR_8191_Invalid";
VAL_ 279 IPB_WheelSpeedFRValid 0 "IPB_WheelSpeedFRValid_0_Invalid" 1 "IPB_WheelSpeedFRValid_1_Valid";
VAL_ 279 IPB_WheelSpeedRL 8191 "IPB_WheelSpeedRL_8191_Invalid";
VAL_ 279 IPB_WheelSpeedRLValid 0 "IPB_WheelSpeedRLValid_0_Invalid" 1 "IPB_WheelSpeedRLValid_1_Valid";
VAL_ 279 IPB_WheelSpeedRR 8191 "IPB_WheelSpeedRR_8191_Invalid";
VAL_ 279 IPB_WheelSpeedRRValid 0 "IPB_WheelSpeedRRValid_0_Invalid" 1 "IPB_WheelSpeedRRValid_1_Valid";
VAL_ 873 MCUR_AppPrefailResn 1 "MCUR_AppPrefailResn_1_3100CPLD_fault" 2 "MCUR_AppPrefailResn_2_UVWSum_fault" 4 "MCUR_AppPrefailResn_4_Icrt_fault";
VAL_ 873 MCUR_ToqDrtng 0 "MCUR_ToqDrtng_0_False" 1 "MCUR_ToqDrtng_1_True";
VAL_ 262 MCUR_ActRotSpd 65535 "MCUR_ActRotSpd_65535_Invalid";
VAL_ 262 MCUR_ActTq 65535 "MCUR_ActTq_65535_Invalid";
VAL_ 262 MCUR_ActUnfilteredRotSpd 65535 "MCUR_ActUnfilteredRotSpd_65535_Invalid";
VAL_ 262 MCUR_BlkSt 0 "MCUR_BlkSt_0_Not_Block" 1 "MCUR_BlkSt_1_Temporarily_Block" 2 "MCUR_BlkSt_2_Long_time_Block" 3 "MCUR_BlkSt_3_Reserved";
VAL_ 262 MCUR_CompensationTq 511 "MCUR_CompensationTq_511_Invalid";
VAL_ 262 MCUR_DCB_CapDchaSts 0 "MCUR_DCB_CapDchaSts_0_Not_Discharging" 1 "MCUR_DCB_CapDchaSts_1_Discharging" 2 "MCUR_DCB_CapDchaSts_2_Discharge_Finish" 3 "MCUR_DCB_CapDchaSts_3_Discharge_Fault";
VAL_ 262 MCUR_DCBoostChrgMaxOutpPwr 1023 "MCUR_DCBoostChrgMaxOutpPwr_1023_Invalid";
VAL_ 262 MCUR_DCBoostChrgOperSts 0 "MCUR_DCBoostChrgOperSts_0_不工作" 1 "MCUR_DCBoostChrgOperSts_1_降压预充" 2 "MCUR_DCBoostChrgOperSts_2_升压快充" 3 "MCUR_DCBoostChrgOperSts_3_限功率" 4 "MCUR_DCBoostChrgOperSts_4_故障" 5 "MCUR_DCBoostChrgOperSts_5_放电中" 6 "MCUR_DCBoostChrgOperSts_6_预留";
VAL_ 262 MCUR_DischargeState 0 "MCUR_DischargeState_0_Not_Discharged" 1 "MCUR_DischargeState_1_Discharging" 2 "MCUR_DischargeState_2_Discharge_Completed" 3 "MCUR_DischargeState_3_Discharge_Failure";
VAL_ 262 MCUR_FaultLevel 0 "MCUR_FaultLevel_0_Normal" 1 "MCUR_FaultLevel_1_Level_1" 2 "MCUR_FaultLevel_2_Level_2" 3 "MCUR_FaultLevel_3_Level_3" 4 "MCUR_FaultLevel_4_Level_4" 5 "MCUR_FaultLevel_5_Level_5" 6 "MCUR_FaultLevel_6_Reserved" 7 "MCUR_FaultLevel_7_Reserved";
VAL_ 262 MCUR_FlowReq 255 "MCUR_FlowReq_255_Invalid";
VAL_ 262 MCUR_FlusSt 1 "MCUR_FlusSt_1_Standby" 2 "MCUR_FlusSt_2_Prepare" 3 "MCUR_FlusSt_3_Run" 4 "MCUR_FlusSt_4_Fault";
VAL_ 262 MCUR_HVIL_DCB_St 0 "MCUR_HVIL_DCB_St_0_Not_ready" 1 "MCUR_HVIL_DCB_St_1_Lock" 2 "MCUR_HVIL_DCB_St_2_Unlock" 3 "MCUR_HVIL_DCB_St_3_HW_Fault";
VAL_ 262 MCUR_IGBTmode 0 "MCUR_IGBTmode_0_PWM_off" 1 "MCUR_IGBTmode_1_PWM_on" 2 "MCUR_IGBTmode_2_ASC" 3 "MCUR_IGBTmode_3_invalid";
VAL_ 262 MCUR_IGBTOverTempWarn 0 "MCUR_IGBTOverTempWarn_0_No_Warning" 1 "MCUR_IGBTOverTempWarn_1_Warning";
VAL_ 262 MCUR_IGBTTempA 255 "MCUR_IGBTTempA_255_Invalid";
VAL_ 262 MCUR_IGBTTempB 255 "MCUR_IGBTTempB_255_Invalid";
VAL_ 262 MCUR_IGBTTempC 255 "MCUR_IGBTTempC_255_Invalid";
VAL_ 262 MCUR_MaxOutputDriveTq 65535 "MCUR_MaxOutputDriveTq_65535_Invalid";
VAL_ 262 MCUR_MaxOutputRegenTq 65535 "MCUR_MaxOutputRegenTq_65535_Invalid";
VAL_ 262 MCUR_MotOverTempWarn 0 "MCUR_MotOverTempWarn_0_No_Warning" 1 "MCUR_MotOverTempWarn_1_Warning";
VAL_ 262 MCUR_MotTemp 255 "MCUR_MotTemp_255_Invalid";
VAL_ 262 MCUR_MotWorkState 0 "MCUR_MotWorkState_0_Init" 1 "MCUR_MotWorkState_1_Electric_state" 2 "MCUR_MotWorkState_2_Power_generation_status" 3 "MCUR_MotWorkState_3_Freewheeling" 4 "MCUR_MotWorkState_4_Ready" 5 "MCUR_MotWorkState_5_Fault" 15 "MCUR_MotWorkState_15_Invalid";
VAL_ 262 MCUR_OperMod 0 "MCUR_OperMod_0_Init" 1 "MCUR_OperMod_1_LvStandby" 2 "MCUR_OperMod_2_HvStandby" 3 "MCUR_OperMod_3_Torque_Control" 4 "MCUR_OperMod_4_Speed_Mode" 5 "MCUR_OperMod_5_Resolver_Self-calibration" 6 "MCUR_OperMod_6_Fault" 7 "MCUR_OperMod_7_Sleep" 8 "MCUR_OperMod_8_DisCharge" 9 "MCUR_OperMod_9_SV_Mode" 10 "MCUR_OperMod_10_BoostCharge" 11 "MCUR_OperMod_11_Heating" 12 "MCUR_OperMod_12_Reserved" 13 "MCUR_OperMod_13_SPO" 14 "MCUR_OperMod_14_Reserved";
VAL_ 262 MCUR_RotorTemp 255 "MCUR_RotorTemp_255_Invalid";
VAL_ 262 MCUR_RotSpdMaxLimit 1023 "MCUR_RotSpdMaxLimit_1023_Invalid";
VAL_ 262 MCUR_SpdModAvl 0 "MCUR_SpdModAvl_0_Not_available" 1 "MCUR_SpdModAvl_1_Available";
VAL_ 262 MCUR_SpdSVModFlt 0 "MCUR_SpdSVModFlt_0_No_Fault" 1 "MCUR_SpdSVModFlt_1_Outp_Tq_too_large(abslt_val)" 2 "MCUR_SpdSVModFlt_2_Reserved";
VAL_ 262 MCUR_Standstill 0 "MCUR_Standstill_0_Not_standstill" 1 "MCUR_Standstill_1_Standstill";
VAL_ 262 MCUR_SVModAvl 0 "MCUR_SVModAvl_0_Not_available" 1 "MCUR_SVModAvl_1_Available";
VAL_ 262 MCUR_TarTq 65535 "MCUR_TarTq_65535_Invalid";
VAL_ 262 MCUR_VehSldSt 0 "MCUR_VehSldSt_0_Not_slide" 1 "MCUR_VehSldSt_1_Slide";
